VERSION ""

NS_ :

BS_:

BU_: TESTECU BIANSUXIANG SCR EBSECU DisPlay EngineECU

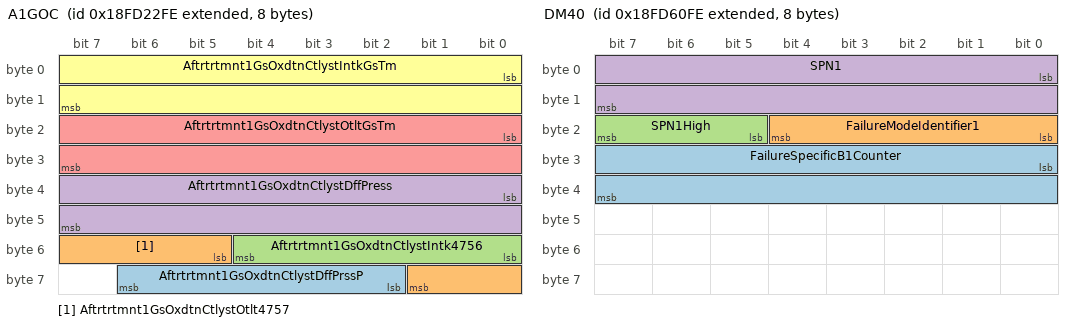
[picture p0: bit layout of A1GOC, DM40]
BO_ 2566726398 A1GOC: 8 Vector__XXX
 SG_ Aftrtrtmnt1GsOxdtnCtlystDffPrssP : 58|5@1+ (1,0) [0|31] "" Vector__XXX
 SG_ Aftrtrtmnt1GsOxdtnCtlystOtlt4757 : 53|5@1+ (1,0) [0|31] "" Vector__XXX
 SG_ Aftrtrtmnt1GsOxdtnCtlystIntk4756 : 48|5@1+ (1,0) [0|31] "" Vector__XXX
 SG_ Aftrtrtmnt1GsOxdtnCtlystDffPress : 32|16@1+ (0.1,0) [0|6425.5] "kPa" Vector__XXX
 SG_ Aftrtrtmnt1GsOxdtnCtlystOtltGsTm : 16|16@1+ (0.03125,-273) [-273|1734.96875] "deg C" Vector__XXX
 SG_ Aftrtrtmnt1GsOxdtnCtlystIntkGsTm : 0|16@1+ (0.03125,-273) [-273|1734.96875] "deg C" Vector__XXX

BO_ 2566742270 DM40: 8 Vector__XXX
 SG_ FailureSpecificB1Counter : 24|16@1+ (0.1,0) [0|6425.5] "hr" Vector__XXX
 SG_ FailureModeIdentifier1 : 16|5@1+ (1,0) [0|0] "" Vector__XXX
 SG_ SPN1High : 21|3@1+ (1,0) [0|7] "" Vector__XXX
 SG_ SPN1 : 0|16@1+ (1,0) [0|65536] "" Vector__XXX

BO_ 2566742526 DM39: 8 Vector__XXX
 SG_ SysGreatestB1Counter : 32|16@1+ (0.1,0) [0|6425.5] "hr" Vector__XXX
 SG_ SysCumulativeContinuousMITime : 0|32@1+ (0.05,0) [0|210554060.75] "hr" Vector__XXX

BO_ 2566742782 DM38: 8 Vector__XXX
 SG_ RegulationDescription : 0|8@1+ (1,0) [0|255] "" Vector__XXX

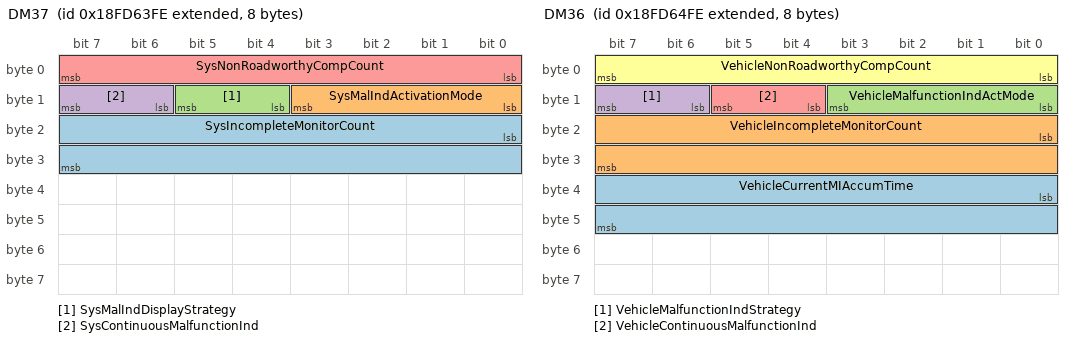
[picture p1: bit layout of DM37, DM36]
BO_ 2566743038 DM37: 8 Vector__XXX
 SG_ SysIncompleteMonitorCount : 16|16@1+ (1,0) [0|64512] "" Vector__XXX
 SG_ SysMalIndActivationMode : 8|4@1+ (1,0) [0|15] "" Vector__XXX
 SG_ SysMalIndDisplayStrategy : 12|2@1+ (1,0) [0|3] "" Vector__XXX
 SG_ SysContinuousMalfunctionInd : 14|2@1+ (1,0) [0|3] "" Vector__XXX
 SG_ SysNonRoadworthyCompCount : 0|8@1+ (1,0) [0|250] "" Vector__XXX

BO_ 2566743294 DM36: 8 Vector__XXX
 SG_ VehicleCurrentMIAccumTime : 32|16@1+ (1,0) [0|64255] "min" Vector__XXX
 SG_ VehicleIncompleteMonitorCount : 16|16@1+ (1,0) [0|64255] "" Vector__XXX
 SG_ VehicleMalfunctionIndActMode : 8|4@1+ (1,0) [0|15] "" Vector__XXX
 SG_ VehicleMalfunctionIndStrategy : 14|2@1+ (1,0) [0|3] "" Vector__XXX
 SG_ VehicleContinuousMalfunctionInd : 12|2@1+ (1,0) [0|3] "" Vector__XXX
 SG_ VehicleNonRoadworthyCompCount : 0|8@1+ (1,0) [0|250] "" Vector__XXX

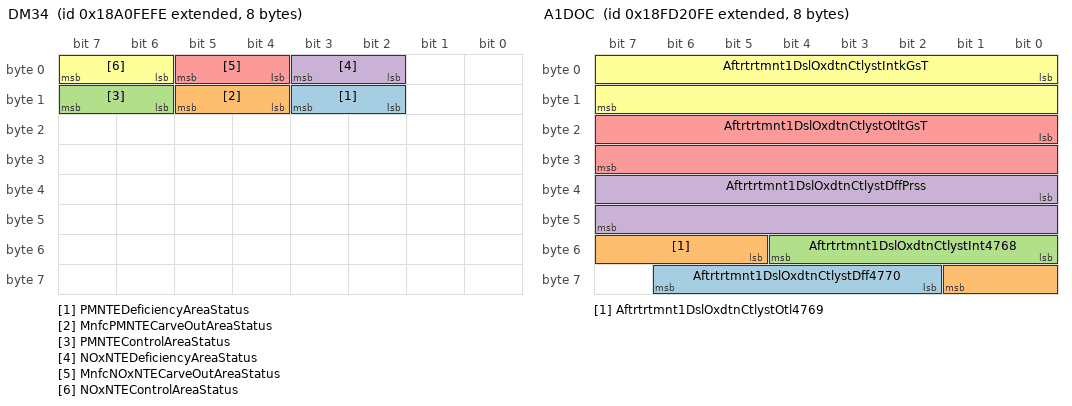
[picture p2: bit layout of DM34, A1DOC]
BO_ 2560687870 DM34: 8 Vector__XXX
 SG_ PMNTEDeficiencyAreaStatus : 10|2@1+ (1,0) [0|3] "" Vector__XXX
 SG_ MnfcPMNTECarveOutAreaStatus : 12|2@1+ (1,0) [0|3] "" Vector__XXX
 SG_ PMNTEControlAreaStatus : 14|2@1+ (1,0) [0|3] "" Vector__XXX
 SG_ NOxNTEDeficiencyAreaStatus : 2|2@1+ (1,0) [0|3] "" Vector__XXX
 SG_ MnfcNOxNTECarveOutAreaStatus : 4|2@1+ (1,0) [0|3] "" Vector__XXX
 SG_ NOxNTEControlAreaStatus : 6|2@1+ (1,0) [0|3] "" Vector__XXX

BO_ 2292317950 DM33: 9 Vector__XXX
 SG_ AECDEngineHours1Timer2 : 40|32@1+ (1,0) [0|4294967295] "min" Vector__XXX
 SG_ AECDEngineHours1Timer1 : 8|32@1+ (1,0) [0|4294967295] "min" Vector__XXX
 SG_ AECDNumber1 : 0|8@1+ (1,0) [0|250] "" Vector__XXX

BO_ 2566809342 BM: 8 Vector__XXX
 SG_ BatteryMainSwitchHoldState : 0|2@1+ (1,0) [0|3] "" Vector__XXX

BO_ 2365446910 BJM3: 8 Vector__XXX
 SG_ Joystick3XAxisDetentPosStatus : 38|2@1+ (1,0) [0|3] "" Vector__XXX
 SG_ Joystick3Button9PressedStatus : 62|2@1+ (1,0) [0|3] "" Vector__XXX
 SG_ Joystick3Button10PressedStatus : 60|2@1+ (1,0) [0|3] "" Vector__XXX
 SG_ Joystick3Button11PressedStatus : 58|2@1+ (1,0) [0|3] "" Vector__XXX
 SG_ Joystick3Button12PressedStatus : 56|2@1+ (1,0) [0|3] "" Vector__XXX
 SG_ Joystick3YAxisDetentPosStatus : 36|2@1+ (1,0) [0|3] "" Vector__XXX
 SG_ Joystick3YAxisPos : 22|10@1+ (0.1,0) [0|102] "%" Vector__XXX
 SG_ Jystck3YAxsLvrFrwrdPstvPosStatus : 20|2@1+ (1,0) [0|3] "" Vector__XXX
 SG_ Jystck3YAxsLvrBckNgtivePosStatus : 18|2@1+ (1,0) [0|3] "" Vector__XXX
 SG_ Joystick3YAxisNeutralPosStatus : 16|2@1+ (1,0) [0|3] "" Vector__XXX
 SG_ Joystick3XAxisPos : 6|10@1+ (0.1,0) [0|102] "%" Vector__XXX
 SG_ Jystck3XAxsLvrRghtPstvePosStatus : 4|2@1+ (1,0) [0|3] "" Vector__XXX
 SG_ Jystck3XAxsLvrLftNgtivePosStatus : 2|2@1+ (1,0) [0|3] "" Vector__XXX
 SG_ Joystick3XAxisNeutralPosStatus : 0|2@1+ (1,0) [0|3] "" Vector__XXX
 SG_ Joystick3Button5PressedStatus : 54|2@1+ (1,0) [0|3] "" Vector__XXX
 SG_ Joystick3Button6PressedStatus : 52|2@1+ (1,0) [0|3] "" Vector__XXX
 SG_ Joystick3Button7PressedStatus : 50|2@1+ (1,0) [0|3] "" Vector__XXX
 SG_ Joystick3Button8PressedStatus : 48|2@1+ (1,0) [0|3] "" Vector__XXX
 SG_ Joystick3Button1PressedStatus : 46|2@1+ (1,0) [0|3] "" Vector__XXX
 SG_ Joystick3Button2PressedStatus : 44|2@1+ (1,0) [0|3] "" Vector__XXX
 SG_ Joystick3Button3PressedStatus : 42|2@1+ (1,0) [0|3] "" Vector__XXX
 SG_ Joystick3Button4PressedStatus : 40|2@1+ (1,0) [0|3] "" Vector__XXX

BO_ 2365446398 BJM2: 8 Vector__XXX
 SG_ Joystick2XAxisDetentPosStatus : 38|2@1+ (1,0) [0|3] "" Vector__XXX
 SG_ Joystick2YAxisDetentPosStatus : 36|2@1+ (1,0) [0|3] "" Vector__XXX
 SG_ Joystick2YAxisPos : 22|10@1+ (0.1,0) [0|102] "%" Vector__XXX
 SG_ Jystck2YAxsLvrFrwrdPstvPosStatus : 20|2@1+ (1,0) [0|3] "" Vector__XXX
 SG_ Jystck2YAxsLvrBckNgtivePosStatus : 18|2@1+ (1,0) [0|3] "" Vector__XXX
 SG_ Joystick2YAxisNeutralPosStatus : 16|2@1+ (1,0) [0|3] "" Vector__XXX
 SG_ Joystick2XAxisPos : 6|10@1+ (0.1,0) [0|102] "%" Vector__XXX
 SG_ Jystck2XAxsLvrRghtPstvePosStatus : 4|2@1+ (1,0) [0|3] "" Vector__XXX
 SG_ Jystck2XAxsLvrLftNgtivePosStatus : 2|2@1+ (1,0) [0|3] "" Vector__XXX
 SG_ Joystick2XAxisNeutralPosStatus : 0|2@1+ (1,0) [0|3] "" Vector__XXX
 SG_ Joystick2Button9PressedStatus : 62|2@1+ (1,0) [0|3] "" Vector__XXX
 SG_ Joystick2Button10PressedStatus : 60|2@1+ (1,0) [0|3] "" Vector__XXX
 SG_ Joystick2Button11PressedStatus : 58|2@1+ (1,0) [0|3] "" Vector__XXX
 SG_ Joystick2Button12PressedStatus : 56|2@1+ (1,0) [0|3] "" Vector__XXX
 SG_ Joystick2Button5PressedStatus : 54|2@1+ (1,0) [0|3] "" Vector__XXX
 SG_ Joystick2Button6PressedStatus : 52|2@1+ (1,0) [0|3] "" Vector__XXX
 SG_ Joystick2Button7PressedStatus : 50|2@1+ (1,0) [0|3] "" Vector__XXX
 SG_ Joystick2Button8PressedStatus : 48|2@1+ (1,0) [0|3] "" Vector__XXX
 SG_ Joystick2Button1PressedStatus : 46|2@1+ (1,0) [0|3] "" Vector__XXX
 SG_ Joystick2Button2PressedStatus : 44|2@1+ (1,0) [0|3] "" Vector__XXX
 SG_ Joystick2Button3PressedStatus : 42|2@1+ (1,0) [0|3] "" Vector__XXX
 SG_ Joystick2Button4PressedStatus : 40|2@1+ (1,0) [0|3] "" Vector__XXX

BO_ 2365445886 BJM1: 8 Vector__XXX
 SG_ Joystick1XAxisDetentPosStatus : 38|2@1+ (1,0) [0|3] "" Vector__XXX
 SG_ Joystick1YAxisDetentPosStatus : 36|2@1+ (1,0) [0|3] "" Vector__XXX
 SG_ Joystick1YAxisPos : 22|10@1+ (0.1,0) [0|102] "%" Vector__XXX
 SG_ Jystck1YAxsLvrFrwrdPstvPosStatus : 20|2@1+ (1,0) [0|3] "" Vector__XXX
 SG_ Jystck1YAxsLvrBckNgtivePosStatus : 18|2@1+ (1,0) [0|3] "" Vector__XXX
 SG_ Joystick1YAxisNeutralPosStatus : 16|2@1+ (1,0) [0|3] "" Vector__XXX
 SG_ Joystick1XAxisPos : 6|10@1+ (0.1,0) [0|102] "%" Vector__XXX
 SG_ Joystick1Button9PressedStatus : 62|2@1+ (1,0) [0|3] "" Vector__XXX
 SG_ Joystick1Button10PressedStatus : 60|2@1+ (1,0) [0|3] "" Vector__XXX
 SG_ Joystick1Button11PressedStatus : 58|2@1+ (1,0) [0|3] "" Vector__XXX
 SG_ Joystick1Button12PressedStatus : 56|2@1+ (1,0) [0|3] "" Vector__XXX
 SG_ Joystick1Button5PressedStatus : 54|2@1+ (1,0) [0|3] "" Vector__XXX
 SG_ Joystick1Button6PressedStatus : 52|2@1+ (1,0) [0|3] "" Vector__XXX
 SG_ Joystick1Button7PressedStatus : 50|2@1+ (1,0) [0|3] "" Vector__XXX
 SG_ Joystick1Button8PressedStatus : 48|2@1+ (1,0) [0|3] "" Vector__XXX
 SG_ Joystick1Button1PressedStatus : 46|2@1+ (1,0) [0|3] "" Vector__XXX
 SG_ Joystick1Button2PressedStatus : 44|2@1+ (1,0) [0|3] "" Vector__XXX
 SG_ Joystick1Button3PressedStatus : 42|2@1+ (1,0) [0|3] "" Vector__XXX
 SG_ Joystick1Button4PressedStatus : 40|2@1+ (1,0) [0|3] "" Vector__XXX
 SG_ Jystck1XAxsLvrRghtPstvePosStatus : 4|2@1+ (1,0) [0|3] "" Vector__XXX
 SG_ Jystck1XAxsLvrLftNgtivePosStatus : 2|2@1+ (1,0) [0|3] "" Vector__XXX
 SG_ Joystick1XAxisNeutralPosStatus : 0|2@1+ (1,0) [0|3] "" Vector__XXX

BO_ 2566847230 B: 8 Vector__XXX
 SG_ ParkingBrakeRedWarningSignal : 26|2@1+ (1,0) [0|3] "" Vector__XXX
 SG_ ParkBrakeReleaseInhibitStatus : 28|2@1+ (1,0) [0|3] "" Vector__XXX
 SG_ ParkingBrakeActuator : 24|2@1+ (1,0) [0|3] "" Vector__XXX
 SG_ BrakeSecondPress : 16|8@1+ (4,0) [0|1000] "kPa" Vector__XXX
 SG_ BrakePrimaryPress : 8|8@1+ (4,0) [0|1000] "kPa" Vector__XXX
 SG_ BrakeAppPress : 0|8@1+ (4,0) [0|1000] "kPa" Vector__XXX

BO_ 2566848254 AWPP: 8 Vector__XXX
 SG_ AuxPumpPress : 0|8@1+ (16,0) [0|4000] "kPa" Vector__XXX

BO_ 2566725886 A1DOC: 8 Vector__XXX
 SG_ Aftrtrtmnt1DslOxdtnCtlystDff4770 : 58|5@1+ (1,0) [0|31] "" Vector__XXX
 SG_ Aftrtrtmnt1DslOxdtnCtlystOtl4769 : 53|5@1+ (1,0) [0|31] "" Vector__XXX
 SG_ Aftrtrtmnt1DslOxdtnCtlystInt4768 : 48|5@1+ (1,0) [0|31] "" Vector__XXX
 SG_ Aftrtrtmnt1DslOxdtnCtlystDffPrss : 32|16@1+ (0.1,0) [0|6425.5] "kPa" Vector__XXX
 SG_ Aftrtrtmnt1DslOxdtnCtlystOtltGsT : 16|16@1+ (0.03125,-273) [-273|1734.96875] "deg C" Vector__XXX
 SG_ Aftrtrtmnt1DslOxdtnCtlystIntkGsT : 0|16@1+ (0.03125,-273) [-273|1734.96875] "deg C" Vector__XXX

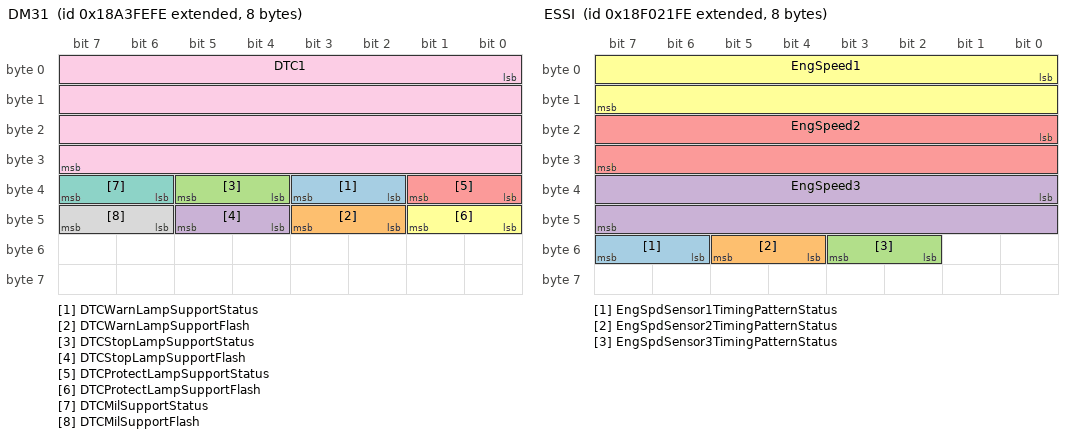
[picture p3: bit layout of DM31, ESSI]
BO_ 2560884478 DM31: 8 Vector__XXX
 SG_ DTCWarnLampSupportStatus : 34|2@1+ (1,0) [0|3] "" Vector__XXX
 SG_ DTCWarnLampSupportFlash : 42|2@1+ (1,0) [0|3] "" Vector__XXX
 SG_ DTCStopLampSupportStatus : 36|2@1+ (1,0) [0|3] "" Vector__XXX
 SG_ DTCStopLampSupportFlash : 44|2@1+ (1,0) [0|3] "" Vector__XXX
 SG_ DTCProtectLampSupportStatus : 32|2@1+ (1,0) [0|3] "" Vector__XXX
 SG_ DTCProtectLampSupportFlash : 40|2@1+ (1,0) [0|3] "" Vector__XXX
 SG_ DTCMilSupportStatus : 38|2@1+ (1,0) [0|3] "" Vector__XXX
 SG_ DTCMilSupportFlash : 46|2@1+ (1,0) [0|3] "" Vector__XXX
 SG_ DTC1 : 0|32@1+ (1,0) [0|4294967295] "" Vector__XXX

BO_ 2633844734 TML: 8 Vector__XXX

BO_ 2560360190 PMI: 8 Vector__XXX
 SG_ DataDictionaryMethod : 11|21@1+ (1,0) [0|2097151] "" Vector__XXX
 SG_ DataDictionaryManufacturerCode : 0|11@1+ (1,0) [0|2047] "" Vector__XXX

BO_ 2566736126 O2FT2: 8 Vector__XXX
 SG_ EngExhstGsOxygnSnsrClsdLpOprtnBn : 32|4@1+ (1,0) [0|15] "" Vector__XXX
 SG_ ShorttermFuelTrimBank2 : 16|16@1+ (0.1,-100) [-100|100] "%" Vector__XXX
 SG_ LongtermFuelTrimBank2 : 0|16@1+ (0.1,-100) [-100|100] "%" Vector__XXX

BO_ 2566736382 O2FT1: 8 Vector__XXX
 SG_ EngExhstGsOxygnSnsrClsdLpOprtnBn : 32|4@1+ (1,0) [0|15] "" Vector__XXX
 SG_ ShorttermFuelTrimBank1 : 16|16@1+ (0.1,-100) [-100|100] "%" Vector__XXX
 SG_ LongtermFuelTrimBank1 : 0|16@1+ (0.1,-100) [-100|100] "%" Vector__XXX

BO_ 2565874174 ESSI: 8 Vector__XXX
 SG_ EngSpdSensor1TimingPatternStatus : 54|2@1+ (1,0) [0|3] "" Vector__XXX
 SG_ EngSpdSensor2TimingPatternStatus : 52|2@1+ (1,0) [0|3] "" Vector__XXX
 SG_ EngSpdSensor3TimingPatternStatus : 50|2@1+ (1,0) [0|3] "" Vector__XXX
 SG_ EngSpeed3 : 32|16@1+ (0.5,0) [0|32127.5] "rpm" Vector__XXX
 SG_ EngSpeed2 : 16|16@1+ (0.5,0) [0|32127.5] "rpm" Vector__XXX
 SG_ EngSpeed1 : 0|16@1+ (0.5,0) [0|32127.5] "rpm" Vector__XXX

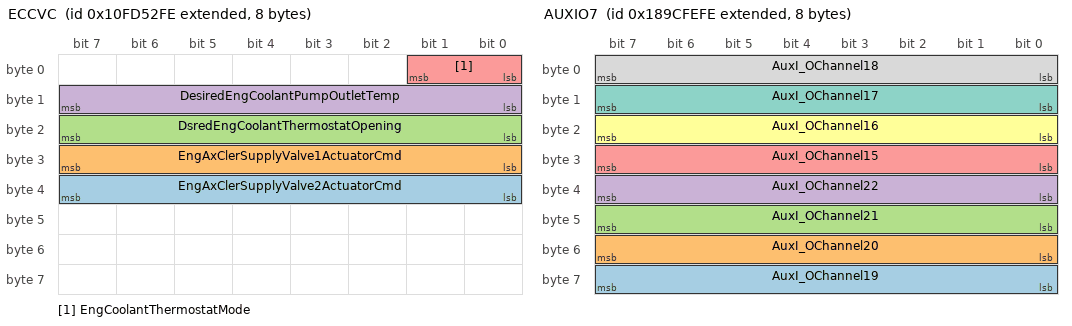
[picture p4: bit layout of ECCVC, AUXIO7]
BO_ 2432520958 ECCVC: 8 Vector__XXX
 SG_ EngAxClerSupplyValve2ActuatorCmd : 32|8@1+ (0.4,0) [0|100] "%" Vector__XXX
 SG_ EngAxClerSupplyValve1ActuatorCmd : 24|8@1+ (0.4,0) [0|100] "%" Vector__XXX
 SG_ DsredEngCoolantThermostatOpening : 16|8@1+ (0.4,0) [0|100] "%" Vector__XXX
 SG_ DesiredEngCoolantPumpOutletTemp : 8|8@1+ (1,-40) [-40|210] "deg C" Vector__XXX
 SG_ EngCoolantThermostatMode : 0|2@1+ (1,0) [0|3] "" Vector__XXX

BO_ 2560425726 AUXIO7: 8 Vector__XXX
 SG_ AuxI_OChannel19 : 56|8@1+ (1,0) [0|250] "" Vector__XXX
 SG_ AuxI_OChannel20 : 48|8@1+ (1,0) [0|250] "" Vector__XXX
 SG_ AuxI_OChannel21 : 40|8@1+ (1,0) [0|250] "" Vector__XXX
 SG_ AuxI_OChannel22 : 32|8@1+ (1,0) [0|250] "" Vector__XXX
 SG_ AuxI_OChannel15 : 24|8@1+ (1,0) [0|250] "" Vector__XXX
 SG_ AuxI_OChannel16 : 16|8@1+ (1,0) [0|250] "" Vector__XXX
 SG_ AuxI_OChannel17 : 8|8@1+ (1,0) [0|250] "" Vector__XXX
 SG_ AuxI_OChannel18 : 0|8@1+ (1,0) [0|250] "" Vector__XXX

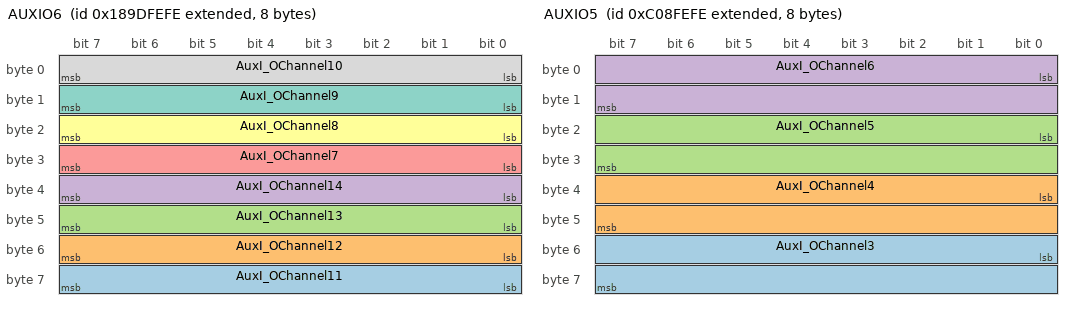
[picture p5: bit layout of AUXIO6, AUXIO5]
BO_ 2560491262 AUXIO6: 8 Vector__XXX
 SG_ AuxI_OChannel11 : 56|8@1+ (1,0) [0|250] "" Vector__XXX
 SG_ AuxI_OChannel12 : 48|8@1+ (1,0) [0|250] "" Vector__XXX
 SG_ AuxI_OChannel13 : 40|8@1+ (1,0) [0|250] "" Vector__XXX
 SG_ AuxI_OChannel14 : 32|8@1+ (1,0) [0|250] "" Vector__XXX
 SG_ AuxI_OChannel7 : 24|8@1+ (1,0) [0|250] "" Vector__XXX
 SG_ AuxI_OChannel8 : 16|8@1+ (1,0) [0|250] "" Vector__XXX
 SG_ AuxI_OChannel9 : 8|8@1+ (1,0) [0|250] "" Vector__XXX
 SG_ AuxI_OChannel10 : 0|8@1+ (1,0) [0|250] "" Vector__XXX

BO_ 2349399806 AUXIO5: 8 Vector__XXX
 SG_ AuxI_OChannel3 : 48|16@1+ (1,0) [0|64255] "" Vector__XXX
 SG_ AuxI_OChannel4 : 32|16@1+ (1,0) [0|64255] "" Vector__XXX
 SG_ AuxI_OChannel5 : 16|16@1+ (1,0) [0|64255] "" Vector__XXX
 SG_ AuxI_OChannel6 : 0|16@1+ (1,0) [0|64255] "" Vector__XXX

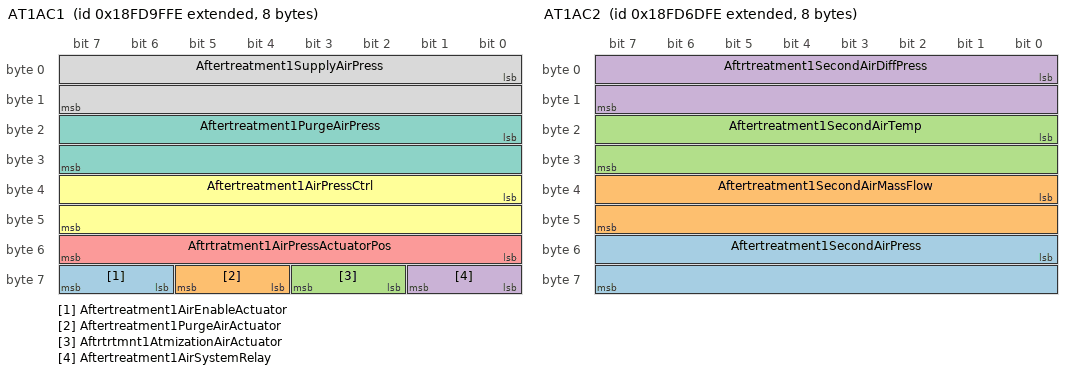
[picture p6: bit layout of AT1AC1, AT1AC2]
BO_ 2566758398 AT1AC1: 8 Vector__XXX
 SG_ Aftertreatment1AirEnableActuator : 62|2@1+ (1,0) [0|3] "" Vector__XXX
 SG_ Aftertreatment1PurgeAirActuator : 60|2@1+ (1,0) [0|3] "" Vector__XXX
 SG_ Aftrtrtmnt1AtmizationAirActuator : 58|2@1+ (1,0) [0|3] "" Vector__XXX
 SG_ Aftertreatment1AirSystemRelay : 56|2@1+ (1,0) [0|3] "" Vector__XXX
 SG_ Aftrtratment1AirPressActuatorPos : 48|8@1+ (0.4,0) [0|100] "%" Vector__XXX
 SG_ Aftertreatment1AirPressCtrl : 32|16@1+ (0.0025,0) [0|160.6375] "%" Vector__XXX
 SG_ Aftertreatment1PurgeAirPress : 16|16@1+ (0.1,0) [0|6425.5] "kPa" Vector__XXX
 SG_ Aftertreatment1SupplyAirPress : 0|16@1+ (0.1,0) [0|6425.5] "kPa" Vector__XXX

BO_ 2566745598 AT1AC2: 8 Vector__XXX
 SG_ Aftertreatment1SecondAirPress : 48|16@1+ (0.1,0) [0|6425.5] "kPa" Vector__XXX
 SG_ Aftertreatment1SecondAirMassFlow : 32|16@1+ (0.2,0) [0|12851] "kg/h per bit" Vector__XXX
 SG_ Aftertreatment1SecondAirTemp : 16|16@1+ (0.03125,-273) [-273|1734.96875] "deg C" Vector__XXX
 SG_ Aftrtreatment1SecondAirDiffPress : 0|16@1+ (0.0078125,-250) [-250|251.99] "kPa" Vector__XXX

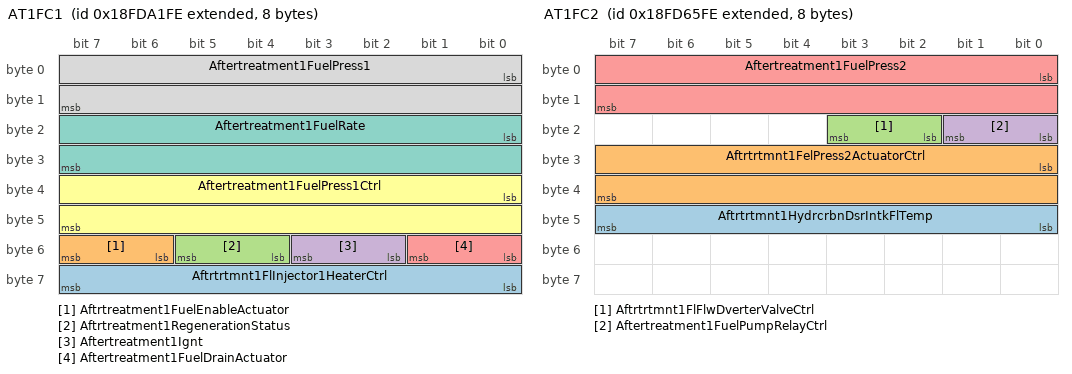
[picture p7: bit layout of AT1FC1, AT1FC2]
BO_ 2566758910 AT1FC1: 8 Vector__XXX
 SG_ Aftrtrtmnt1FlInjector1HeaterCtrl : 56|8@1+ (0.4,0) [0|100] "%" Vector__XXX
 SG_ Aftrtreatment1FuelEnableActuator : 54|2@1+ (1,0) [0|3] "" Vector__XXX
 SG_ Aftrtreatment1RegenerationStatus : 52|2@1+ (1,0) [0|3] "" Vector__XXX
 SG_ Aftertreatment1Ignt : 50|2@1+ (1,0) [0|3] "" Vector__XXX
 SG_ Aftertreatment1FuelDrainActuator : 48|2@1+ (1,0) [0|3] "" Vector__XXX
 SG_ Aftertreatment1FuelPress1Ctrl : 32|16@1+ (0.0025,0) [0|160.6375] "%" Vector__XXX
 SG_ Aftertreatment1FuelRate : 16|16@1+ (0.05,0) [0|3212.75] "L/h" Vector__XXX
 SG_ Aftertreatment1FuelPress1 : 0|16@1+ (0.1,0) [0|6425.5] "kPa" Vector__XXX

BO_ 2566743550 AT1FC2: 8 Vector__XXX
 SG_ Aftrtrtmnt1HydrcrbnDsrIntkFlTemp : 40|8@1+ (1,-40) [-40|210] "deg C" Vector__XXX
 SG_ Aftrtrtmnt1FelPress2ActuatorCtrl : 24|16@1+ (0.0025,0) [0|160.6375] "%" Vector__XXX
 SG_ Aftrtrtmnt1FlFlwDverterValveCtrl : 18|2@1+ (1,0) [0|3] "" Vector__XXX
 SG_ Aftertreatment1FuelPumpRelayCtrl : 16|2@1+ (1,0) [0|3] "" Vector__XXX
 SG_ Aftertreatment1FuelPress2 : 0|16@1+ (0.1,0) [0|6425.5] "kPa" Vector__XXX

BO_ 2566753534 AT1GP: 8 Vector__XXX
 SG_ DslParticulateFilterOutletPress1 : 16|16@1+ (0.1,0) [0|6425.5] "kPa" Vector__XXX
 SG_ DslParticulateFilterIntakePress1 : 0|16@1+ (0.1,0) [0|6425.5] "kPa" Vector__XXX

BO_ 2566756606 AT1HI: 8 Vector__XXX
 SG_ Aftrtrtmnt1AvrgDstncBtwnActvDPFR : 288|32@1+ (0.125,0) [0|526385151.9] "km" Vector__XXX
 SG_ Aftrtrtmnt1AvrgTmBtwnActvRgnrtns : 256|32@1+ (1,0) [0|4211081215] "s" Vector__XXX
 SG_ Aftrtrtmnt1DslPrtcltFltrTtlN3728 : 224|32@1+ (1,0) [0|4211081215] "" Vector__XXX
 SG_ Aftrtrtmnt1DslPrtcltFltrTtlN3727 : 192|32@1+ (1,0) [0|4211081215] "" Vector__XXX
 SG_ Aftrtrtmnt1DslPrtcltFltrTtlNmbrO : 160|32@1+ (1,0) [0|4211081215] "" Vector__XXX
 SG_ Aftrtrtmnt1DslPrtcltFltrTtlPssvR : 128|32@1+ (1,0) [0|4211081215] "s" Vector__XXX
 SG_ Aftrtrtmnt1TtlNmbrOfActvRgnrtons : 96|32@1+ (1,0) [0|4211081215] "" Vector__XXX
 SG_ Aftertreatment1TotalDisabledTime : 64|32@1+ (1,0) [0|4211081215] "s" Vector__XXX
 SG_ Aftrtrtmnt1TotalRegenerationTime : 32|32@1+ (1,0) [0|4211081215] "s" Vector__XXX
 SG_ Aftertreatment1TotalFuelUsed : 0|32@1+ (0.5,0) [0|2105540607.5] "L" Vector__XXX

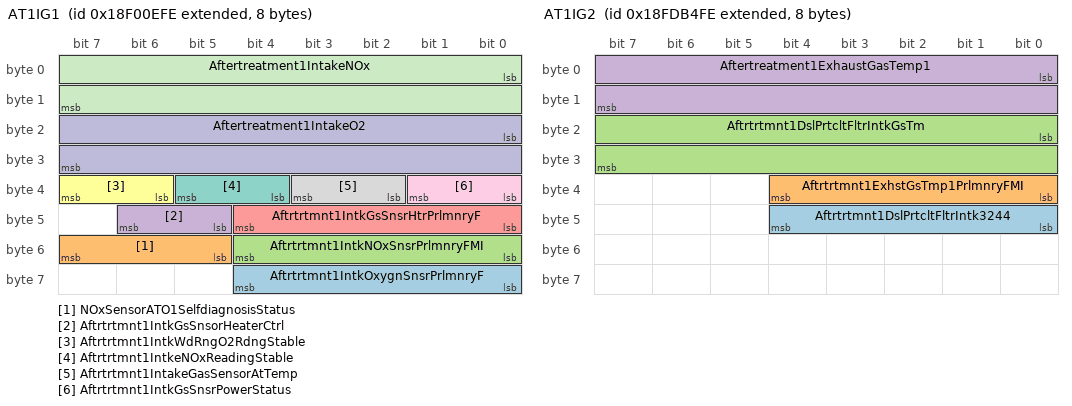
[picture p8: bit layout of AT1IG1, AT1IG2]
BO_ 2565869310 AT1IG1: 8 Vector__XXX
 SG_ Aftrtrtmnt1IntkOxygnSnsrPrlmnryF : 56|5@1+ (1,0) [0|31] "" Vector__XXX
 SG_ NOxSensorATO1SelfdiagnosisStatus : 53|3@1+ (1,0) [0|7] "" Vector__XXX
 SG_ Aftrtrtmnt1IntkNOxSnsrPrlmnryFMI : 48|5@1+ (1,0) [0|31] "" Vector__XXX
 SG_ Aftrtrtmnt1IntkGsSnsorHeaterCtrl : 45|2@1+ (1,0) [0|3] "" Vector__XXX
 SG_ Aftrtrtmnt1IntkGsSnsrHtrPrlmnryF : 40|5@1+ (1,0) [0|31] "" Vector__XXX
 SG_ Aftrtrtmnt1IntkWdRngO2RdngStable : 38|2@1+ (1,0) [0|3] "" Vector__XXX
 SG_ Aftrtrtmnt1IntkeNOxReadingStable : 36|2@1+ (1,0) [0|3] "" Vector__XXX
 SG_ Aftrtrtmnt1IntakeGasSensorAtTemp : 34|2@1+ (1,0) [0|3] "" Vector__XXX
 SG_ Aftrtrtmnt1IntkGsSnsrPowerStatus : 32|2@1+ (1,0) [0|3] "" Vector__XXX
 SG_ Aftertreatment1IntakeO2 : 16|16@1+ (0.000514,-12) [-12|21] "%" Vector__XXX
 SG_ Aftertreatment1IntakeNOx : 0|16@1+ (0.05,-200) [-200|3012.75] "ppm" Vector__XXX

BO_ 2566763774 AT1IG2: 8 Vector__XXX
 SG_ Aftrtrtmnt1DslPrtcltFltrIntk3244 : 40|5@1+ (1,0) [0|31] "" Vector__XXX
 SG_ Aftrtrtmnt1ExhstGsTmp1PrlmnryFMI : 32|5@1+ (1,0) [0|31] "" Vector__XXX
 SG_ Aftrtrtmnt1DslPrtcltFltrIntkGsTm : 16|16@1+ (0.03125,-273) [-273|1734.96875] "deg C" Vector__XXX
 SG_ Aftertreatment1ExhaustGasTemp1 : 0|16@1+ (0.03125,-273) [-273|1734.96875] "deg C" Vector__XXX

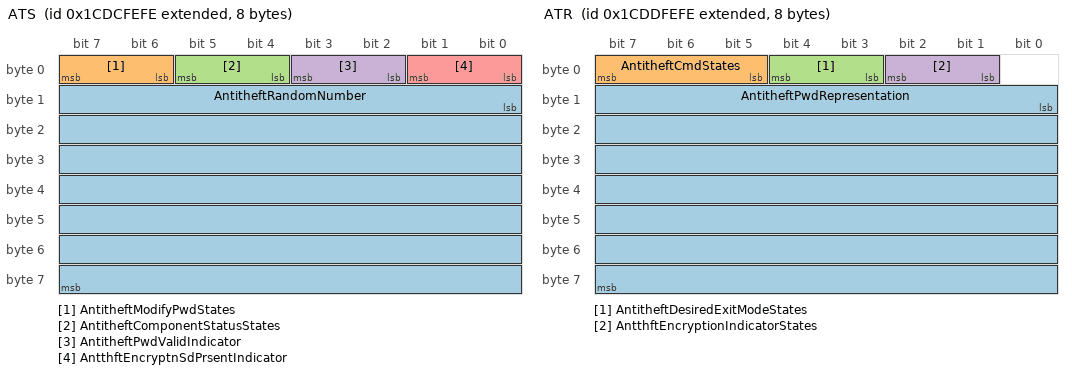
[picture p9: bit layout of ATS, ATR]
BO_ 2631728894 ATS: 8 Vector__XXX
 SG_ AntitheftRandomNumber : 8|56@1+ (1,0) [0|255] "per byte" Vector__XXX
 SG_ AntitheftModifyPwdStates : 6|2@1+ (1,0) [0|3] "" Vector__XXX
 SG_ AntitheftComponentStatusStates : 4|2@1+ (1,0) [0|3] "" Vector__XXX
 SG_ AntitheftPwdValidIndicator : 2|2@1+ (1,0) [0|3] "" Vector__XXX
 SG_ AntthftEncryptnSdPrsentIndicator : 0|2@1+ (1,0) [0|3] "" Vector__XXX

BO_ 2631794430 ATR: 8 Vector__XXX
 SG_ AntitheftPwdRepresentation : 8|56@1+ (1,0) [0|255] "per byte" Vector__XXX
 SG_ AntitheftCmdStates : 5|3@1+ (1,0) [0|7] "" Vector__XXX
 SG_ AntitheftDesiredExitModeStates : 3|2@1+ (1,0) [0|3] "" Vector__XXX
 SG_ AntthftEncryptionIndicatorStates : 1|2@1+ (1,0) [0|3] "" Vector__XXX

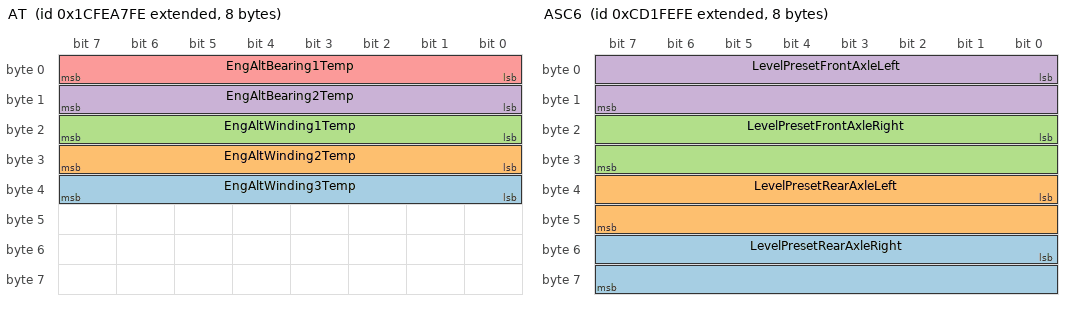
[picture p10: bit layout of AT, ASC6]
BO_ 2633934846 AT: 8 Vector__XXX
 SG_ EngAltWinding3Temp : 32|8@1+ (1,-40) [-40|210] "deg C" Vector__XXX
 SG_ EngAltWinding2Temp : 24|8@1+ (1,-40) [-40|210] "deg C" Vector__XXX
 SG_ EngAltWinding1Temp : 16|8@1+ (1,-40) [-40|210] "deg C" Vector__XXX
 SG_ EngAltBearing2Temp : 8|8@1+ (1,-40) [-40|210] "deg C" Vector__XXX
 SG_ EngAltBearing1Temp : 0|8@1+ (1,-40) [-40|210] "deg C" Vector__XXX

BO_ 2362572542 ASC6: 8 Vector__XXX
 SG_ LevelPresetRearAxleRight : 48|16@1+ (0.1,-3200) [-3200|3225.5] "mm" Vector__XXX
 SG_ LevelPresetRearAxleLeft : 32|16@1+ (0.1,-3200) [-3200|3225.5] "mm" Vector__XXX
 SG_ LevelPresetFrontAxleRight : 16|16@1+ (0.1,-3200) [-3200|3225.5] "mm" Vector__XXX
 SG_ LevelPresetFrontAxleLeft : 0|16@1+ (0.1,-3200) [-3200|3225.5] "mm" Vector__XXX

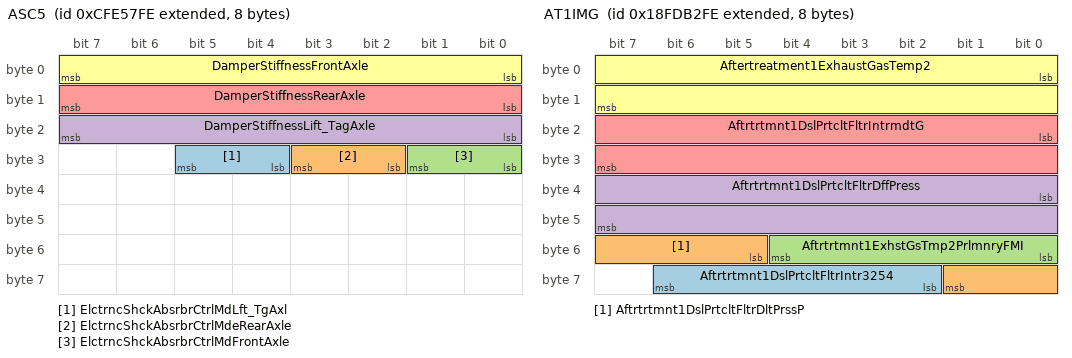
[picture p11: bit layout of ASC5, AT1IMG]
BO_ 2365478910 ASC5: 8 Vector__XXX
 SG_ ElctrncShckAbsrbrCtrlMdLft_TgAxl : 28|2@1+ (1,0) [0|3] "" Vector__XXX
 SG_ ElctrncShckAbsrbrCtrlMdeRearAxle : 26|2@1+ (1,0) [0|3] "" Vector__XXX
 SG_ ElctrncShckAbsrbrCtrlMdFrontAxle : 24|2@1+ (1,0) [0|3] "" Vector__XXX
 SG_ DamperStiffnessLift_TagAxle : 16|8@1+ (0.4,0) [0|100] "%" Vector__XXX
 SG_ DamperStiffnessRearAxle : 8|8@1+ (0.4,0) [0|100] "%" Vector__XXX
 SG_ DamperStiffnessFrontAxle : 0|8@1+ (0.4,0) [0|100] "%" Vector__XXX

BO_ 2560950014 DM30: 12 Vector__XXX
 SG_ TestLimitMinimum : 80|16@1+ (1,0) [0|64255] "" Vector__XXX
 SG_ TestLimitMaximum : 64|16@1+ (1,0) [0|64255] "" Vector__XXX
 SG_ TestValue : 48|16@1+ (1,0) [0|64255] "" Vector__XXX
 SG_ SlotId : 32|16@1+ (1,0) [0|64255] "" Vector__XXX
 SG_ TestIdentifier : 0|8@1+ (1,0) [0|255] "" Vector__XXX
 SG_ FailureModeIdentifier1 : 24|5@1+ (1,0) [0|0] "" Vector__XXX
 SG_ SPN1High : 29|3@1+ (1,0) [0|7] "" Vector__XXX
 SG_ SPN1 : 8|16@1+ (1,0) [0|65536] "" Vector__XXX

BO_ 2566763262 AT1IMG: 8 Vector__XXX
 SG_ Aftrtrtmnt1DslPrtcltFltrIntr3254 : 58|5@1+ (1,0) [0|31] "" Vector__XXX
 SG_ Aftrtrtmnt1DslPrtcltFltrDltPrssP : 53|5@1+ (1,0) [0|31] "" Vector__XXX
 SG_ Aftrtrtmnt1ExhstGsTmp2PrlmnryFMI : 48|5@1+ (1,0) [0|31] "" Vector__XXX
 SG_ Aftrtrtmnt1DslPrtcltFltrDffPress : 32|16@1+ (0.1,0) [0|6425.5] "kPa" Vector__XXX
 SG_ Aftrtrtmnt1DslPrtcltFltrIntrmdtG : 16|16@1+ (0.03125,-273) [-273|1734.96875] "deg C" Vector__XXX
 SG_ Aftertreatment1ExhaustGasTemp2 : 0|16@1+ (0.03125,-273) [-273|1734.96875] "deg C" Vector__XXX

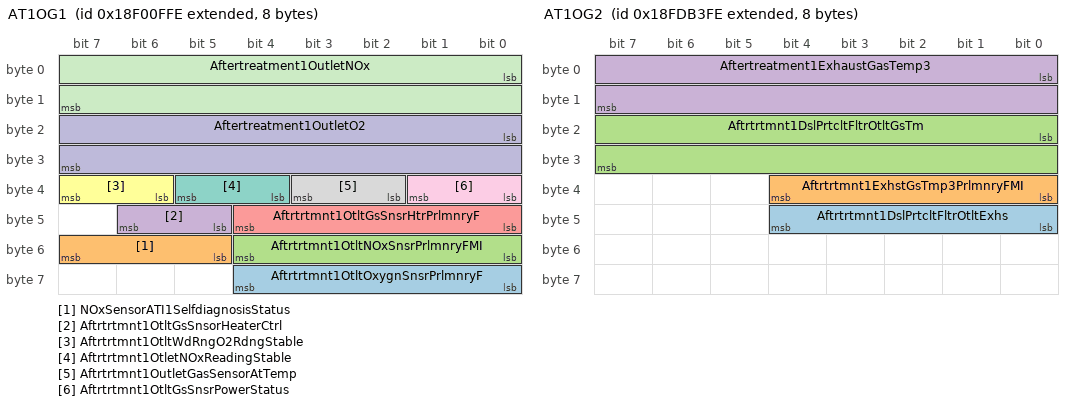
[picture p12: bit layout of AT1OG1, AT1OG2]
BO_ 2565869566 AT1OG1: 8 Vector__XXX
 SG_ Aftrtrtmnt1OtltOxygnSnsrPrlmnryF : 56|5@1+ (1,0) [0|31] "" Vector__XXX
 SG_ NOxSensorATI1SelfdiagnosisStatus : 53|3@1+ (1,0) [0|7] "" Vector__XXX
 SG_ Aftrtrtmnt1OtltNOxSnsrPrlmnryFMI : 48|5@1+ (1,0) [0|31] "" Vector__XXX
 SG_ Aftrtrtmnt1OtltGsSnsorHeaterCtrl : 45|2@1+ (1,0) [0|3] "" Vector__XXX
 SG_ Aftrtrtmnt1OtltGsSnsrHtrPrlmnryF : 40|5@1+ (1,0) [0|31] "" Vector__XXX
 SG_ Aftrtrtmnt1OtltWdRngO2RdngStable : 38|2@1+ (1,0) [0|3] "" Vector__XXX
 SG_ Aftrtrtmnt1OtletNOxReadingStable : 36|2@1+ (1,0) [0|3] "" Vector__XXX
 SG_ Aftrtrtmnt1OutletGasSensorAtTemp : 34|2@1+ (1,0) [0|3] "" Vector__XXX
 SG_ Aftrtrtmnt1OtltGsSnsrPowerStatus : 32|2@1+ (1,0) [0|3] "" Vector__XXX
 SG_ Aftertreatment1OutletO2 : 16|16@1+ (0.000514,-12) [-12|21] "%" Vector__XXX
 SG_ Aftertreatment1OutletNOx : 0|16@1+ (0.05,-200) [-200|3012.75] "ppm" Vector__XXX

BO_ 2566763518 AT1OG2: 8 Vector__XXX
 SG_ Aftrtrtmnt1DslPrtcltFltrOtltExhs : 40|5@1+ (1,0) [0|31] "" Vector__XXX
 SG_ Aftrtrtmnt1ExhstGsTmp3PrlmnryFMI : 32|5@1+ (1,0) [0|31] "" Vector__XXX
 SG_ Aftrtrtmnt1DslPrtcltFltrOtltGsTm : 16|16@1+ (0.03125,-273) [-273|1734.96875] "deg C" Vector__XXX
 SG_ Aftertreatment1ExhaustGasTemp3 : 0|16@1+ (0.03125,-273) [-273|1734.96875] "deg C" Vector__XXX

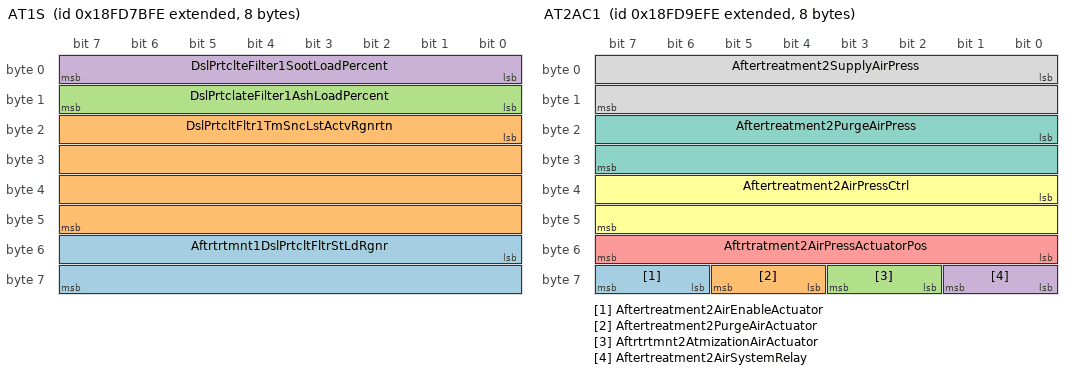
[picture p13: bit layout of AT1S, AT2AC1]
BO_ 2566749182 AT1S: 8 Vector__XXX
 SG_ Aftrtrtmnt1DslPrtcltFltrStLdRgnr : 48|16@1+ (0.0025,0) [0|160.6375] "%" Vector__XXX
 SG_ DslPrtcltFltr1TmSncLstActvRgnrtn : 16|32@1+ (1,0) [0|4211081215] "s" Vector__XXX
 SG_ DslPrtclateFilter1AshLoadPercent : 8|8@1+ (1,0) [0|250] "%" Vector__XXX
 SG_ DslPrtclteFilter1SootLoadPercent : 0|8@1+ (1,0) [0|250] "%" Vector__XXX

BO_ 2566748670 AT1TI: 32 Vector__XXX
 SG_ Aftrtrtmnt1DslPrtcltFltrTrpN3740 : 224|32@1+ (1,0) [0|4211081215] "" Vector__XXX
 SG_ Aftrtrtmnt1DslPrtcltFltrTrpN3739 : 192|32@1+ (1,0) [0|4211081215] "" Vector__XXX
 SG_ Aftrtrtmnt1DslPrtcltFltrTrpN3738 : 160|32@1+ (1,0) [0|4211081215] "" Vector__XXX
 SG_ Aftrtrtmnt1DslPrtcltFltrTrpPssvR : 128|32@1+ (1,0) [0|4211081215] "s" Vector__XXX
 SG_ Aftrtrtmnt1DslPrtcltFltrTrpNmbrO : 96|32@1+ (1,0) [0|4211081215] "" Vector__XXX
 SG_ Aftrtrtmnt1DslPrtcltFltrTrpDsbld : 64|32@1+ (1,0) [0|4211081215] "s" Vector__XXX
 SG_ Aftrtrtmnt1DslPrtcltFltrTrpActvR : 32|32@1+ (1,0) [0|4211081215] "s" Vector__XXX
 SG_ Aftrtrtmnt1DslPrtcltFltrTrpFlUsd : 0|32@1+ (0.5,0) [0|2105540607.5] "L" Vector__XXX

BO_ 2566758142 AT2AC1: 8 Vector__XXX
 SG_ Aftertreatment2AirEnableActuator : 62|2@1+ (1,0) [0|3] "" Vector__XXX
 SG_ Aftertreatment2PurgeAirActuator : 60|2@1+ (1,0) [0|3] "" Vector__XXX
 SG_ Aftrtrtmnt2AtmizationAirActuator : 58|2@1+ (1,0) [0|3] "" Vector__XXX
 SG_ Aftertreatment2AirSystemRelay : 56|2@1+ (1,0) [0|3] "" Vector__XXX
 SG_ Aftrtratment2AirPressActuatorPos : 48|8@1+ (0.4,0) [0|100] "%" Vector__XXX
 SG_ Aftertreatment2AirPressCtrl : 32|16@1+ (0.0025,0) [0|160.6375] "%" Vector__XXX
 SG_ Aftertreatment2PurgeAirPress : 16|16@1+ (0.1,0) [0|6425.5] "kPa" Vector__XXX
 SG_ Aftertreatment2SupplyAirPress : 0|16@1+ (0.1,0) [0|6425.5] "kPa" Vector__XXX

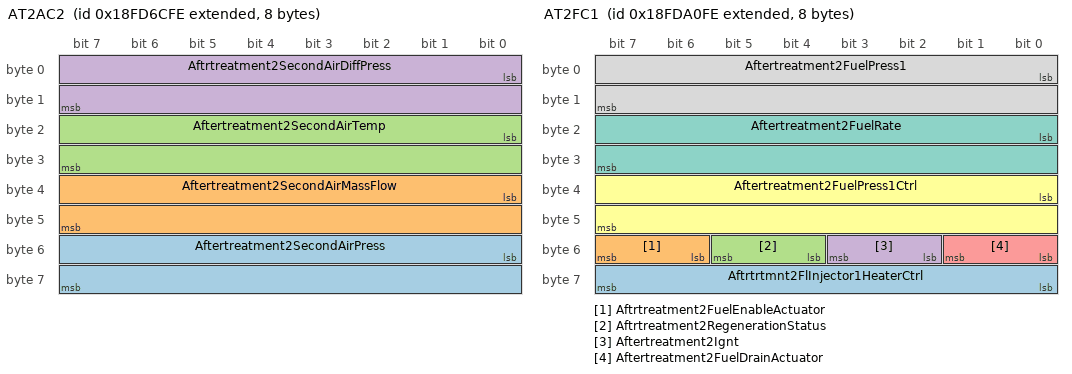
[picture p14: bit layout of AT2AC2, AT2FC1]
BO_ 2566745342 AT2AC2: 8 Vector__XXX
 SG_ Aftertreatment2SecondAirPress : 48|16@1+ (0.1,0) [0|6425.5] "kPa" Vector__XXX
 SG_ Aftertreatment2SecondAirMassFlow : 32|16@1+ (0.2,0) [0|12851] "kg/h per bit" Vector__XXX
 SG_ Aftertreatment2SecondAirTemp : 16|16@1+ (0.03125,-273) [-273|1734.96875] "deg C" Vector__XXX
 SG_ Aftrtreatment2SecondAirDiffPress : 0|16@1+ (0.0078125,-250) [-250|251.99] "kPa" Vector__XXX

BO_ 2566758654 AT2FC1: 8 Vector__XXX
 SG_ Aftrtrtmnt2FlInjector1HeaterCtrl : 56|8@1+ (0.4,0) [0|100] "%" Vector__XXX
 SG_ Aftrtreatment2FuelEnableActuator : 54|2@1+ (1,0) [0|3] "" Vector__XXX
 SG_ Aftrtreatment2RegenerationStatus : 52|2@1+ (1,0) [0|3] "" Vector__XXX
 SG_ Aftertreatment2Ignt : 50|2@1+ (1,0) [0|3] "" Vector__XXX
 SG_ Aftertreatment2FuelDrainActuator : 48|2@1+ (1,0) [0|3] "" Vector__XXX
 SG_ Aftertreatment2FuelPress1Ctrl : 32|16@1+ (0.0025,0) [0|160.6375] "%" Vector__XXX
 SG_ Aftertreatment2FuelRate : 16|16@1+ (0.05,0) [0|3212.75] "L/h" Vector__XXX
 SG_ Aftertreatment2FuelPress1 : 0|16@1+ (0.1,0) [0|6425.5] "kPa" Vector__XXX

BO_ 2566753278 AT2GP: 8 Vector__XXX
 SG_ DslParticulateFilterOutletPress2 : 16|16@1+ (0.1,0) [0|6425.5] "kPa" Vector__XXX
 SG_ DslParticulateFilterIntakePress2 : 0|16@1+ (0.1,0) [0|6425.5] "kPa" Vector__XXX

BO_ 2566756862 AT2HI: 8 Vector__XXX
 SG_ Aftrtrtmnt2AvrgDstncBtwnActvDPFR : 288|32@1+ (0.125,0) [0|526385151.9] "km" Vector__XXX
 SG_ Aftrtrtmnt2AvrgTmBtwnActvRgnrtns : 256|32@1+ (1,0) [0|4211081215] "s" Vector__XXX
 SG_ Aftrtrtmnt2DslPrtcltFltrTtlN3732 : 224|32@1+ (1,0) [0|4211081215] "" Vector__XXX
 SG_ Aftrtrtmnt2DslPrtcltFltrTtlN3731 : 192|32@1+ (1,0) [0|4211081215] "" Vector__XXX
 SG_ Aftrtrtmnt2DslPrtcltFltrTtlNmbrO : 160|32@1+ (1,0) [0|4211081215] "" Vector__XXX
 SG_ Aftrtrtmnt2DslPrtcltFltrTtlPssvR : 128|32@1+ (1,0) [0|4211081215] "s" Vector__XXX
 SG_ Aftrtrtmnt2TtlNmbrOfActvRgnrtons : 96|32@1+ (1,0) [0|4211081215] "" Vector__XXX
 SG_ Aftertreatment2TotalDisabledTime : 64|32@1+ (1,0) [0|4211081215] "s" Vector__XXX
 SG_ Aftrtrtmnt2TotalRegenerationTime : 32|32@1+ (1,0) [0|4211081215] "s" Vector__XXX
 SG_ Aftertreatment2TotalFuelUsed : 0|32@1+ (0.5,0) [0|2105540607.5] "L" Vector__XXX

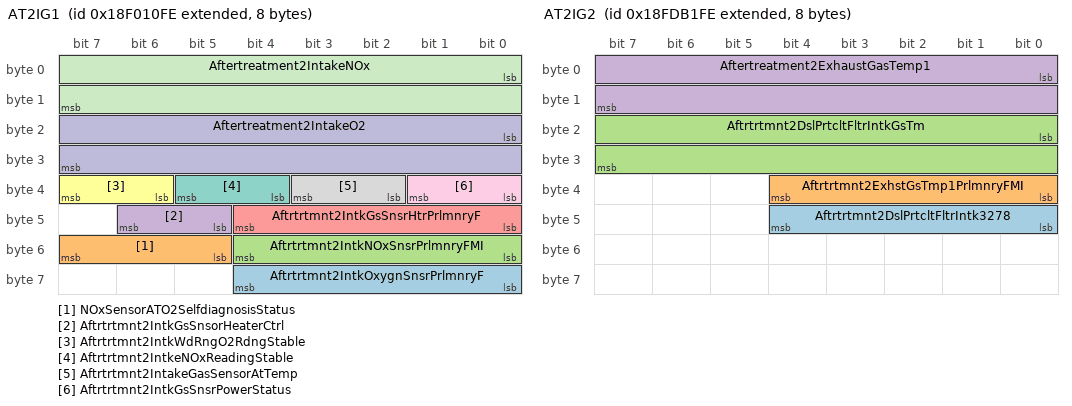
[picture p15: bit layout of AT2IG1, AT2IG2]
BO_ 2565869822 AT2IG1: 8 Vector__XXX
 SG_ Aftrtrtmnt2IntkOxygnSnsrPrlmnryF : 56|5@1+ (1,0) [0|31] "" Vector__XXX
 SG_ NOxSensorATO2SelfdiagnosisStatus : 53|3@1+ (1,0) [0|7] "" Vector__XXX
 SG_ Aftrtrtmnt2IntkNOxSnsrPrlmnryFMI : 48|5@1+ (1,0) [0|31] "" Vector__XXX
 SG_ Aftrtrtmnt2IntkGsSnsorHeaterCtrl : 45|2@1+ (1,0) [0|3] "" Vector__XXX
 SG_ Aftrtrtmnt2IntkGsSnsrHtrPrlmnryF : 40|5@1+ (1,0) [0|31] "" Vector__XXX
 SG_ Aftrtrtmnt2IntkWdRngO2RdngStable : 38|2@1+ (1,0) [0|3] "" Vector__XXX
 SG_ Aftrtrtmnt2IntkeNOxReadingStable : 36|2@1+ (1,0) [0|3] "" Vector__XXX
 SG_ Aftrtrtmnt2IntakeGasSensorAtTemp : 34|2@1+ (1,0) [0|3] "" Vector__XXX
 SG_ Aftrtrtmnt2IntkGsSnsrPowerStatus : 32|2@1+ (1,0) [0|3] "" Vector__XXX
 SG_ Aftertreatment2IntakeO2 : 16|16@1+ (0.000514,-12) [-12|21] "%" Vector__XXX
 SG_ Aftertreatment2IntakeNOx : 0|16@1+ (0.05,-200) [-200|3012.75] "ppm" Vector__XXX

BO_ 2566763006 AT2IG2: 8 Vector__XXX
 SG_ Aftrtrtmnt2DslPrtcltFltrIntk3278 : 40|5@1+ (1,0) [0|31] "" Vector__XXX
 SG_ Aftrtrtmnt2ExhstGsTmp1PrlmnryFMI : 32|5@1+ (1,0) [0|31] "" Vector__XXX
 SG_ Aftrtrtmnt2DslPrtcltFltrIntkGsTm : 16|16@1+ (0.03125,-273) [-273|1734.96875] "deg C" Vector__XXX
 SG_ Aftertreatment2ExhaustGasTemp1 : 0|16@1+ (0.03125,-273) [-273|1734.96875] "deg C" Vector__XXX

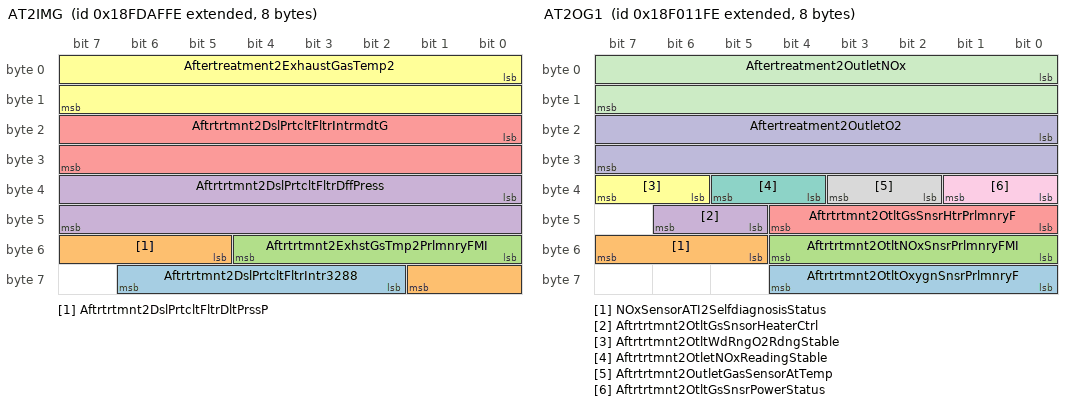
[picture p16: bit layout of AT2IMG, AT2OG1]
BO_ 2566762494 AT2IMG: 8 Vector__XXX
 SG_ Aftrtrtmnt2DslPrtcltFltrIntr3288 : 58|5@1+ (1,0) [0|31] "" Vector__XXX
 SG_ Aftrtrtmnt2DslPrtcltFltrDltPrssP : 53|5@1+ (1,0) [0|31] "" Vector__XXX
 SG_ Aftrtrtmnt2ExhstGsTmp2PrlmnryFMI : 48|5@1+ (1,0) [0|31] "" Vector__XXX
 SG_ Aftrtrtmnt2DslPrtcltFltrDffPress : 32|16@1+ (0.1,0) [0|6425.5] "kPa" Vector__XXX
 SG_ Aftrtrtmnt2DslPrtcltFltrIntrmdtG : 16|16@1+ (0.03125,-273) [-273|1734.96875] "deg C" Vector__XXX
 SG_ Aftertreatment2ExhaustGasTemp2 : 0|16@1+ (0.03125,-273) [-273|1734.96875] "deg C" Vector__XXX

BO_ 2565870078 AT2OG1: 8 Vector__XXX
 SG_ Aftrtrtmnt2OtltOxygnSnsrPrlmnryF : 56|5@1+ (1,0) [0|31] "" Vector__XXX
 SG_ NOxSensorATI2SelfdiagnosisStatus : 53|3@1+ (1,0) [0|7] "" Vector__XXX
 SG_ Aftrtrtmnt2OtltNOxSnsrPrlmnryFMI : 48|5@1+ (1,0) [0|31] "" Vector__XXX
 SG_ Aftrtrtmnt2OtltGsSnsorHeaterCtrl : 45|2@1+ (1,0) [0|3] "" Vector__XXX
 SG_ Aftrtrtmnt2OtltGsSnsrHtrPrlmnryF : 40|5@1+ (1,0) [0|31] "" Vector__XXX
 SG_ Aftrtrtmnt2OtltWdRngO2RdngStable : 38|2@1+ (1,0) [0|3] "" Vector__XXX
 SG_ Aftrtrtmnt2OtletNOxReadingStable : 36|2@1+ (1,0) [0|3] "" Vector__XXX
 SG_ Aftrtrtmnt2OutletGasSensorAtTemp : 34|2@1+ (1,0) [0|3] "" Vector__XXX
 SG_ Aftrtrtmnt2OtltGsSnsrPowerStatus : 32|2@1+ (1,0) [0|3] "" Vector__XXX
 SG_ Aftertreatment2OutletO2 : 16|16@1+ (0.000514,-12) [-12|21] "%" Vector__XXX
 SG_ Aftertreatment2OutletNOx : 0|16@1+ (0.05,-200) [-200|3012.75] "ppm" Vector__XXX

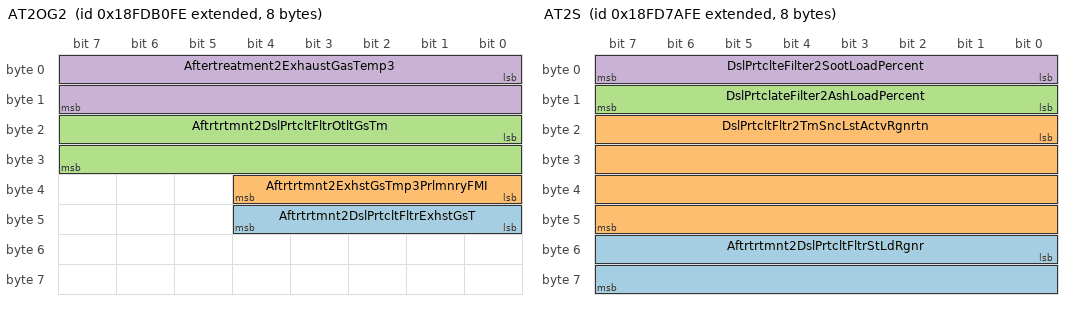
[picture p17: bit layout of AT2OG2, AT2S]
BO_ 2566762750 AT2OG2: 8 Vector__XXX
 SG_ Aftrtrtmnt2DslPrtcltFltrExhstGsT : 40|5@1+ (1,0) [0|31] "" Vector__XXX
 SG_ Aftrtrtmnt2ExhstGsTmp3PrlmnryFMI : 32|5@1+ (1,0) [0|31] "" Vector__XXX
 SG_ Aftrtrtmnt2DslPrtcltFltrOtltGsTm : 16|16@1+ (0.03125,-273) [-273|1734.96875] "deg C" Vector__XXX
 SG_ Aftertreatment2ExhaustGasTemp3 : 0|16@1+ (0.03125,-273) [-273|1734.96875] "deg C" Vector__XXX

BO_ 2566748926 AT2S: 8 Vector__XXX
 SG_ Aftrtrtmnt2DslPrtcltFltrStLdRgnr : 48|16@1+ (0.0025,0) [0|160.6375] "%" Vector__XXX
 SG_ DslPrtcltFltr2TmSncLstActvRgnrtn : 16|32@1+ (1,0) [0|4211081215] "s" Vector__XXX
 SG_ DslPrtclateFilter2AshLoadPercent : 8|8@1+ (1,0) [0|250] "%" Vector__XXX
 SG_ DslPrtclteFilter2SootLoadPercent : 0|8@1+ (1,0) [0|250] "%" Vector__XXX

BO_ 2566748414 AT2TI: 32 Vector__XXX
 SG_ Aftrtrtmnt2DslPrtcltFltrTrpN3748 : 224|32@1+ (1,0) [0|4211081215] "" Vector__XXX
 SG_ Aftrtrtmnt2DslPrtcltFltrTrpN3747 : 192|32@1+ (1,0) [0|4211081215] "" Vector__XXX
 SG_ Aftrtrtmnt2DslPrtcltFltrTrpN3746 : 160|32@1+ (1,0) [0|4211081215] "" Vector__XXX
 SG_ Aftrtrtmnt2DslPrtcltFltrTrpPssvR : 128|32@1+ (1,0) [0|4211081215] "s" Vector__XXX
 SG_ Aftrtrtmnt2DslPrtcltFltrTrpNmbrO : 96|32@1+ (1,0) [0|4211081215] "" Vector__XXX
 SG_ Aftrtrtmnt2DslPrtcltFltrTrpDsbld : 64|32@1+ (1,0) [0|4211081215] "s" Vector__XXX
 SG_ Aftrtrtmnt2DslPrtcltFltrTrpActvR : 32|32@1+ (1,0) [0|4211081215] "s" Vector__XXX
 SG_ Aftrtrtmnt2DslPrtcltFltrTrpFlUsd : 0|32@1+ (0.5,0) [0|2105540607.5] "L" Vector__XXX

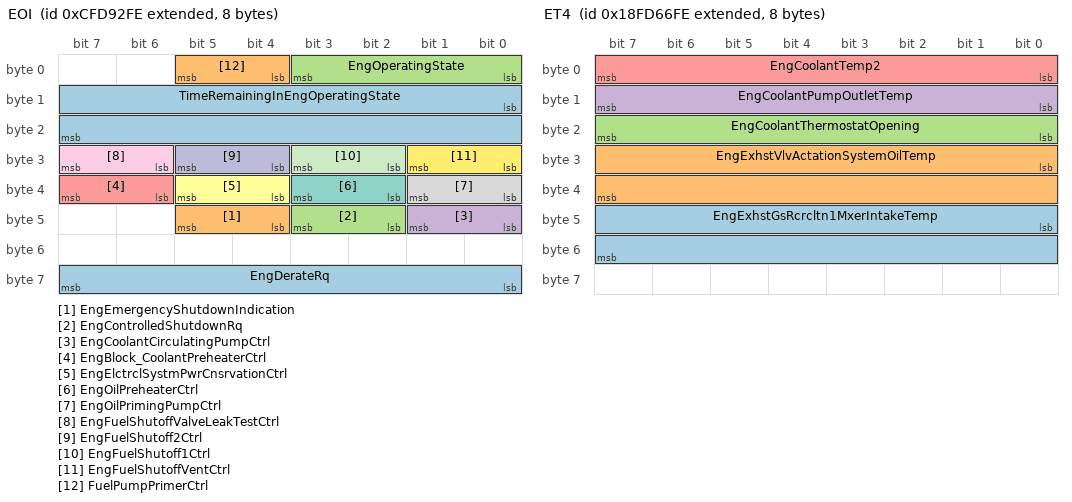
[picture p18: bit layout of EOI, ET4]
BO_ 2365428478 EOI: 8 Vector__XXX
 SG_ EngDerateRq : 56|8@1+ (0.4,0) [0|100] "%" Vector__XXX
 SG_ EngEmergencyShutdownIndication : 44|2@1+ (1,0) [0|3] "" Vector__XXX
 SG_ EngControlledShutdownRq : 42|2@1+ (1,0) [0|3] "" Vector__XXX
 SG_ EngCoolantCirculatingPumpCtrl : 40|2@1+ (1,0) [0|3] "" Vector__XXX
 SG_ EngBlock_CoolantPreheaterCtrl : 38|2@1+ (1,0) [0|3] "" Vector__XXX
 SG_ EngElctrclSystmPwrCnsrvationCtrl : 36|2@1+ (1,0) [0|3] "" Vector__XXX
 SG_ EngOilPreheaterCtrl : 34|2@1+ (1,0) [0|3] "" Vector__XXX
 SG_ EngOilPrimingPumpCtrl : 32|2@1+ (1,0) [0|3] "" Vector__XXX
 SG_ EngFuelShutoffValveLeakTestCtrl : 30|2@1+ (1,0) [0|3] "" Vector__XXX
 SG_ EngFuelShutoff2Ctrl : 28|2@1+ (1,0) [0|3] "" Vector__XXX
 SG_ EngFuelShutoff1Ctrl : 26|2@1+ (1,0) [0|3] "" Vector__XXX
 SG_ EngFuelShutoffVentCtrl : 24|2@1+ (1,0) [0|3] "" Vector__XXX
 SG_ TimeRemainingInEngOperatingState : 8|16@1+ (1,0) [0|64255] "s" Vector__XXX
 SG_ FuelPumpPrimerCtrl : 4|2@1+ (1,0) [0|3] "" Vector__XXX
 SG_ EngOperatingState : 0|4@1+ (1,0) [0|15] "" Vector__XXX

BO_ 2566743806 ET4: 8 Vector__XXX
 SG_ EngExhstGsRcrcltn1MxerIntakeTemp : 40|16@1+ (0.03125,-273) [-273|1734.96875] "deg C" Vector__XXX
 SG_ EngExhstVlvActationSystemOilTemp : 24|16@1+ (0.03125,-273) [-273|1734.96875] "deg C" Vector__XXX
 SG_ EngCoolantThermostatOpening : 16|8@1+ (0.4,0) [0|100] "%" Vector__XXX
 SG_ EngCoolantPumpOutletTemp : 8|8@1+ (1,-40) [-40|210] "deg C" Vector__XXX
 SG_ EngCoolantTemp2 : 0|8@1+ (1,-40) [-40|210] "deg C" Vector__XXX

BO_ 2499635454 GCVW: 8 Vector__XXX
 SG_ NetVehicleWeightChange : 24|24@1+ (2,-16449535) [-16449535|16449535] "kg" Vector__XXX
 SG_ GrossCombinationWeight : 0|24@1+ (2,0) [0|32899070] "kg" Vector__XXX

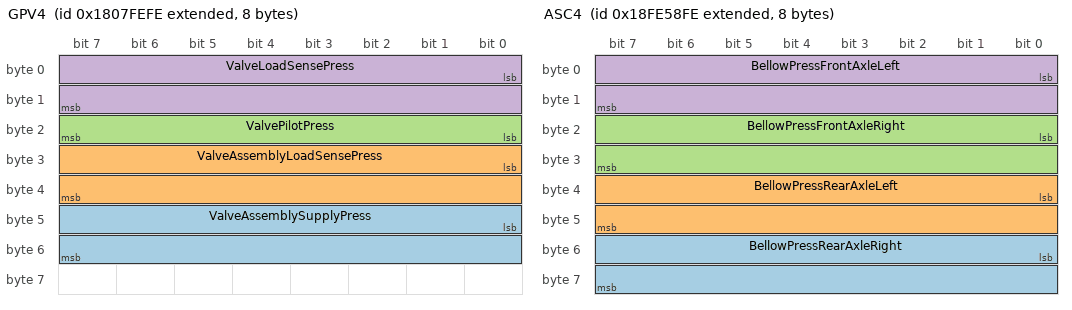
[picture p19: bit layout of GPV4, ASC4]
BO_ 2550660862 GPV4: 8 Vector__XXX
 SG_ ValveAssemblySupplyPress : 40|16@1+ (5,0) [0|321275] "kPa" Vector__XXX
 SG_ ValveAssemblyLoadSensePress : 24|16@1+ (5,0) [0|321275] "kPa" Vector__XXX
 SG_ ValvePilotPress : 16|8@1+ (16,0) [0|4000] "kPa" Vector__XXX
 SG_ ValveLoadSensePress : 0|16@1+ (5,0) [0|321275] "kPa" Vector__XXX

BO_ 2566805758 ASC4: 8 Vector__XXX
 SG_ BellowPressRearAxleRight : 48|16@1+ (0.1,0) [0|6425.5] "kPa" Vector__XXX
 SG_ BellowPressRearAxleLeft : 32|16@1+ (0.1,0) [0|6425.5] "kPa" Vector__XXX
 SG_ BellowPressFrontAxleRight : 16|16@1+ (0.1,0) [0|6425.5] "kPa" Vector__XXX
 SG_ BellowPressFrontAxleLeft : 0|16@1+ (0.1,0) [0|6425.5] "kPa" Vector__XXX

BO_ 2566806014 ASC3: 8 Vector__XXX
 SG_ RelativeLevelRearAxleRight : 48|16@1+ (0.1,-3200) [-3200|3225.5] "mm" Vector__XXX
 SG_ RelativeLevelRearAxleLeft : 32|16@1+ (0.1,-3200) [-3200|3225.5] "mm" Vector__XXX
 SG_ RelativeLevelFrontAxleRight : 16|16@1+ (0.1,-3200) [-3200|3225.5] "mm" Vector__XXX
 SG_ RelativeLevelFrontAxleLeft : 0|16@1+ (0.1,-3200) [-3200|3225.5] "mm" Vector__XXX

BO_ 2362638078 ASC2: 8 Vector__XXX
 SG_ MemoryLevelRq : 60|4@1+ (1,0) [0|15] "" Vector__XXX
 SG_ PrhbitAutomaticAirSuspensionCtrl : 58|2@1+ (1,0) [0|3] "" Vector__XXX
 SG_ SpeedDependentLevelCtrlRq : 56|2@1+ (1,0) [0|3] "" Vector__XXX
 SG_ AllowLevelCtrlDuringBrakingCmd : 54|2@1+ (1,0) [0|3] "" Vector__XXX
 SG_ ProhibitAirSuspensionCtrl : 52|2@1+ (1,0) [0|3] "" Vector__XXX
 SG_ KneelingCmdRearAxle : 50|2@1+ (1,0) [0|3] "" Vector__XXX
 SG_ KneelingCmdFrontAxle : 48|2@1+ (1,0) [0|3] "" Vector__XXX
 SG_ DamperStiffnessRqLift_TagAxle : 40|8@1+ (0.4,0) [0|100] "%" Vector__XXX
 SG_ DamperStiffnessRqRearAxle : 32|8@1+ (0.4,0) [0|100] "%" Vector__XXX
 SG_ DamperStiffnessRqFrontAxle : 24|8@1+ (0.4,0) [0|100] "%" Vector__XXX
 SG_ LiftAxle2PosCmd : 22|2@1+ (1,0) [0|3] "" Vector__XXX
 SG_ LiftAxle1PosCmd : 20|2@1+ (1,0) [0|3] "" Vector__XXX
 SG_ LevelCtrlModeRq : 16|4@1+ (1,0) [0|15] "" Vector__XXX
 SG_ NominalLevelRqRearAxle : 12|4@1+ (1,0) [0|15] "" Vector__XXX
 SG_ NominalLevelRqFrontAxle : 8|4@1+ (1,0) [0|15] "" Vector__XXX
 SG_ KneelingCtrlModeRq : 6|2@1+ (1,0) [0|3] "" Vector__XXX
 SG_ KneelingRqRightSide : 4|2@1+ (1,0) [0|3] "" Vector__XXX
 SG_ KneelingRqLeftSide : 2|2@1+ (1,0) [0|3] "" Vector__XXX
 SG_ AutomaticTractionHelp : 0|2@1+ (1,0) [0|3] "" Vector__XXX

CM_ BO_ 2566726398 "The purpose of this PGN is to group the aftertreatment gas oxidation catalyst data for bank 1. These values include the ...";
CM_ SG_ 2566726398 Aftrtrtmnt1GsOxdtnCtlystDffPrssP "Used to identify the applicable J1939-73 FMI detected in the gas oxidation catalyst differential pressure sensor by the ...";
CM_ SG_ 2566726398 Aftrtrtmnt1GsOxdtnCtlystOtlt4757 "Used to identify the applicable J1939-73 FMI detected in the gas oxidation catalyst outlet gas temperature sensor by the ...";
CM_ SG_ 2566726398 Aftrtrtmnt1GsOxdtnCtlystIntk4756 "Used to identify the applicable J1939-73 FMI detected in the gas oxidation catalyst intake gas temperature sensor by the ...";
CM_ SG_ 2566726398 Aftrtrtmnt1GsOxdtnCtlystDffPress "Exhaust differential pressure measured between the intake and exhaust of the gas oxidation catalyst in exhaust bank 1.";
CM_ SG_ 2566726398 Aftrtrtmnt1GsOxdtnCtlystOtltGsTm "Temperature of engine combustion byproducts leaving the gas oxidation catalyst in exhaust bank 1.  This gas parameter ...";
CM_ SG_ 2566726398 Aftrtrtmnt1GsOxdtnCtlystIntkGsTm "Temperature of engine combustion byproducts entering the gas oxidation catalyst in exhaust bank 1.  This gas parameter ...";
CM_ BO_ 2566742270 "HB1C provides the system specific individual B1 failure counters";
CM_ SG_ 2566742270 FailureSpecificB1Counter "The Failure Specific B1 Counter provides an individual B1 counter";
CM_ SG_ 2566742270 FailureModeIdentifier1 "The FMI defines the type of failure detected in the subsystem identified by an SPN.";
CM_ SG_ 2566742270 SPN1High "SPN #1 (Conversion Version 4)";
CM_ SG_ 2566742270 SPN1 "SPN #1 (Conversion Version 4)";
CM_ BO_ 2566742526 "Cumulative Continuous MI-System";
CM_ SG_ 2566742526 SysGreatestB1Counter "System Greatest B1 Counter";
CM_ SG_ 2566742526 SysCumulativeContinuousMITime "System Cumulative Continuous MI Time";
CM_ BO_ 2566742782 "Harmonized Global Regulation Description";
CM_ SG_ 2566742782 RegulationDescription "Global Technical Regulation Description";
CM_ BO_ 2566743038 "Harmonized Roadworthiness";
CM_ SG_ 2566743038 SysIncompleteMonitorCount "System Incomplete Monitor Count";
CM_ SG_ 2566743038 SysMalIndActivationMode "System Malfunction Indicator Status";
CM_ SG_ 2566743038 SysMalIndDisplayStrategy "System Malfunction Indicator Display";
CM_ SG_ 2566743038 SysContinuousMalfunctionInd "System Continuous Malfunction Indicator";
CM_ SG_ 2566743038 SysNonRoadworthyCompCount "System Non-Roadworthy Component Count";
CM_ BO_ 2566743294 "Harmonized Roadworthiness ";
CM_ SG_ 2566743294 VehicleCurrentMIAccumTime "Vehicle Current MI Accumulated Time";
CM_ SG_ 2566743294 VehicleIncompleteMonitorCount "Vehicle Incomplete Monitor Count";
CM_ SG_ 2566743294 VehicleMalfunctionIndActMode "Vehicle Malfunction Indicator Status ";
CM_ SG_ 2566743294 VehicleMalfunctionIndStrategy "Vehicle Malfunction Indicator Display Strategy ";
CM_ SG_ 2566743294 VehicleContinuousMalfunctionInd "Vehicle Continuous Malfunction Indicator";
CM_ SG_ 2566743294 VehicleNonRoadworthyCompCount "Vehicle Non-Roadworthy Component Count";
CM_ BO_ 2560687870 "The status of engine operating in the NTE control areas for given pollutants, such as NOx and PM";
CM_ SG_ 2560687870 PMNTEDeficiencyAreaStatus "Status of engine operation within the PM NTE Deficiency Area";
CM_ SG_ 2560687870 MnfcPMNTECarveOutAreaStatus "Status of engine operation within the manufacturer specific PM NTE carve out area";
CM_ SG_ 2560687870 PMNTEControlAreaStatus "Status of engine operation within the bounded region of the engine's torque and speed map.";
CM_ SG_ 2560687870 NOxNTEDeficiencyAreaStatus "Status of engine operation within the NOx NTE Deficiency Area";
CM_ SG_ 2560687870 MnfcNOxNTECarveOutAreaStatus "Status of engine operation within the bounded region of the engine's torque and speed map.";
CM_ SG_ 2560687870 NOxNTEControlAreaStatus "Status of engine operation within the bounded region of the engine's torque and speed map.";
CM_ BO_ 2292317950 "The total engine run time while each of the Emission Increasing Auxiliary Emission Control Devices is active";
CM_ SG_ 2292317950 AECDEngineHours1Timer2 "The total engine running hours recorded in the second timer for the EI-AECD";
CM_ SG_ 2292317950 AECDEngineHours1Timer1 "The total engine running hours recorded in the first timer for the EI-AECD";
CM_ SG_ 2292317950 AECDNumber1 "The manufacturer assigned number for the specific EI-AECD";
CM_ SG_ 2566809342 BatteryMainSwitchHoldState "Parameter indicating whether the battery main switch is held due to an external request or not. The state battery main ...";
CM_ BO_ 2365446910 "Used to transfer information about the measured status of the 1st 2 axes and up to 12 buttons of a joystick.  Additional ...";
CM_ SG_ 2365446910 Joystick3XAxisDetentPosStatus "Reports when the current joystick position is in the detent position for that axis of travel.";
CM_ SG_ 2365446910 Joystick3Button9PressedStatus "Reports when the joystick button has been pressed.";
CM_ SG_ 2365446910 Joystick3Button10PressedStatus "Reports when the joystick button has been pressed.";
CM_ SG_ 2365446910 Joystick3Button11PressedStatus "Reports when the joystick button has been pressed.";
CM_ SG_ 2365446910 Joystick3Button12PressedStatus "Reports when the joystick button has been pressed.";
CM_ SG_ 2365446910 Joystick3YAxisDetentPosStatus "Reports when the current joystick position is in the detent position for that axis of travel.";
CM_ SG_ 2365446910 Joystick3YAxisPos "The position of the joystick in the relative motion of travel from the neutral position.  Position value of 0 is Neutral and ...";
CM_ SG_ 2365446910 Jystck3YAxsLvrFrwrdPstvPosStatus "Reports when the current joystick position is on the positive travel side (forward, right, clockwise, up) relative to the ...";
CM_ SG_ 2365446910 Jystck3YAxsLvrBckNgtivePosStatus "Reports when the current joystick position is on the negative travel side (back, left, counterclockwise, down) relative to the ...";
CM_ SG_ 2365446910 Joystick3YAxisNeutralPosStatus "Reports when the current joystick position is in the neutral position for that axis of travel.  The neutral position ...";
CM_ SG_ 2365446910 Joystick3XAxisPos "The position of the joystick in the relative motion of travel from the neutral position.  Position value of 0 is Neutral and ...";
CM_ SG_ 2365446910 Jystck3XAxsLvrRghtPstvePosStatus "Reports when the current joystick position is on the positive travel side (forward, right, clockwise, up) relative to the ...";
CM_ SG_ 2365446910 Jystck3XAxsLvrLftNgtivePosStatus "Reports when the current joystick position is on the negative travel side (back, left, counterclockwise, down) relative to the ...";
CM_ SG_ 2365446910 Joystick3XAxisNeutralPosStatus "Reports when the current joystick position is in the neutral position for that axis of travel.  The neutral position ...";
CM_ SG_ 2365446910 Joystick3Button5PressedStatus "Reports when the joystick button has been pressed.";
CM_ SG_ 2365446910 Joystick3Button6PressedStatus "Reports when the joystick button has been pressed.";
CM_ SG_ 2365446910 Joystick3Button7PressedStatus "Reports when the joystick button has been pressed.";
CM_ SG_ 2365446910 Joystick3Button8PressedStatus "Reports when the joystick button has been pressed.";
CM_ SG_ 2365446910 Joystick3Button1PressedStatus "Reports when the joystick button has been pressed.";
CM_ SG_ 2365446910 Joystick3Button2PressedStatus "Reports when the joystick button has been pressed.";
CM_ SG_ 2365446910 Joystick3Button3PressedStatus "Reports when the joystick button has been pressed.";
CM_ SG_ 2365446910 Joystick3Button4PressedStatus "Reports when the joystick button has been pressed.";
CM_ BO_ 2365446398 "Used to transfer information about the measured status of the 1st 2 axes and up to 12 buttons of a joystick.  Additional ...";
CM_ SG_ 2365446398 Joystick2XAxisDetentPosStatus "Reports when the current joystick position is in the detent position for that axis of travel.";
CM_ SG_ 2365446398 Joystick2YAxisDetentPosStatus "Reports when the current joystick position is in the detent position for that axis of travel.";
CM_ SG_ 2365446398 Joystick2YAxisPos "The position of the joystick in the relative motion of travel from the neutral position.  Position value of 0 is Neutral and ...";
CM_ SG_ 2365446398 Jystck2YAxsLvrFrwrdPstvPosStatus "Reports when the current joystick position is on the positive travel side (forward, right, clockwise, up) relative to the ...";
CM_ SG_ 2365446398 Jystck2YAxsLvrBckNgtivePosStatus "Reports when the current joystick position is on the negative travel side (back, left, counterclockwise, down) relative to the ...";
CM_ SG_ 2365446398 Joystick2YAxisNeutralPosStatus "Reports when the current joystick position is in the neutral position for that axis of travel.  The neutral position ...";
CM_ SG_ 2365446398 Joystick2XAxisPos "The position of the joystick in the relative motion of travel from the neutral position.  Position value of 0 is Neutral and ...";
CM_ SG_ 2365446398 Jystck2XAxsLvrRghtPstvePosStatus "Reports when the current joystick position is on the positive travel side (forward, right, clockwise, up) relative to the ...";
CM_ SG_ 2365446398 Jystck2XAxsLvrLftNgtivePosStatus "Reports when the current joystick position is on the negative travel side (back, left, counterclockwise, down) relative to the ...";
CM_ SG_ 2365446398 Joystick2XAxisNeutralPosStatus "Reports when the current joystick position is in the neutral position for that axis of travel.  The neutral position ...";
CM_ SG_ 2365446398 Joystick2Button9PressedStatus "Reports when the joystick button has been pressed.";
CM_ SG_ 2365446398 Joystick2Button10PressedStatus "Reports when the joystick button has been pressed.";
CM_ SG_ 2365446398 Joystick2Button11PressedStatus "Reports when the joystick button has been pressed.";
CM_ SG_ 2365446398 Joystick2Button12PressedStatus "Reports when the joystick button has been pressed.";
CM_ SG_ 2365446398 Joystick2Button5PressedStatus "Reports when the joystick button has been pressed.";
CM_ SG_ 2365446398 Joystick2Button6PressedStatus "Reports when the joystick button has been pressed.";
CM_ SG_ 2365446398 Joystick2Button7PressedStatus "Reports when the joystick button has been pressed.";
CM_ SG_ 2365446398 Joystick2Button8PressedStatus "Reports when the joystick button has been pressed.";
CM_ SG_ 2365446398 Joystick2Button1PressedStatus "Reports when the joystick button has been pressed.";
CM_ SG_ 2365446398 Joystick2Button2PressedStatus "Reports when the joystick button has been pressed.";
CM_ SG_ 2365446398 Joystick2Button3PressedStatus "Reports when the joystick button has been pressed.";
CM_ SG_ 2365446398 Joystick2Button4PressedStatus "Reports when the joystick button has been pressed.";
CM_ BO_ 2365445886 "Used to transfer information about the measured status of the 1st 2 axes and up to 12 buttons of a joystick.  Additional ...";
CM_ SG_ 2365445886 Joystick1XAxisDetentPosStatus "Reports when the current joystick position is in the detent position for that axis of travel.";
CM_ SG_ 2365445886 Joystick1YAxisDetentPosStatus "Reports when the current joystick position is in the detent position for that axis of travel.";
CM_ SG_ 2365445886 Joystick1YAxisPos "The position of the joystick in the relative motion of travel from the neutral position.  Position value of 0 is Neutral and ...";
CM_ SG_ 2365445886 Jystck1YAxsLvrFrwrdPstvPosStatus "Reports when the current joystick position is on the positive travel side (forward, right, clockwise, up) relative to the ...";
CM_ SG_ 2365445886 Jystck1YAxsLvrBckNgtivePosStatus "Reports when the current joystick position is on the negative travel side (back, left, counterclockwise, down) relative to the ...";
CM_ SG_ 2365445886 Joystick1YAxisNeutralPosStatus "Reports when the current joystick position is in the neutral position for that axis of travel.  The neutral position ...";
CM_ SG_ 2365445886 Joystick1XAxisPos "The position of the joystick in the relative motion of travel from the neutral position.  Position value of 0 is Neutral and ...";
CM_ SG_ 2365445886 Joystick1Button9PressedStatus "Reports when the joystick button has been pressed.";
CM_ SG_ 2365445886 Joystick1Button10PressedStatus "Reports when the joystick button has been pressed.";
CM_ SG_ 2365445886 Joystick1Button11PressedStatus "Reports when the joystick button has been pressed.";
CM_ SG_ 2365445886 Joystick1Button12PressedStatus "Reports when the joystick button has been pressed.";
CM_ SG_ 2365445886 Joystick1Button5PressedStatus "Reports when the joystick button has been pressed.";
CM_ SG_ 2365445886 Joystick1Button6PressedStatus "Reports when the joystick button has been pressed.";
CM_ SG_ 2365445886 Joystick1Button7PressedStatus "Reports when the joystick button has been pressed.";
CM_ SG_ 2365445886 Joystick1Button8PressedStatus "Reports when the joystick button has been pressed.";
CM_ SG_ 2365445886 Joystick1Button1PressedStatus "Reports when the joystick button has been pressed.";
CM_ SG_ 2365445886 Joystick1Button2PressedStatus "Reports when the joystick button has been pressed.";
CM_ SG_ 2365445886 Joystick1Button3PressedStatus "Reports when the joystick button has been pressed.";
CM_ SG_ 2365445886 Joystick1Button4PressedStatus "Reports when the joystick button has been pressed.";
CM_ SG_ 2365445886 Jystck1XAxsLvrRghtPstvePosStatus "Reports when the current joystick position is on the positive travel side (forward, right, clockwise, up) relative to the ...";
CM_ SG_ 2365445886 Jystck1XAxsLvrLftNgtivePosStatus "Reports when the current joystick position is on the negative travel side (back, left, counterclockwise, down) relative to the ...";
CM_ SG_ 2365445886 Joystick1XAxisNeutralPosStatus "Reports when the current joystick position is in the neutral position for that axis of travel.  The neutral position ...";
CM_ BO_ 2566847230 "Brakes";
CM_ SG_ 2566847230 ParkingBrakeRedWarningSignal "This parameter commands the Parking Brake red optical warning signal.";
CM_ SG_ 2566847230 ParkBrakeReleaseInhibitStatus "This parameter provides reports on the status of the Park Brake Release Inhibit function.";
CM_ SG_ 2566847230 ParkingBrakeActuator "Signal which indicates the current state of the actuator(s) that control the parking brake (see also SPN 70 and 5275).";
CM_ SG_ 2566847230 BrakeSecondPress "Gage pressure of air in the secondary, or service side, of the air brake system.";
CM_ SG_ 2566847230 BrakePrimaryPress "Gage pressure of air in the primary, or supply side, of the air brake system.";
CM_ SG_ 2566847230 BrakeAppPress "Gage pressure of compressed air or fluid in vehicle braking system measured at the brake chamber when brake shoe (or ...";
CM_ SG_ 2566848254 AuxPumpPress "Gage pressure of auxiliary water pump driven as a PTO device.";
CM_ BO_ 2566725886 "The purpose of this PGN is to group the aftertreatment diesel oxidation catalyst data for bank 1. These values include the ...";
CM_ SG_ 2566725886 Aftrtrtmnt1DslOxdtnCtlystDff4770 "Used to identify the applicable J1939-73 FMI detected in the diesel oxidation catalyst differential pressure sensor by the ...";
CM_ SG_ 2566725886 Aftrtrtmnt1DslOxdtnCtlystOtl4769 "Used to identify the applicable J1939-73 FMI detected in the diesel oxidation catalyst outlet gas temperature sensor by ...";
CM_ SG_ 2566725886 Aftrtrtmnt1DslOxdtnCtlystInt4768 "Used to identify the applicable J1939-73 FMI detected in the diesel oxidation catalyst intake gas temperature sensor by ...";
CM_ SG_ 2566725886 Aftrtrtmnt1DslOxdtnCtlystDffPrss "Exhaust differential pressure measured between the intake and exhaust of a diesel oxidation catalyst in exhaust bank 1.";
CM_ SG_ 2566725886 Aftrtrtmnt1DslOxdtnCtlystOtltGsT "Temperature of engine combustion byproducts leaving the diesel oxidation catalyst exhaust in exhaust bank 1.  This ...";
CM_ SG_ 2566725886 Aftrtrtmnt1DslOxdtnCtlystIntkGsT "Temperature of engine combustion byproducts entering the diesel oxidation catalyst in exhaust bank 1.  This diesel ...";
CM_ BO_ 2560884478 "This message shall provide the applicable lamp for each individual DTC";
CM_ SG_ 2560884478 DTCWarnLampSupportStatus "Lamp support status";
CM_ SG_ 2560884478 DTCWarnLampSupportFlash "Lamp support status";
CM_ SG_ 2560884478 DTCStopLampSupportStatus "Lamp support status";
CM_ SG_ 2560884478 DTCStopLampSupportFlash "Lamp support status";
CM_ SG_ 2560884478 DTCProtectLampSupportStatus "Lamp support status";
CM_ SG_ 2560884478 DTCProtectLampSupportFlash "Lamp support status";
CM_ SG_ 2560884478 DTCMilSupportStatus "Lamp support status";
CM_ SG_ 2560884478 DTCMilSupportFlash "Lamp support status";
CM_ SG_ 2560884478 DTC1 "Diagnostic Trouble Code";
CM_ BO_ 2633844734 "ASCII text string describing a manufacturer-specific Transmission Mode.  This PGN may contain up to 8 instances of the ...";
CM_ BO_ 2560360190 "This is a standardized mechanism for an ECU to report a listing of the manufacturer specific (i.e. proprietary) methods ...";
CM_ SG_ 2560360190 DataDictionaryMethod "A manufacturer defined code to define the proprietary communications method.  The structure and interpretation of the ...";
CM_ SG_ 2560360190 DataDictionaryManufacturerCode "The J1939 Manufacturer Code (see J1939 Table B10) associated with the manufacturer who defined the proprietary ...";
CM_ BO_ 2566736126 "Provides bank 2 short-term and long-term fuel trim values ...";
CM_ SG_ 2566736126 EngExhstGsOxygnSnsrClsdLpOprtnBn "This parameter indicates the status of the bank 2 O2 sensor feedback closed loop operation ...";
CM_ SG_ 2566736126 ShorttermFuelTrimBank2 "This parameter is the short-term percent change in fueling based on the O2 sensor feedback for cylinder bank 2, based ...";
CM_ SG_ 2566736126 LongtermFuelTrimBank2 "This parameter is the long-term percent change in fueling based on the O2 sensor feedback for cylinder bank 2, based on ...";
CM_ BO_ 2566736382 "Provides bank 1 short-term and long-term fuel trim values ...";
CM_ SG_ 2566736382 EngExhstGsOxygnSnsrClsdLpOprtnBn "This parameter indicates the status of the bank 1 O2 sensor feedback closed loop operation ...";
CM_ SG_ 2566736382 ShorttermFuelTrimBank1 "This parameter is the short-term percent change in fueling based on the O2 sensor feedback for cylinder bank 1, based ...";
CM_ SG_ 2566736382 LongtermFuelTrimBank1 "This parameter is the long-term percent change in fueling based on the O2 sensor feedback for cylinder bank 1, based on ...";
CM_ BO_ 2565874174 "This PGN contains the speed information and status signal of each engine speed sensor. This message is used for ...";
CM_ SG_ 2565874174 EngSpdSensor1TimingPatternStatus "This is the timing pattern status of the engine speed sensor signal for sensor 1.   The sensor may be sending a speed ...";
CM_ SG_ 2565874174 EngSpdSensor2TimingPatternStatus "This is the timing pattern status of the engine speed sensor signal for sensor 2.  The sensor may be sending a speed ...";
CM_ SG_ 2565874174 EngSpdSensor3TimingPatternStatus "This is the timing pattern status of the engine speed sensor signal for sensor 3.  The sensor may be sending a speed ...";
CM_ SG_ 2565874174 EngSpeed3 "The engine speed as measured by speed sensor 3.";
CM_ SG_ 2565874174 EngSpeed2 "The engine speed as measured by speed sensor 2 ...";
CM_ SG_ 2565874174 EngSpeed1 "The engine speed as measured by speed sensor 1.";
CM_ BO_ 2432520958 "Transmit status information from the Master ECU to an electronic thermostat ...";
CM_ SG_ 2432520958 EngAxClerSupplyValve2ActuatorCmd "The control command applied to the engine auxiliary cooler supply valve 2 actuator, where 0% represents closed and ...";
CM_ SG_ 2432520958 EngAxClerSupplyValve1ActuatorCmd "The control command applied to the engine auxiliary cooler supply valve 1 actuator, where 0% represents closed and ...";
CM_ SG_ 2432520958 DsredEngCoolantThermostatOpening "Indicates the desired position of the engine coolant control valve.   0% represents the thermostat allows flow to ...";
CM_ SG_ 2432520958 DesiredEngCoolantPumpOutletTemp "Desired engine coolant temperature of the engine to an electronic thermostat.  If the electronic thermostat valve is ...";
CM_ SG_ 2432520958 EngCoolantThermostatMode "Specifies if the engine coolant thermostat valve will operate in temperature control mode or position control mode.";
CM_ BO_ 2560425726 "Notes: Implementers are encouraged to use specific functional SPNs whenever possible.";
CM_ SG_ 2560425726 AuxI_OChannel19 "Identifies the current value of auxiliary input/output channels that are configured uniquely per application.";
CM_ SG_ 2560425726 AuxI_OChannel20 "Identifies the current value of auxiliary input/output channels that are configured uniquely per application.";
CM_ SG_ 2560425726 AuxI_OChannel21 "Identifies the current value of auxiliary input/output channels that are configured uniquely per application.";
CM_ SG_ 2560425726 AuxI_OChannel22 "Identifies the current value of auxiliary input/output channels that are configured uniquely per application.";
CM_ SG_ 2560425726 AuxI_OChannel15 "Identifies the current value of auxiliary input/output channels that are configured uniquely per application.";
CM_ SG_ 2560425726 AuxI_OChannel16 "Identifies the current value of auxiliary input/output channels that are configured uniquely per application.";
CM_ SG_ 2560425726 AuxI_OChannel17 "Identifies the current value of auxiliary input/output channels that are configured uniquely per application.";
CM_ SG_ 2560425726 AuxI_OChannel18 "Identifies the current value of auxiliary input/output channels that are configured uniquely per application.";
CM_ BO_ 2560491262 "Notes: Implementers are encouraged to use specific functional SPNs whenever possible.";
CM_ SG_ 2560491262 AuxI_OChannel11 "Identifies the current value of auxiliary input/output channels that are configured uniquely per application.";
CM_ SG_ 2560491262 AuxI_OChannel12 "Identifies the current value of auxiliary input/output channels that are configured uniquely per application.";
CM_ SG_ 2560491262 AuxI_OChannel13 "Identifies the current value of auxiliary input/output channels that are configured uniquely per application.";
CM_ SG_ 2560491262 AuxI_OChannel14 "Identifies the current value of auxiliary input/output channels that are configured uniquely per application.";
CM_ SG_ 2560491262 AuxI_OChannel7 "Identifies the current value of auxiliary input/output channels that are configured uniquely per application.";
CM_ SG_ 2560491262 AuxI_OChannel8 "Identifies the current value of auxiliary input/output channels that are configured uniquely per application.";
CM_ SG_ 2560491262 AuxI_OChannel9 "Identifies the current value of auxiliary input/output channels that are configured uniquely per application.";
CM_ SG_ 2560491262 AuxI_OChannel10 "Identifies the current value of auxiliary input/output channels that are configured uniquely per application.";
CM_ BO_ 2349399806 "Notes: Implementers are encouraged to use specific functional SPNs whenever possible.";
CM_ SG_ 2349399806 AuxI_OChannel3 "Identifies the current value of auxiliary input/output channels that are configured uniquely per application.";
CM_ SG_ 2349399806 AuxI_OChannel4 "Identifies the current value of auxiliary input/output channels that are configured uniquely per application.";
CM_ SG_ 2349399806 AuxI_OChannel5 "Identifies the current value of auxiliary input/output channels that are configured uniquely per application.";
CM_ SG_ 2349399806 AuxI_OChannel6 "Identifies the current value of auxiliary input/output channels that are configured uniquely per application.";
CM_ BO_ 2566758398 "Contains information about the aftertreatment 1 air system ...";
CM_ SG_ 2566758398 Aftertreatment1AirEnableActuator "Indicates whether aftertreatment 1 air enable actuator is on or off ...";
CM_ SG_ 2566758398 Aftertreatment1PurgeAirActuator "Indicates whether aftertreatment 1 purge air actuator is on or off ...";
CM_ SG_ 2566758398 Aftrtrtmnt1AtmizationAirActuator "Indicates whether aftertreatment 1 atomization air actuator is on or off ...";
CM_ SG_ 2566758398 Aftertreatment1AirSystemRelay "Indicates whether aftertreatment 1 air system relay is on or off ...";
CM_ SG_ 2566758398 Aftrtratment1AirPressActuatorPos "Position of the aftertreatment 1 air pressure actuator as measured by a position feedback sensor.";
CM_ SG_ 2566758398 Aftertreatment1AirPressCtrl "Position that the controller is commanding the aftertreatment 1 air pressure control to maintain.  0% = fully closed, 100% = ...";
CM_ SG_ 2566758398 Aftertreatment1PurgeAirPress "Pressure of the purge air supply for aftertreatment 1 ...";
CM_ SG_ 2566758398 Aftertreatment1SupplyAirPress "Pressure of the supply air for aftertreatment 1.  Supply air is the air supplied from a pneumatic line for an air-assisted or ...";
CM_ BO_ 2566745598 "This PGN contains information about the Aftertreatment 1 Air Control.";
CM_ SG_ 2566745598 Aftertreatment1SecondAirPress "Pressure of the secondary air for aftertreatment 1.  Secondary air is air provided to the exhaust system (per SAE J2403).";
CM_ SG_ 2566745598 Aftertreatment1SecondAirMassFlow "Indicates the secondary air mass flow for aftertreatment 1.  Secondary air is the air provided to the exhaust system (per ...";
CM_ SG_ 2566745598 Aftertreatment1SecondAirTemp "Indicates the secondary air temperature for aftertreatment 1.  Secondary air is air provided to the exhaust system (per ...";
CM_ SG_ 2566745598 Aftrtreatment1SecondAirDiffPress "Indicates the secondary air differential pressure for aftertreatment 1.  Secondary air is air provided to the exhaust system ...";
CM_ BO_ 2566758910 "Contains information about the aftertreatment 1 fuel system ...";
CM_ SG_ 2566758910 Aftrtrtmnt1FlInjector1HeaterCtrl "Heating level that the controller is commanding the aftertreatment 1 fuel injector 1 heater control to maintain. 0% = off, ...";
CM_ SG_ 2566758910 Aftrtreatment1FuelEnableActuator "Indicates whether aftertreatment 1 fuel enable actuator is on or off ...";
CM_ SG_ 2566758910 Aftrtreatment1RegenerationStatus "Indicates whether regeneration is active or inactive in aftertreatment 1.";
CM_ SG_ 2566758910 Aftertreatment1Ignt "Indicates whether aftertreatment 1 ignition circuit is energized by the ECM.";
CM_ SG_ 2566758910 Aftertreatment1FuelDrainActuator "Indicates whether aftertreatment 1 fuel drain actuator is on or off ...";
CM_ SG_ 2566758910 Aftertreatment1FuelPress1Ctrl "Position that the controller is commanding the aftertreatment 1 fuel pressure control to maintain.  0% = fully closed, 100% ...";
CM_ SG_ 2566758910 Aftertreatment1FuelRate "Rate of fuel being delivered to aftertreatment 1 for regeneration ...";
CM_ SG_ 2566758910 Aftertreatment1FuelPress1 "First fuel pressure measurement for the aftertreatment 1 system ...";
CM_ BO_ 2566743550 "Contains information about the aftertreatment 1 fuel system.  See also PGN 64929.";
CM_ SG_ 2566743550 Aftrtrtmnt1HydrcrbnDsrIntkFlTemp "Measured temperature of the intake fuel to the hydrocarbon dosing device ...";
CM_ SG_ 2566743550 Aftrtrtmnt1FelPress2ActuatorCtrl "Indicates how the device is controlling the aftertreatment 1 fuel pressure 2 regulating control valve.   0% = fully closed, ...";
CM_ SG_ 2566743550 Aftrtrtmnt1FlFlwDverterValveCtrl "Indicates how the device is controlling the aftertreatment 1 fuel flow diverter valve. When this valve is on it diverts fuel flow ...";
CM_ SG_ 2566743550 Aftertreatment1FuelPumpRelayCtrl "Indicates how the device is controlling the aftertreatment 1 fuel pump relay.";
CM_ SG_ 2566743550 Aftertreatment1FuelPress2 "Second fuel pressure measurement for the aftertreatment 1 system ...";
CM_ BO_ 2566753534 "Diesel particulate filter gas parameters for system or bank 1 ...";
CM_ SG_ 2566753534 DslParticulateFilterOutletPress1 "This parameter indicates the diesel particulate filter outlet gage pressure 1 (bank 1).";
CM_ SG_ 2566753534 DslParticulateFilterIntakePress1 "This parameter indicates the diesel particulate filter intake gage pressure 1 (bank 1).";
CM_ BO_ 2566756606 "Contains information about the history of the aftertreatment 1 system ...";
CM_ SG_ 2566756606 Aftrtrtmnt1AvrgDstncBtwnActvDPFR "Indicates the average distance since last reset between active regenerations, that have not been forced to occur by ...";
CM_ SG_ 2566756606 Aftrtrtmnt1AvrgTmBtwnActvRgnrtns "Indicates the average time since last reset between active regenerations, that have not been forced to occur by manual ...";
CM_ SG_ 2566756606 Aftrtrtmnt1DslPrtcltFltrTtlN3728 "Total number of aftertreatment device 1 active regeneration manual requests by the operator over the lifetime of the ...";
CM_ SG_ 2566756606 Aftrtrtmnt1DslPrtcltFltrTtlN3727 "Total number of aftertreatment device 1 active regeneration inhibit requests by the operator over the lifetime of the device.";
CM_ SG_ 2566756606 Aftrtrtmnt1DslPrtcltFltrTtlNmbrO "Total number of passive regenerations by aftertreatment device 1 over the lifetime of the device.";
CM_ SG_ 2566756606 Aftrtrtmnt1DslPrtcltFltrTtlPssvR "Total amount of time that aftertreatment 1 diesel particulate filter has been in passive regeneration over the lifetime of the ...";
CM_ SG_ 2566756606 Aftrtrtmnt1TtlNmbrOfActvRgnrtons "Total number of active regenerations by aftertreatment device 1 over the lifetime of the device.";
CM_ SG_ 2566756606 Aftertreatment1TotalDisabledTime "Total amount of time that aftertreatment 1 regeneration has been manually disabled.";
CM_ SG_ 2566756606 Aftrtrtmnt1TotalRegenerationTime "Total amount of time that aftertreatment device 1 has been regenerating over the lifetime of the device.";
CM_ SG_ 2566756606 Aftertreatment1TotalFuelUsed "Total amount of fuel used by aftertreatment device 1 over the lifetime of the device.";
CM_ BO_ 2565869310 "The purpose of this PGN is to group the aftertreatment intake sensor data for bank 1.  These values include the NOx, ...";
CM_ SG_ 2565869310 Aftrtrtmnt1IntkOxygnSnsrPrlmnryF "Used to identify the applicable J1939-73 FMI detected in the aftertreatment intake oxygen sensor by the manufacturer’s ...";
CM_ SG_ 2565869310 NOxSensorATO1SelfdiagnosisStatus "Self-diagnosis result status for NOx sensor ATO1 (Aftertreatment Outlet Bank 1) ...";
CM_ SG_ 2565869310 Aftrtrtmnt1IntkNOxSnsrPrlmnryFMI "Used to identify the applicable J1939-73 FMI detected in the aftertreatment intake NOx sensor by the manufacturer’s ...";
CM_ SG_ 2565869310 Aftrtrtmnt1IntkGsSnsorHeaterCtrl "Indicates the heater status in the warm-up process.  Upon receiving a power-up command, the gas sensor ramps up ...";
CM_ SG_ 2565869310 Aftrtrtmnt1IntkGsSnsrHtrPrlmnryF "Used to identify the applicable J1939-73 FMI detected in the heater of the intake exhaust gas sensor, either NOx or O2, ...";
CM_ SG_ 2565869310 Aftrtrtmnt1IntkWdRngO2RdngStable "Indicates that the %O2 reading of the aftertreatment intake gas sensor, either NOx or O2, is stable as determined by the ...";
CM_ SG_ 2565869310 Aftrtrtmnt1IntkeNOxReadingStable "Indicates that the NOx reading of the aftertreatment intake NOx sensor is stable as determined by the manufacturer’s ...";
CM_ SG_ 2565869310 Aftrtrtmnt1IntakeGasSensorAtTemp "Indicates that the heater element of the aftertreatment intake gas sensor, either NOx or O2, is within the manufacturer’s ...";
CM_ SG_ 2565869310 Aftrtrtmnt1IntkGsSnsrPowerStatus "Indicates that the power supplied to the aftertreatment intake gas sensor, either NOx or O2, is within the manufacturer’s ...";
CM_ SG_ 2565869310 Aftertreatment1IntakeO2 "The actual oxidation factor (%O2) of the gas within the exhaust stream.  For positive values, the parameter represents the ...";
CM_ SG_ 2565869310 Aftertreatment1IntakeNOx "The amount of combined NO and NO2 in the exhaust entering the aftertreatment system measured by a NOx sensor at ...";
CM_ BO_ 2566763774 "The purpose of this PGN is to group the aftertreatment intake gas temperature messages for bank 1.";
CM_ SG_ 2566763774 Aftrtrtmnt1DslPrtcltFltrIntk3244 "Used to identify the applicable J1939-73 FMI detected in the diesel particulate filter intake gas temperature sensor by the ...";
CM_ SG_ 2566763774 Aftrtrtmnt1ExhstGsTmp1PrlmnryFMI "Used to identify the applicable J1939-73 FMI detected in the exhaust gas temperature 1 sensor by the manufacturer’s ...";
CM_ SG_ 2566763774 Aftrtrtmnt1DslPrtcltFltrIntkGsTm "Temperature of engine combustion byproducts entering the diesel particulate filter in exhaust bank 1.";
CM_ SG_ 2566763774 Aftertreatment1ExhaustGasTemp1 "The reading from the exhaust gas temperature sensor located farthest upstream in the aftertreatment system in exhaust ...";
CM_ BO_ 2631728894 "NOTE–See Figures PGN56320_A to PGN56320_F for examples of Anti-theft message transfers.  Bit 1 is the right most ...";
CM_ SG_ 2631728894 AntitheftRandomNumber "A seven byte random numeric code provided by the component in response to an anti-theft request.  This parameter is ...";
CM_ SG_ 2631728894 AntitheftModifyPwdStates "This parameter is used to indicate whether a password request was successfully performed, or if the request could not be ...";
CM_ SG_ 2631728894 AntitheftComponentStatusStates "Indicates whether or not the component can be started.";
CM_ SG_ 2631728894 AntitheftPwdValidIndicator "Indicates the presence of a validated password.";
CM_ SG_ 2631728894 AntthftEncryptnSdPrsentIndicator "Indicates the presence of the encryption seed random number.";
CM_ BO_ 2631794430 "NOTE–See Figures PGN56320_A thru PGN56320_F for examples of Anti-theft message transfers.  Bit 1 is the right most ...";
CM_ SG_ 2631794430 AntitheftPwdRepresentation "This parameter is the seven byte numeric code (i.e., ‘encrypted password’ or ‘key’) that is generated based on the ...";
CM_ SG_ 2631794430 AntitheftCmdStates "This parameter is used to identify the specific requests being sent to the component.";
CM_ SG_ 2631794430 AntitheftDesiredExitModeStates "This parameter is used to specify the desired triggers that are to be used by the component in deciding when to transition ...";
CM_ SG_ 2631794430 AntthftEncryptionIndicatorStates "This parameter is used to indicate if a random number seed is being requested, or if an encrypted password is being ...";
CM_ SG_ 2633934846 EngAltWinding3Temp "Temperature of the windings inside the alternator.";
CM_ SG_ 2633934846 EngAltWinding2Temp "Temperature of the windings inside the alternator.";
CM_ SG_ 2633934846 EngAltWinding1Temp "Temperature of the windings inside the alternator.";
CM_ SG_ 2633934846 EngAltBearing2Temp "Temperature of the bearing inside the alternator.  Bearing 2 is the right or front bearing.";
CM_ SG_ 2633934846 EngAltBearing1Temp "Temperature of the bearing inside the alternator.  Bearing 1 is the left or rear bearing.";
CM_ BO_ 2362572542 "Used for suspension control ...";
CM_ SG_ 2362572542 LevelPresetRearAxleRight "Set value for nominal level 'preset level' at the right side of the rear axle. This value is referred to 'Normal level 1'.  For ...";
CM_ SG_ 2362572542 LevelPresetRearAxleLeft "Set value for nominal level 'preset level' at the left side of the rear axle. This value is referred to 'Normal level 1'.  For ...";
CM_ SG_ 2362572542 LevelPresetFrontAxleRight "Set value for nominal level 'preset level' at the right side of the front axle. This value is referred to 'Normal level 1'.  For ...";
CM_ SG_ 2362572542 LevelPresetFrontAxleLeft "Set value for nominal level 'preset level' at the left side of the front axle. This value is referred to 'Normal level 1'.  For ...";
CM_ BO_ 2365478910 "Used for damper stiffness information ...";
CM_ SG_ 2365478910 ElctrncShckAbsrbrCtrlMdLft_TgAxl "Signal which indicates the current mode of operation of the electronic shock absorber control at the lift/tag axle.";
CM_ SG_ 2365478910 ElctrncShckAbsrbrCtrlMdeRearAxle "Signal which indicates the current mode of operation of the electronic shock absorber control at the rear axle.";
CM_ SG_ 2365478910 ElctrncShckAbsrbrCtrlMdFrontAxle "Signal which indicates the current mode of operation of the electronic shock absorber control at the front axle.";
CM_ SG_ 2365478910 DamperStiffnessLift_TagAxle "Damper stiffness information of the shock absorber control at the lift of tag axle ...";
CM_ SG_ 2365478910 DamperStiffnessRearAxle "Damper stiffness information of the shock absorber control at the rear axle ...";
CM_ SG_ 2365478910 DamperStiffnessFrontAxle "Damper stiffness information of the shock absorber control at the front axle ...";
CM_ BO_ 2560950014 "This message conveys the scaled test results for the applicable test requested in DM7.";
CM_ SG_ 2560950014 TestLimitMinimum "The test value must be greater than or equal to Test Limit Minimum in order for the test to pass";
CM_ SG_ 2560950014 TestLimitMaximum "The test value must be less than or equal to Test Limit Maximum in order for the test to pass.";
CM_ SG_ 2560950014 TestValue "The test value collected during the test.";
CM_ SG_ 2560950014 SlotId "The SLOT Identifer is used to determine the multiplier and offset to be used to scale the test value.";
CM_ SG_ 2560950014 TestIdentifier "Test Identifier";
CM_ SG_ 2560950014 FailureModeIdentifier1 "The FMI defines the type of failure detected in the subsystem identified by an SPN.";
CM_ SG_ 2560950014 SPN1High "SPN #1 (Conversion Version 4)";
CM_ SG_ 2560950014 SPN1 "SPN #1 (Conversion Version 4)";
CM_ BO_ 2566763262 "The purpose of this PGN is to group the aftertreatment intermediate gas temperature and pressure messages.";
CM_ SG_ 2566763262 Aftrtrtmnt1DslPrtcltFltrIntr3254 "Used to identify the applicable J1939-73 FMI detected in the diesel particulate filter intermediate gas temperature sensor ...";
CM_ SG_ 2566763262 Aftrtrtmnt1DslPrtcltFltrDltPrssP "Used to identify the applicable J1939-73 FMI detected in the diesel particulate filter differential pressure sensor by the ...";
CM_ SG_ 2566763262 Aftrtrtmnt1ExhstGsTmp2PrlmnryFMI "Used to identify the applicable J1939-73 FMI detected in the exhaust gas temperature 2 sensor by the manufacturer’s ...";
CM_ SG_ 2566763262 Aftrtrtmnt1DslPrtcltFltrDffPress "Exhaust differential pressure measured between the intake and exhaust of a diesel particulate filter in exhaust bank 1.";
CM_ SG_ 2566763262 Aftrtrtmnt1DslPrtcltFltrIntrmdtG "Temperature of engine combustion byproducts at a mid-point in the diesel particulate filter in exhaust bank 1.";
CM_ SG_ 2566763262 Aftertreatment1ExhaustGasTemp2 "The reading from the exhaust gas temperature sensor located midstream of the other two temperature sensors in the ...";
CM_ BO_ 2565869566 "The purpose of this PGN is to group the aftertreatment outlet sensor data for bank 1.  These values include the NOx, ...";
CM_ SG_ 2565869566 Aftrtrtmnt1OtltOxygnSnsrPrlmnryF "Used to identify the applicable J1939-73 FMI detected in the aftertreatment outlet oxygen sensor by the manufacturer’s ...";
CM_ SG_ 2565869566 NOxSensorATI1SelfdiagnosisStatus "Self-diagnosis result status for NOx sensor ATI1 (Aftertreatment Intake Bank 1) ...";
CM_ SG_ 2565869566 Aftrtrtmnt1OtltNOxSnsrPrlmnryFMI "Used to identify the applicable J1939-73 FMI detected in the aftertreatment outlet NOx sensor by the manufacturer’s ...";
CM_ SG_ 2565869566 Aftrtrtmnt1OtltGsSnsorHeaterCtrl "Indicates the heater status in the warm-up process.  Upon receiving a power-up command, the gas sensor ramps up ...";
CM_ SG_ 2565869566 Aftrtrtmnt1OtltGsSnsrHtrPrlmnryF "Used to identify the applicable J1939-73 FMI detected in the heater of the outlet exhaust gas sensor, either NOx or O2, by ...";
CM_ SG_ 2565869566 Aftrtrtmnt1OtltWdRngO2RdngStable "Indicates that the %O2 reading of the aftertreatment outlet gas sensor, either NOx or O2, is stable as determined by the ...";
CM_ SG_ 2565869566 Aftrtrtmnt1OtletNOxReadingStable "Indicates that the NOx reading of the aftertreatment outlet NOx sensor is stable as determined by the manufacturer’s ...";
CM_ SG_ 2565869566 Aftrtrtmnt1OutletGasSensorAtTemp "Indicates that the heater element of the aftertreatment outlet gas sensor, either NOx or O2, is within the manufacturer’s ...";
CM_ SG_ 2565869566 Aftrtrtmnt1OtltGsSnsrPowerStatus "Indicates that the power supplied to the aftertreatment outlet gas sensor, either NOx or O2, is within the manufacturer’s ...";
CM_ SG_ 2565869566 Aftertreatment1OutletO2 "The actual oxidation factor (%O2) of the gas within the exhaust stream.  For positive values, the parameter represents the ...";
CM_ SG_ 2565869566 Aftertreatment1OutletNOx "The amount of combined NO and NO2 in the exhaust exiting the aftertreatment system measured by a NOx sensor at the ...";
CM_ BO_ 2566763518 "The purpose of this PGN is to group the aftertreatment outlet gas temperature messages.";
CM_ SG_ 2566763518 Aftrtrtmnt1DslPrtcltFltrOtltExhs "Used to identify the applicable J1939-73 FMI detected in the diesel particulate filter outlet gas temperature sensor by the ...";
CM_ SG_ 2566763518 Aftrtrtmnt1ExhstGsTmp3PrlmnryFMI "Used to identify the applicable J1939-73 FMI detected in the exhaust gas temperature 3 sensor by the manufacturer’s ...";
CM_ SG_ 2566763518 Aftrtrtmnt1DslPrtcltFltrOtltGsTm "Temperature of engine combustion byproducts leaving the diesel particulate filter exhaust in exhaust bank 1.";
CM_ SG_ 2566763518 Aftertreatment1ExhaustGasTemp3 "The reading from the exhaust gas temperature sensor located farthest downstream in the aftertreatment system in ...";
CM_ BO_ 2566749182 "This PGN contains information about the aftertreatment 1 (diesel particulate filter 1 soot and ash load).";
CM_ SG_ 2566749182 Aftrtrtmnt1DslPrtcltFltrStLdRgnr "This parameter indicates the value that will first cause DPF regeneration in aftertreatment 1. There may be multiple ...";
CM_ SG_ 2566749182 DslPrtcltFltr1TmSncLstActvRgnrtn "Indicates the time since the last active regeneration event of diesel particulate filter 1.";
CM_ SG_ 2566749182 DslPrtclateFilter1AshLoadPercent "Indicates the ash load percent of diesel particulate filter 1.  100% is the level at which diesel particulate filter ash service ...";
CM_ SG_ 2566749182 DslPrtclteFilter1SootLoadPercent "Indicates the soot load percent of diesel particulate filter 1.  100% is the level at which active diesel particulate filter ...";
CM_ BO_ 2566748670 "This PGN contains trip total information about the aftertreatment 1.";
CM_ SG_ 2566748670 Aftrtrtmnt1DslPrtcltFltrTrpN3740 "Total number of aftertreatment 1 diesel particulate filter active regeneration manual requests by the operator during the ...";
CM_ SG_ 2566748670 Aftrtrtmnt1DslPrtcltFltrTrpN3739 "Total number of aftertreatment 1 diesel particulate filter active regeneration inhibit requests by the operator during the ...";
CM_ SG_ 2566748670 Aftrtrtmnt1DslPrtcltFltrTrpN3738 "Total number of passive regenerations of the aftertreatment 1 diesel particulate filter during the current trip period.";
CM_ SG_ 2566748670 Aftrtrtmnt1DslPrtcltFltrTrpPssvR "Total amount of time that the aftertreatment 1 diesel particulate filter has been in passive regeneration during the current ...";
CM_ SG_ 2566748670 Aftrtrtmnt1DslPrtcltFltrTrpNmbrO "Total number of active regenerations of the aftertreatment 1 diesel particulate filter during the current trip period.";
CM_ SG_ 2566748670 Aftrtrtmnt1DslPrtcltFltrTrpDsbld "Total amount of time that aftertreatment 1 diesel particulate filter regeneration has been manually disabled during the ...";
CM_ SG_ 2566748670 Aftrtrtmnt1DslPrtcltFltrTrpActvR "Total amount of time that the aftertreatment 1 diesel particulate filter has been in active regeneration during the current ...";
CM_ SG_ 2566748670 Aftrtrtmnt1DslPrtcltFltrTrpFlUsd "Total amount of fuel used by the aftertreatment 1 diesel particulate filter during the current trip period.";
CM_ BO_ 2566758142 "Contains information about the aftertreatment 2 air system ...";
CM_ SG_ 2566758142 Aftertreatment2AirEnableActuator "Indicates whether aftertreatment 2 air enable actuator is on or off ...";
CM_ SG_ 2566758142 Aftertreatment2PurgeAirActuator "Indicates whether aftertreatment 2 purge air actuator is on or off ...";
CM_ SG_ 2566758142 Aftrtrtmnt2AtmizationAirActuator "Indicates whether aftertreatment 2 atomization air actuator is on or off ...";
CM_ SG_ 2566758142 Aftertreatment2AirSystemRelay "Indicates whether aftertreatment 2 air system relay is on or off ...";
CM_ SG_ 2566758142 Aftrtratment2AirPressActuatorPos "Position of the aftertreatment 2 air pressure actuator as measured by a position feedback sensor.";
CM_ SG_ 2566758142 Aftertreatment2AirPressCtrl "Position that the controller is commanding the aftertreatment 2 air pressure control to maintain.  0% = fully closed, 100% = ...";
CM_ SG_ 2566758142 Aftertreatment2PurgeAirPress "Pressure of the purge air supply for aftertreatment 2 ...";
CM_ SG_ 2566758142 Aftertreatment2SupplyAirPress "Pressure of the supply air for aftertreatment 2.  Supply air is the air supplied from a pneumatic line for an air-assisted or ...";
CM_ BO_ 2566745342 "This PGN contains information about the Aftertreatment 2 Air Control.";
CM_ SG_ 2566745342 Aftertreatment2SecondAirPress "Pressure of the secondary air for aftertreatment 2.  Secondary air is air provided to the exhaust system (per SAE J2403).";
CM_ SG_ 2566745342 Aftertreatment2SecondAirMassFlow "Indicates the secondary air mass flow for aftertreatment 2.  Secondary air is the air provided to the exhaust system (per ...";
CM_ SG_ 2566745342 Aftertreatment2SecondAirTemp "Indicates the secondary air temperature for aftertreatment 2.  Secondary air is air provided to the exhaust system (per ...";
CM_ SG_ 2566745342 Aftrtreatment2SecondAirDiffPress "Indicates the secondary air differential pressure for aftertreatment 2.  Secondary air is air provided to the exhaust system ...";
CM_ BO_ 2566758654 "Contains information about the aftertreatment 2 fuel system ...";
CM_ SG_ 2566758654 Aftrtrtmnt2FlInjector1HeaterCtrl "Heating level that the controller is commanding the aftertreatment 2 fuel injector 1 heater control to maintain. 0% = off, ...";
CM_ SG_ 2566758654 Aftrtreatment2FuelEnableActuator "Indicates whether aftertreatment 2 fuel enable actuator is on or off ...";
CM_ SG_ 2566758654 Aftrtreatment2RegenerationStatus "Indicates whether regeneration is active or inactive in aftertreatment 2.";
CM_ SG_ 2566758654 Aftertreatment2Ignt "Indicates whether aftertreatment 2 ignition circuit is energized by the ECM.";
CM_ SG_ 2566758654 Aftertreatment2FuelDrainActuator "Indicates whether aftertreatment 2 fuel drain actuator is on or off ...";
CM_ SG_ 2566758654 Aftertreatment2FuelPress1Ctrl "Position that the controller is commanding the aftertreatment 2 fuel pressure control to maintain.  0% = fully closed, 100% ...";
CM_ SG_ 2566758654 Aftertreatment2FuelRate "Rate of fuel being delivered to aftertreatment 2 for regeneration ...";
CM_ SG_ 2566758654 Aftertreatment2FuelPress1 "Pressure of the fuel for Aftertreatment 2.";
CM_ BO_ 2566753278 "Diesel particulate filter gas parameters for system or bank 2 ...";
CM_ SG_ 2566753278 DslParticulateFilterOutletPress2 "This parameter indicates the diesel particulate filter outlet gage pressure 2 (bank 2).";
CM_ SG_ 2566753278 DslParticulateFilterIntakePress2 "This parameter indicates the diesel particulate filter intake gage pressure 2 (bank 2).";
CM_ BO_ 2566756862 "Contains information about the history of the aftertreatment 2 system ...";
CM_ SG_ 2566756862 Aftrtrtmnt2AvrgDstncBtwnActvDPFR "Indicates the average distance since last reset between active regenerations, that have not been forced to occur by ...";
CM_ SG_ 2566756862 Aftrtrtmnt2AvrgTmBtwnActvRgnrtns "Indicates the average time since last reset between active regenerations, that have not been forced to occur by manual ...";
CM_ SG_ 2566756862 Aftrtrtmnt2DslPrtcltFltrTtlN3732 "Total number of Aftertreatment device 2 active regeneration manual requests by the operator over the lifetime of the ...";
CM_ SG_ 2566756862 Aftrtrtmnt2DslPrtcltFltrTtlN3731 "Total number of Aftertreatment device 2 active regeneration inhibit requests by the operator over the lifetime of the ...";
CM_ SG_ 2566756862 Aftrtrtmnt2DslPrtcltFltrTtlNmbrO "Total number of passive regenerations by Aftertreatment device 2 over the lifetime of the device.";
CM_ SG_ 2566756862 Aftrtrtmnt2DslPrtcltFltrTtlPssvR "Total amount of time that Aftertreatment device 2 has been in passive regeneration over the lifetime of the device.";
CM_ SG_ 2566756862 Aftrtrtmnt2TtlNmbrOfActvRgnrtons "Total number of active regenerations by aftertreatment device 2 over the lifetime of the device.";
CM_ SG_ 2566756862 Aftertreatment2TotalDisabledTime "Total amount of time that aftertreatment 2 regeneration has been manually disabled.";
CM_ SG_ 2566756862 Aftrtrtmnt2TotalRegenerationTime "Total amount of time that aftertreatment device 2 has been regenerating over the lifetime of the device.";
CM_ SG_ 2566756862 Aftertreatment2TotalFuelUsed "Total amount of fuel used by aftertreatment device 2 over the lifetime of the device.";
CM_ BO_ 2565869822 "The purpose of this PGN is to group the aftertreatment intake sensor data for bank 2.  These values include the NOx, ...";
CM_ SG_ 2565869822 Aftrtrtmnt2IntkOxygnSnsrPrlmnryF "Used to identify the applicable J1939-73 FMI detected in the aftertreatment intake oxygen sensor by the manufacturer’s ...";
CM_ SG_ 2565869822 NOxSensorATO2SelfdiagnosisStatus "Self-diagnosis result status for NOx sensor ATO2 (Aftertreatment Outlet Bank 2) ...";
CM_ SG_ 2565869822 Aftrtrtmnt2IntkNOxSnsrPrlmnryFMI "Used to identify the applicable J1939-73 FMI detected in the aftertreatment intake NOx sensor by the manufacturer’s ...";
CM_ SG_ 2565869822 Aftrtrtmnt2IntkGsSnsorHeaterCtrl "Indicates the heater status in the warm-up process.  Upon receiving a power-up command, the gas sensor ramps up ...";
CM_ SG_ 2565869822 Aftrtrtmnt2IntkGsSnsrHtrPrlmnryF "Used to identify the applicable J1939-73 FMI detected in the heater of the intake exhaust gas sensor, either NOx or O2, ...";
CM_ SG_ 2565869822 Aftrtrtmnt2IntkWdRngO2RdngStable "Indicates that the %O2 reading of the aftertreatment intake gas sensor, either NOx or O2, is stable as determined by the ...";
CM_ SG_ 2565869822 Aftrtrtmnt2IntkeNOxReadingStable "Indicates that the NOx reading of the aftertreatment intake NOx sensor is stable as determined by the manufacturer’s ...";
CM_ SG_ 2565869822 Aftrtrtmnt2IntakeGasSensorAtTemp "Indicates that the heater element of the aftertreatment intake gas sensor, either NOx or O2, is within the manufacturer’s ...";
CM_ SG_ 2565869822 Aftrtrtmnt2IntkGsSnsrPowerStatus "Indicates that the power supplied to the aftertreatment intake gas sensor, either NOx or O2, is within the manufacturer’s ...";
CM_ SG_ 2565869822 Aftertreatment2IntakeO2 "The actual oxidation factor (%O2) of the gas within the exhaust stream.  For positive values, the parameter represents the ...";
CM_ SG_ 2565869822 Aftertreatment2IntakeNOx "The amount of combined NO and NO2 in the exhaust entering the aftertreatment system measured by a NOx sensor at ...";
CM_ BO_ 2566763006 "The purpose of this PGN is to group the aftertreatment intake gas temperature messages for bank 2.";
CM_ SG_ 2566763006 Aftrtrtmnt2DslPrtcltFltrIntk3278 "Used to identify the applicable J1939-73 FMI detected in the diesel particulate filter intake gas temperature sensor by the ...";
CM_ SG_ 2566763006 Aftrtrtmnt2ExhstGsTmp1PrlmnryFMI "Used to identify the applicable J1939-73 FMI detected in the exhaust gas temperature 1 sensor by the manufacturer’s ...";
CM_ SG_ 2566763006 Aftrtrtmnt2DslPrtcltFltrIntkGsTm "Temperature of engine combustion byproducts entering the diesel particulate filter in exhaust bank 2.  (For a single ...";
CM_ SG_ 2566763006 Aftertreatment2ExhaustGasTemp1 "The reading from the exhaust gas temperature sensor located farthest upstream in the aftertreatment system in exhaust ...";
CM_ BO_ 2566762494 "The purpose of this PGN is to group the aftertreatment intermediate gas temperature and pressure messages for bank 2.";
CM_ SG_ 2566762494 Aftrtrtmnt2DslPrtcltFltrIntr3288 "Used to identify the applicable J1939-73 FMI detected in the diesel particulate filter intermediate gas temperature sensor ...";
CM_ SG_ 2566762494 Aftrtrtmnt2DslPrtcltFltrDltPrssP "Used to identify the applicable J1939-73 FMI detected in the diesel particulate filter differential pressure sensor by the ...";
CM_ SG_ 2566762494 Aftrtrtmnt2ExhstGsTmp2PrlmnryFMI "Used to identify the applicable J1939-73 FMI detected in the exhaust gas temperature 2 sensor by the manufacturer’s ...";
CM_ SG_ 2566762494 Aftrtrtmnt2DslPrtcltFltrDffPress "Exhaust differential pressure measured between the intake and exhaust of a diesel particulate filter in exhaust bank 2.";
CM_ SG_ 2566762494 Aftrtrtmnt2DslPrtcltFltrIntrmdtG "Temperature of engine combustion byproducts at a mid-point in the diesel particulate filter in exhaust bank 2.  (For a ...";
CM_ SG_ 2566762494 Aftertreatment2ExhaustGasTemp2 "The reading from the exhaust gas temperature sensor located midstream of the other two temperature sensors in the ...";
CM_ BO_ 2565870078 "The purpose of this PGN is to group the aftertreatment outlet sensor data for bank 2.  These values include the NOx, ...";
CM_ SG_ 2565870078 Aftrtrtmnt2OtltOxygnSnsrPrlmnryF "Used to identify the applicable J1939-73 FMI detected in the aftertreatment outlet oxygen sensor by the manufacturer’s ...";
CM_ SG_ 2565870078 NOxSensorATI2SelfdiagnosisStatus "Self-diagnosis result status for NOx sensor ATI2 (Aftertreatment Intake Bank 2) ...";
CM_ SG_ 2565870078 Aftrtrtmnt2OtltNOxSnsrPrlmnryFMI "Used to identify the applicable J1939-73 FMI detected in the aftertreatment outlet NOx sensor by the manufacturer’s ...";
CM_ SG_ 2565870078 Aftrtrtmnt2OtltGsSnsorHeaterCtrl "Indicates the heater status in the warm-up process.  Upon receiving a power-up command, the gas sensor ramps up ...";
CM_ SG_ 2565870078 Aftrtrtmnt2OtltGsSnsrHtrPrlmnryF "Used to identify the applicable J1939-73 FMI detected in the heater of the outlet exhaust gas sensor, either NOx or O2, by ...";
CM_ SG_ 2565870078 Aftrtrtmnt2OtltWdRngO2RdngStable "Indicates that the %O2 reading of the aftertreatment outlet gas sensor, either NOx or O2, is stable as determined by the ...";
CM_ SG_ 2565870078 Aftrtrtmnt2OtletNOxReadingStable "Indicates that the NOx reading of the aftertreatment outlet NOx sensor is stable as determined by the manufacturer’s ...";
CM_ SG_ 2565870078 Aftrtrtmnt2OutletGasSensorAtTemp "Indicates that the heater element of the aftertreatment outlet gas sensor, either NOx or O2, is within the manufacturer’s ...";
CM_ SG_ 2565870078 Aftrtrtmnt2OtltGsSnsrPowerStatus "Indicates that the power supplied to the aftertreatment outlet gas sensor, either NOx or O2, is within the manufacturer’s ...";
CM_ SG_ 2565870078 Aftertreatment2OutletO2 "The actual oxidation factor (%O2) of the gas within the exhaust stream.  For positive values, the parameter represents the ...";
CM_ SG_ 2565870078 Aftertreatment2OutletNOx "The amount of combined NO and NO2 in the exhaust entering the aftertreatment system measured by a NOx sensor at ...";
CM_ BO_ 2566762750 "The purpose of this PGN is to group the aftertreatment outlet gas temperature messages for bank 2.";
CM_ SG_ 2566762750 Aftrtrtmnt2DslPrtcltFltrExhstGsT "Used to identify the applicable J1939-73 FMI detected in the diesel particulate filter outlet gas temperature sensor by the ...";
CM_ SG_ 2566762750 Aftrtrtmnt2ExhstGsTmp3PrlmnryFMI "Used to identify the applicable J1939-73 FMI detected in the exhaust gas temperature 3 sensor by the manufacturer’s ...";
CM_ SG_ 2566762750 Aftrtrtmnt2DslPrtcltFltrOtltGsTm "Temperature of engine combustion byproducts leaving the diesel particulate filter exhaust in exhaust bank 2.  (For a ...";
CM_ SG_ 2566762750 Aftertreatment2ExhaustGasTemp3 "The reading from the exhaust gas temperature sensor located farthest downstream in the aftertreatment system in ...";
CM_ BO_ 2566748926 "This PGN contains information about the aftertreatment 2 (diesel particulate filter 2 soot and ash load).";
CM_ SG_ 2566748926 Aftrtrtmnt2DslPrtcltFltrStLdRgnr "This parameter indicates the value that will first cause DPF regeneration in aftertreatment 2. There may be multiple ...";
CM_ SG_ 2566748926 DslPrtcltFltr2TmSncLstActvRgnrtn "Indicates the time since the last active regeneration event of diesel particulate filter 2.";
CM_ SG_ 2566748926 DslPrtclateFilter2AshLoadPercent "Indicates the ash load percent of diesel particulate filter 2.  100% is the level at which diesel particulate filter ash service ...";
CM_ SG_ 2566748926 DslPrtclteFilter2SootLoadPercent "Indicates the soot load percent of diesel particulate filter 2.  100% is the level at which active diesel particulate filter ...";
CM_ BO_ 2566748414 "This PGN contains trip total information about the aftertreatment 2.";
CM_ SG_ 2566748414 Aftrtrtmnt2DslPrtcltFltrTrpN3748 "Total number of aftertreatment 2 diesel particulate filter active regeneration manual requests by the operator during the ...";
CM_ SG_ 2566748414 Aftrtrtmnt2DslPrtcltFltrTrpN3747 "Total number of aftertreatment 2 diesel particulate filter active regeneration inhibit requests by the operator during the ...";
CM_ SG_ 2566748414 Aftrtrtmnt2DslPrtcltFltrTrpN3746 "Total number of passive regenerations of the aftertreatment 2 diesel particulate filter during the current trip period.";
CM_ SG_ 2566748414 Aftrtrtmnt2DslPrtcltFltrTrpPssvR "Total amount of time that the aftertreatment 2 diesel particulate filter has been in passive regeneration during the current ...";
CM_ SG_ 2566748414 Aftrtrtmnt2DslPrtcltFltrTrpNmbrO "Total number of active regenerations of the aftertreatment 2 diesel particulate filter during the current trip period.";
CM_ SG_ 2566748414 Aftrtrtmnt2DslPrtcltFltrTrpDsbld "Total amount of time that aftertreatment 2 diesel particulate filter regeneration has been manually disabled during the ...";
CM_ SG_ 2566748414 Aftrtrtmnt2DslPrtcltFltrTrpActvR "Total amount of time that the aftertreatment 2 diesel particulate filter has been in active regeneration during the current ...";
CM_ SG_ 2566748414 Aftrtrtmnt2DslPrtcltFltrTrpFlUsd "Total amount of fuel used by the aftertreatment 2 diesel particulate filter during the current trip period.";
CM_ BO_ 2365428478 "Contains engine parameters related to operation.";
CM_ SG_ 2365428478 EngDerateRq "This parameter is a derate request made from the engine control system to an external system, where the engine is ...";
CM_ SG_ 2365428478 EngEmergencyShutdownIndication "A signal issued by the engine control system to a user or external system indicating that it is immediately shutting the ...";
CM_ SG_ 2365428478 EngControlledShutdownRq "A signal issued by the engine control system to a user or external system requesting for a controlled shutdown.  This ...";
CM_ SG_ 2365428478 EngCoolantCirculatingPumpCtrl "Control setting for an electrically actuated engine coolant circulating pump.";
CM_ SG_ 2365428478 EngBlock_CoolantPreheaterCtrl "Control setting for an electrically actuated engine block or coolant pre-heating device.";
CM_ SG_ 2365428478 EngElctrclSystmPwrCnsrvationCtrl "Control setting for cutting power to various devices when the engine is not in use.  Useful if it is desired to keep the ...";
CM_ SG_ 2365428478 EngOilPreheaterCtrl "Control setting for an electrically actuated oil pre-heating device.";
CM_ SG_ 2365428478 EngOilPrimingPumpCtrl "This control is used to activate a pump that lubricates the engine, particularly prior to initial engine startup.";
CM_ SG_ 2365428478 EngFuelShutoffValveLeakTestCtrl "Control setting for fuel shutoff valve proving system test.  Typically, this type of system can only be used with a dual fuel ...";
CM_ SG_ 2365428478 EngFuelShutoff2Ctrl "Control setting for fuel shutoff 2.  First instance is SPN 632.  For a dual fuel shutoff system, this SPN is representative of ...";
CM_ SG_ 2365428478 EngFuelShutoff1Ctrl "Control setting for fuel shutoff 1.  The second instance is SPN 2807.  For a single fuel shutoff system, this represents its ...";
CM_ SG_ 2365428478 EngFuelShutoffVentCtrl "Control setting for a fuel shutoff vent.  Typically, for a dual fuel shutoff system, the vent line is located between them and ...";
CM_ SG_ 2365428478 TimeRemainingInEngOperatingState "This parameter is used to indicate the time remaining in the current engine operating state, based on the state defined in ...";
CM_ SG_ 2365428478 FuelPumpPrimerCtrl "Parameter used to activate or deactivate a priming system on the fuel transfer system. The fuel priming system is a ...";
CM_ SG_ 2365428478 EngOperatingState "This parameter is used to indicate the current state, or mode, of operation by the engine.  This is a status parameter.";
CM_ BO_ 2566743806 "Engine temperatures ...";
CM_ SG_ 2566743806 EngExhstGsRcrcltn1MxerIntakeTemp "The temperature of the EGR gas entering the intake mixer, measured after the intake throttle when provided.";
CM_ SG_ 2566743806 EngExhstVlvActationSystemOilTemp "The temperature of the oil in the hydraulic system that powers the engine exhaust valve actuation system ...";
CM_ SG_ 2566743806 EngCoolantThermostatOpening "The current position of the Thermostat used to regulate the temperature of the engine coolant.  0% represents the ...";
CM_ SG_ 2566743806 EngCoolantPumpOutletTemp "The actual value of engine coolant temperature at the coolant pump outlet ...";
CM_ SG_ 2566743806 EngCoolantTemp2 "Second temperature of liquid found in the engine cooling system.   See also SPN 110.";
CM_ BO_ 2499635454 "Gross Combination Vehicle Weight ...";
CM_ SG_ 2499635454 NetVehicleWeightChange "Identifies the net vehicle weight change from the time of last vehicle net weight zeroing.";
CM_ SG_ 2499635454 GrossCombinationWeight "Total weight of the truck and all the trailers with on-board scales.";
CM_ BO_ 2550660862 "The measured load sense pressure and pilot pressure of a valve.  May also include the load sense and supply pressure ...";
CM_ SG_ 2550660862 ValveAssemblySupplyPress "Pressure of the hydraulic supply port to a valve assembly.";
CM_ SG_ 2550660862 ValveAssemblyLoadSensePress "The maximum pressure of a valve assembly's current collective load sense pressures where a valve assembly can ...";
CM_ SG_ 2550660862 ValvePilotPress "Pressure of a valve's pilot supply port.";
CM_ SG_ 2550660862 ValveLoadSensePress "The maximum of the currently measured pressures of a valve's work port A and work port B.";
CM_ BO_ 2566805758 "Used for bellow pressure information ...";
CM_ SG_ 2566805758 BellowPressRearAxleRight "Information of the pressure of the air suspension bellow at the right side of the rear axle ...";
CM_ SG_ 2566805758 BellowPressRearAxleLeft "Information of the pressure of the air suspension bellow at the left side of the rear axle ...";
CM_ SG_ 2566805758 BellowPressFrontAxleRight "Information of the pressure of the air suspension bellow at the right side of the front axle ...";
CM_ SG_ 2566805758 BellowPressFrontAxleLeft "Information of the pressure of the air suspension bellow at the left side of the front axle ...";
CM_ BO_ 2566806014 "Used for height information ...";
CM_ SG_ 2566806014 RelativeLevelRearAxleRight "Information of the height at the left side of the rear axle referred to normal level 1.  For explanations of normal level 1 see ...";
CM_ SG_ 2566806014 RelativeLevelRearAxleLeft "Information of the height at the left side of the rear axle referred to normal level 1.  For explanations of normal level 1 see ...";
CM_ SG_ 2566806014 RelativeLevelFrontAxleRight "Information of the height at the right side of the front axle referred to normal level 1.  For explanations of normal level 1 ...";
CM_ SG_ 2566806014 RelativeLevelFrontAxleLeft "Information of the height at the left side of the front axle referred to normal level 1.  For explanations of normal level 1 see SPN 1734 - Nominal Level Front Axle.";
CM_ BO_ 2362638078 "Used for suspension control ...";
CM_ SG_ 2362638078 MemoryLevelRq "Signal which indicates that the air suspension control requests a memory level or a memory level shall be stored.";
CM_ SG_ 2362638078 PrhbitAutomaticAirSuspensionCtrl "This parameter is an internal request to the air suspension control system to prohibit automatic air suspension control.  If ...";
CM_ SG_ 2362638078 SpeedDependentLevelCtrlRq "This parameter activates speed dependent level control in suspension system.";
CM_ SG_ 2362638078 AllowLevelCtrlDuringBrakingCmd "This parameter overides the inhibit of level control during braking.";
CM_ SG_ 2362638078 ProhibitAirSuspensionCtrl "This parameter is an external request to the air suspension control system to prohibit all air suspension control.  If the ...";
CM_ SG_ 2362638078 KneelingCmdRearAxle "Command signal to activate the kneeling functionality at the rear axle of the vehicle.";
CM_ SG_ 2362638078 KneelingCmdFrontAxle "Command signal to activate the kneeling functionality at the front axle of the vehicle ...";
CM_ SG_ 2362638078 DamperStiffnessRqLift_TagAxle "Demand value for the shock absorber control at the lift or tag axle ...";
CM_ SG_ 2362638078 DamperStiffnessRqRearAxle "Demand value for the shock absorber control at the rear  axle.";
CM_ SG_ 2362638078 DamperStiffnessRqFrontAxle "Demand value for the shock absorber control at the front axle.";
CM_ SG_ 2362638078 LiftAxle2PosCmd "Signal to command the position / load condition of lift / tag axle #2.  Numbering of lift/tag axles starts at front axle.";
CM_ SG_ 2362638078 LiftAxle1PosCmd "Signal to command the position/load condition of lift/tag axle #1.  Numbering of lift/tag axles starts at front axle.";
CM_ SG_ 2362638078 LevelCtrlModeRq "Command signal to activate a level control mode ...";
CM_ SG_ 2362638078 NominalLevelRqRearAxle "Command signal to activate a level of the rear axle programmed and/or memorized in the ECU.  For explanations of ...";
CM_ SG_ 2362638078 NominalLevelRqFrontAxle "Command signal to activate a level of the front axle programmed and/or memorized in the ECU   For explanations of ...";
CM_ SG_ 2362638078 KneelingCtrlModeRq "Command signal to select the kneeling functionality ...";
CM_ SG_ 2362638078 KneelingRqRightSide "Command signal to activate the kneeling functionality on the right side of the vehicle ...";
CM_ SG_ 2362638078 KneelingRqLeftSide "Command signal to activate the kneeling functionality on the left side of the vehicle ...";
CM_ SG_ 2362638078 AutomaticTractionHelp "This signal enables the traction help (load transfer) in case of an active ASR function ...";
BA_DEF_ SG_  "SigType" ENUM  "Default","Range","RangeSigned","ASCII","Discrete","Control","ReferencePGN","DTC","StringDelimiter","StringLength","StringLengthControl";
BA_DEF_ SG_  "GenSigStartValue" INT 0 10000;
BA_DEF_ SG_  "GenSigSendType" ENUM  "Cyclic","OnWrite","OnWriteWithRepetition","OnChange","OnChangeWithRepetition","IfActive","IfActiveWithRepetition","NoSigSendType";
BA_DEF_ SG_  "GenSigILSupport" ENUM  "No","Yes";
BA_DEF_ SG_  "GenSigEVName" STRING ;
BA_DEF_ SG_  "SPN" INT 0 524287;
BA_DEF_ BO_  "GenMsgStartDelayTime" INT 0 100000;
BA_DEF_ BO_  "GenMsgILSupport" ENUM  "No","Yes";
BA_DEF_ BO_  "GenMsgRequestable" INT 0 1;
BA_DEF_ BO_  "GenMsgSendType" ENUM  "cyclic","NotUsed","NotUsed","NotUsed","NotUsed","NotUsed","NotUsed","IfActive","noMsgSendType";
BA_DEF_ BO_  "VFrameFormat" ENUM  "StandardCAN","ExtendedCAN","reserved","J1939PG";
BA_DEF_ BO_  "GenMsgCycleTime" INT 0 3600000;
BA_DEF_ SG_  "SystemSignalLongSymbol" STRING ;
BA_DEF_DEF_  "SigType" "Default";
BA_DEF_DEF_  "GenSigStartValue" 0;
BA_DEF_DEF_  "GenSigSendType" "NoSigSendType";
BA_DEF_DEF_  "GenSigILSupport" "Yes";
BA_DEF_DEF_  "GenSigEVName" "Env@Nodename_@Signame";
BA_DEF_DEF_  "SPN" 0;
BA_DEF_DEF_  "GenMsgStartDelayTime" 0;
BA_DEF_DEF_  "GenMsgILSupport" "Yes";
BA_DEF_DEF_  "GenMsgRequestable" 1;
BA_DEF_DEF_  "GenMsgSendType" "noMsgSendType";
BA_DEF_DEF_  "VFrameFormat" "J1939PG";
BA_DEF_DEF_  "GenMsgCycleTime" 0;
BA_DEF_DEF_  "SystemSignalLongSymbol" "";
BA_ "GenMsgSendType" BO_ 2566726398 0;
BA_ "GenMsgCycleTime" BO_ 2566726398 500;
BA_ "GenMsgSendType" BO_ 2566809342 0;
BA_ "GenMsgCycleTime" BO_ 2566809342 1000;
BA_ "GenMsgSendType" BO_ 2365446910 0;
BA_ "GenMsgCycleTime" BO_ 2365446910 100;
BA_ "GenMsgSendType" BO_ 2365446398 0;
BA_ "GenMsgCycleTime" BO_ 2365446398 100;
BA_ "GenMsgSendType" BO_ 2365445886 0;
BA_ "GenMsgCycleTime" BO_ 2365445886 100;
BA_ "GenMsgSendType" BO_ 2566847230 0;
BA_ "GenMsgCycleTime" BO_ 2566847230 1000;
BA_ "GenMsgSendType" BO_ 2566848254 0;
BA_ "GenMsgCycleTime" BO_ 2566848254 1000;
BA_ "GenMsgSendType" BO_ 2566725886 0;
BA_ "GenMsgCycleTime" BO_ 2566725886 500;
BA_ "GenMsgSendType" BO_ 2432520958 0;
BA_ "GenMsgCycleTime" BO_ 2432520958 1000;
BA_ "GenMsgSendType" BO_ 2560425726 0;
BA_ "GenMsgCycleTime" BO_ 2560425726 100;
BA_ "GenMsgSendType" BO_ 2560491262 0;
BA_ "GenMsgCycleTime" BO_ 2560491262 100;
BA_ "GenMsgSendType" BO_ 2349399806 0;
BA_ "GenMsgCycleTime" BO_ 2349399806 20;
BA_ "GenMsgSendType" BO_ 2566758398 0;
BA_ "GenMsgCycleTime" BO_ 2566758398 500;
BA_ "GenMsgSendType" BO_ 2566745598 0;
BA_ "GenMsgCycleTime" BO_ 2566745598 500;
BA_ "GenMsgSendType" BO_ 2566758910 0;
BA_ "GenMsgCycleTime" BO_ 2566758910 500;
BA_ "GenMsgSendType" BO_ 2566743550 0;
BA_ "GenMsgCycleTime" BO_ 2566743550 500;
BA_ "GenMsgSendType" BO_ 2566753534 0;
BA_ "GenMsgCycleTime" BO_ 2566753534 500;
BA_ "GenMsgSendType" BO_ 2565869310 0;
BA_ "GenMsgCycleTime" BO_ 2565869310 50;
BA_ "GenMsgSendType" BO_ 2566763774 0;
BA_ "GenMsgCycleTime" BO_ 2566763774 500;
BA_ "GenMsgSendType" BO_ 2633934846 0;
BA_ "GenMsgCycleTime" BO_ 2633934846 1000;
BA_ "GenMsgSendType" BO_ 2362572542 2;
BA_ "GenMsgCycleTime" BO_ 2362572542 100;
BA_ "GenMsgSendType" BO_ 2365478910 0;
BA_ "GenMsgCycleTime" BO_ 2365478910 100;
BA_ "GenMsgSendType" BO_ 2566763262 0;
BA_ "GenMsgCycleTime" BO_ 2566763262 500;
BA_ "GenMsgSendType" BO_ 2565869566 0;
BA_ "GenMsgCycleTime" BO_ 2565869566 50;
BA_ "GenMsgSendType" BO_ 2566763518 0;
BA_ "GenMsgCycleTime" BO_ 2566763518 500;
BA_ "GenMsgSendType" BO_ 2566758142 0;
BA_ "GenMsgCycleTime" BO_ 2566758142 500;
BA_ "GenMsgSendType" BO_ 2566745342 0;
BA_ "GenMsgCycleTime" BO_ 2566745342 500;
BA_ "GenMsgSendType" BO_ 2566758654 0;
BA_ "GenMsgCycleTime" BO_ 2566758654 500;
BA_ "GenMsgSendType" BO_ 2566753278 0;
BA_ "GenMsgCycleTime" BO_ 2566753278 500;
BA_ "GenMsgSendType" BO_ 2565869822 0;
BA_ "GenMsgCycleTime" BO_ 2565869822 50;
BA_ "GenMsgSendType" BO_ 2566763006 0;
BA_ "GenMsgCycleTime" BO_ 2566763006 500;
BA_ "GenMsgSendType" BO_ 2566762494 0;
BA_ "GenMsgCycleTime" BO_ 2566762494 500;
BA_ "GenMsgSendType" BO_ 2565870078 0;
BA_ "GenMsgCycleTime" BO_ 2565870078 50;
BA_ "GenMsgSendType" BO_ 2566762750 0;
BA_ "GenMsgCycleTime" BO_ 2566762750 500;
BA_ "GenMsgSendType" BO_ 2365428478 0;
BA_ "GenMsgCycleTime" BO_ 2365428478 250;
BA_ "GenMsgSendType" BO_ 2566743806 0;
BA_ "GenMsgCycleTime" BO_ 2566743806 1000;
BA_ "GenMsgSendType" BO_ 2550660862 0;
BA_ "GenMsgCycleTime" BO_ 2550660862 100;
BA_ "GenMsgSendType" BO_ 2566805758 0;
BA_ "GenMsgCycleTime" BO_ 2566805758 100;
BA_ "GenMsgSendType" BO_ 2566806014 0;
BA_ "GenMsgCycleTime" BO_ 2566806014 100;
BA_ "GenMsgSendType" BO_ 2362638078 0;
BA_ "GenMsgCycleTime" BO_ 2362638078 100;
BA_ "SPN" SG_ 2566726398 Aftrtrtmnt1GsOxdtnCtlystDffPrssP 4758;
BA_ "SPN" SG_ 2566726398 Aftrtrtmnt1GsOxdtnCtlystOtlt4757 4757;
BA_ "SPN" SG_ 2566726398 Aftrtrtmnt1GsOxdtnCtlystIntk4756 4756;
BA_ "SigType" SG_ 2566726398 Aftrtrtmnt1GsOxdtnCtlystDffPress 1;
BA_ "SPN" SG_ 2566726398 Aftrtrtmnt1GsOxdtnCtlystDffPress 4755;
BA_ "SigType" SG_ 2566726398 Aftrtrtmnt1GsOxdtnCtlystOtltGsTm 1;
BA_ "SPN" SG_ 2566726398 Aftrtrtmnt1GsOxdtnCtlystOtltGsTm 4754;
BA_ "SigType" SG_ 2566726398 Aftrtrtmnt1GsOxdtnCtlystIntkGsTm 1;
BA_ "SPN" SG_ 2566726398 Aftrtrtmnt1GsOxdtnCtlystIntkGsTm 4753;
BA_ "SigType" SG_ 2566742270 FailureSpecificB1Counter 1;
BA_ "SPN" SG_ 2566742270 FailureSpecificB1Counter 4147;
BA_ "SPN" SG_ 2566742270 FailureModeIdentifier1 1215;
BA_ "SPN" SG_ 2566742270 SPN1 1214;
BA_ "SigType" SG_ 2566742526 SysGreatestB1Counter 1;
BA_ "SPN" SG_ 2566742526 SysGreatestB1Counter 4146;
BA_ "SigType" SG_ 2566742526 SysCumulativeContinuousMITime 1;
BA_ "SPN" SG_ 2566742526 SysCumulativeContinuousMITime 4145;
BA_ "SigType" SG_ 2566742782 RegulationDescription 8;
BA_ "SPN" SG_ 2566742782 RegulationDescription 4144;
BA_ "SigType" SG_ 2566743038 SysIncompleteMonitorCount 1;
BA_ "SPN" SG_ 2566743038 SysIncompleteMonitorCount 4143;
BA_ "SPN" SG_ 2566743038 SysMalIndActivationMode 4142;
BA_ "SigType" SG_ 2566743038 SysMalIndDisplayStrategy 4;
BA_ "SPN" SG_ 2566743038 SysMalIndDisplayStrategy 4141;
BA_ "SigType" SG_ 2566743038 SysContinuousMalfunctionInd 4;
BA_ "SPN" SG_ 2566743038 SysContinuousMalfunctionInd 4140;
BA_ "SigType" SG_ 2566743038 SysNonRoadworthyCompCount 1;
BA_ "SPN" SG_ 2566743038 SysNonRoadworthyCompCount 4139;
BA_ "SigType" SG_ 2566743294 VehicleCurrentMIAccumTime 1;
BA_ "SPN" SG_ 2566743294 VehicleCurrentMIAccumTime 4138;
BA_ "SigType" SG_ 2566743294 VehicleIncompleteMonitorCount 1;
BA_ "SPN" SG_ 2566743294 VehicleIncompleteMonitorCount 4137;
BA_ "SigType" SG_ 2566743294 VehicleMalfunctionIndActMode 4;
BA_ "SPN" SG_ 2566743294 VehicleMalfunctionIndActMode 4136;
BA_ "SigType" SG_ 2566743294 VehicleMalfunctionIndStrategy 4;
BA_ "SPN" SG_ 2566743294 VehicleMalfunctionIndStrategy 4135;
BA_ "SigType" SG_ 2566743294 VehicleContinuousMalfunctionInd 4;
BA_ "SPN" SG_ 2566743294 VehicleContinuousMalfunctionInd 4134;
BA_ "SigType" SG_ 2566743294 VehicleNonRoadworthyCompCount 1;
BA_ "SPN" SG_ 2566743294 VehicleNonRoadworthyCompCount 4133;
BA_ "SigType" SG_ 2560687870 PMNTEDeficiencyAreaStatus 4;
BA_ "SPN" SG_ 2560687870 PMNTEDeficiencyAreaStatus 4132;
BA_ "SigType" SG_ 2560687870 MnfcPMNTECarveOutAreaStatus 4;
BA_ "SPN" SG_ 2560687870 MnfcPMNTECarveOutAreaStatus 4131;
BA_ "SigType" SG_ 2560687870 PMNTEControlAreaStatus 4;
BA_ "SPN" SG_ 2560687870 PMNTEControlAreaStatus 4130;
BA_ "SigType" SG_ 2560687870 NOxNTEDeficiencyAreaStatus 4;
BA_ "SPN" SG_ 2560687870 NOxNTEDeficiencyAreaStatus 4129;
BA_ "SigType" SG_ 2560687870 MnfcNOxNTECarveOutAreaStatus 4;
BA_ "SPN" SG_ 2560687870 MnfcNOxNTECarveOutAreaStatus 4128;
BA_ "SigType" SG_ 2560687870 NOxNTEControlAreaStatus 4;
BA_ "SPN" SG_ 2560687870 NOxNTEControlAreaStatus 4127;
BA_ "SigType" SG_ 2292317950 AECDEngineHours1Timer2 1;
BA_ "SPN" SG_ 2292317950 AECDEngineHours1Timer2 4126;
BA_ "SigType" SG_ 2292317950 AECDEngineHours1Timer1 1;
BA_ "SPN" SG_ 2292317950 AECDEngineHours1Timer1 4125;
BA_ "SigType" SG_ 2292317950 AECDNumber1 1;
BA_ "SPN" SG_ 2292317950 AECDNumber1 4124;
BA_ "SigType" SG_ 2566809342 BatteryMainSwitchHoldState 4;
BA_ "SPN" SG_ 2566809342 BatteryMainSwitchHoldState 1681;
BA_ "SigType" SG_ 2365446910 Joystick3XAxisDetentPosStatus 4;
BA_ "SPN" SG_ 2365446910 Joystick3XAxisDetentPosStatus 2754;
BA_ "SigType" SG_ 2365446910 Joystick3Button9PressedStatus 4;
BA_ "SPN" SG_ 2365446910 Joystick3Button9PressedStatus 2767;
BA_ "SigType" SG_ 2365446910 Joystick3Button10PressedStatus 4;
BA_ "SPN" SG_ 2365446910 Joystick3Button10PressedStatus 2768;
BA_ "SigType" SG_ 2365446910 Joystick3Button11PressedStatus 4;
BA_ "SPN" SG_ 2365446910 Joystick3Button11PressedStatus 2769;
BA_ "SigType" SG_ 2365446910 Joystick3Button12PressedStatus 4;
BA_ "SPN" SG_ 2365446910 Joystick3Button12PressedStatus 2770;
BA_ "SigType" SG_ 2365446910 Joystick3YAxisDetentPosStatus 4;
BA_ "SPN" SG_ 2365446910 Joystick3YAxisDetentPosStatus 2755;
BA_ "SPN" SG_ 2365446910 Joystick3YAxisPos 2735;
BA_ "SigType" SG_ 2365446910 Jystck3YAxsLvrFrwrdPstvPosStatus 4;
BA_ "SPN" SG_ 2365446910 Jystck3YAxsLvrFrwrdPstvPosStatus 2740;
BA_ "SigType" SG_ 2365446910 Jystck3YAxsLvrBckNgtivePosStatus 4;
BA_ "SPN" SG_ 2365446910 Jystck3YAxsLvrBckNgtivePosStatus 2745;
BA_ "SigType" SG_ 2365446910 Joystick3YAxisNeutralPosStatus 4;
BA_ "SPN" SG_ 2365446910 Joystick3YAxisNeutralPosStatus 2750;
BA_ "SPN" SG_ 2365446910 Joystick3XAxisPos 2734;
BA_ "SigType" SG_ 2365446910 Jystck3XAxsLvrRghtPstvePosStatus 4;
BA_ "SPN" SG_ 2365446910 Jystck3XAxsLvrRghtPstvePosStatus 2739;
BA_ "SigType" SG_ 2365446910 Jystck3XAxsLvrLftNgtivePosStatus 4;
BA_ "SPN" SG_ 2365446910 Jystck3XAxsLvrLftNgtivePosStatus 2744;
BA_ "SigType" SG_ 2365446910 Joystick3XAxisNeutralPosStatus 4;
BA_ "SPN" SG_ 2365446910 Joystick3XAxisNeutralPosStatus 2749;
BA_ "SigType" SG_ 2365446910 Joystick3Button5PressedStatus 4;
BA_ "SPN" SG_ 2365446910 Joystick3Button5PressedStatus 2763;
BA_ "SigType" SG_ 2365446910 Joystick3Button6PressedStatus 4;
BA_ "SPN" SG_ 2365446910 Joystick3Button6PressedStatus 2764;
BA_ "SigType" SG_ 2365446910 Joystick3Button7PressedStatus 4;
BA_ "SPN" SG_ 2365446910 Joystick3Button7PressedStatus 2765;
BA_ "SigType" SG_ 2365446910 Joystick3Button8PressedStatus 4;
BA_ "SPN" SG_ 2365446910 Joystick3Button8PressedStatus 2766;
BA_ "SigType" SG_ 2365446910 Joystick3Button1PressedStatus 4;
BA_ "SPN" SG_ 2365446910 Joystick3Button1PressedStatus 2759;
BA_ "SigType" SG_ 2365446910 Joystick3Button2PressedStatus 4;
BA_ "SPN" SG_ 2365446910 Joystick3Button2PressedStatus 2760;
BA_ "SigType" SG_ 2365446910 Joystick3Button3PressedStatus 4;
BA_ "SPN" SG_ 2365446910 Joystick3Button3PressedStatus 2761;
BA_ "SigType" SG_ 2365446910 Joystick3Button4PressedStatus 4;
BA_ "SPN" SG_ 2365446910 Joystick3Button4PressedStatus 2762;
BA_ "SigType" SG_ 2365446398 Joystick2XAxisDetentPosStatus 4;
BA_ "SPN" SG_ 2365446398 Joystick2XAxisDetentPosStatus 2717;
BA_ "SigType" SG_ 2365446398 Joystick2YAxisDetentPosStatus 4;
BA_ "SPN" SG_ 2365446398 Joystick2YAxisDetentPosStatus 2718;
BA_ "SPN" SG_ 2365446398 Joystick2YAxisPos 2698;
BA_ "SigType" SG_ 2365446398 Jystck2YAxsLvrFrwrdPstvPosStatus 4;
BA_ "SPN" SG_ 2365446398 Jystck2YAxsLvrFrwrdPstvPosStatus 2703;
BA_ "SigType" SG_ 2365446398 Jystck2YAxsLvrBckNgtivePosStatus 4;
BA_ "SPN" SG_ 2365446398 Jystck2YAxsLvrBckNgtivePosStatus 2708;
BA_ "SigType" SG_ 2365446398 Joystick2YAxisNeutralPosStatus 4;
BA_ "SPN" SG_ 2365446398 Joystick2YAxisNeutralPosStatus 2713;
BA_ "SPN" SG_ 2365446398 Joystick2XAxisPos 2697;
BA_ "SigType" SG_ 2365446398 Jystck2XAxsLvrRghtPstvePosStatus 4;
BA_ "SPN" SG_ 2365446398 Jystck2XAxsLvrRghtPstvePosStatus 2702;
BA_ "SigType" SG_ 2365446398 Jystck2XAxsLvrLftNgtivePosStatus 4;
BA_ "SPN" SG_ 2365446398 Jystck2XAxsLvrLftNgtivePosStatus 2707;
BA_ "SigType" SG_ 2365446398 Joystick2XAxisNeutralPosStatus 4;
BA_ "SPN" SG_ 2365446398 Joystick2XAxisNeutralPosStatus 2712;
BA_ "SigType" SG_ 2365446398 Joystick2Button9PressedStatus 4;
BA_ "SPN" SG_ 2365446398 Joystick2Button9PressedStatus 2730;
BA_ "SigType" SG_ 2365446398 Joystick2Button10PressedStatus 4;
BA_ "SPN" SG_ 2365446398 Joystick2Button10PressedStatus 2731;
BA_ "SigType" SG_ 2365446398 Joystick2Button11PressedStatus 4;
BA_ "SPN" SG_ 2365446398 Joystick2Button11PressedStatus 2732;
BA_ "SigType" SG_ 2365446398 Joystick2Button12PressedStatus 4;
BA_ "SPN" SG_ 2365446398 Joystick2Button12PressedStatus 2733;
BA_ "SigType" SG_ 2365446398 Joystick2Button5PressedStatus 4;
BA_ "SPN" SG_ 2365446398 Joystick2Button5PressedStatus 2726;
BA_ "SigType" SG_ 2365446398 Joystick2Button6PressedStatus 4;
BA_ "SPN" SG_ 2365446398 Joystick2Button6PressedStatus 2727;
BA_ "SigType" SG_ 2365446398 Joystick2Button7PressedStatus 4;
BA_ "SPN" SG_ 2365446398 Joystick2Button7PressedStatus 2728;
BA_ "SigType" SG_ 2365446398 Joystick2Button8PressedStatus 4;
BA_ "SPN" SG_ 2365446398 Joystick2Button8PressedStatus 2729;
BA_ "SigType" SG_ 2365446398 Joystick2Button1PressedStatus 4;
BA_ "SPN" SG_ 2365446398 Joystick2Button1PressedStatus 2722;
BA_ "SigType" SG_ 2365446398 Joystick2Button2PressedStatus 4;
BA_ "SPN" SG_ 2365446398 Joystick2Button2PressedStatus 2723;
BA_ "SigType" SG_ 2365446398 Joystick2Button3PressedStatus 4;
BA_ "SPN" SG_ 2365446398 Joystick2Button3PressedStatus 2724;
BA_ "SigType" SG_ 2365446398 Joystick2Button4PressedStatus 4;
BA_ "SPN" SG_ 2365446398 Joystick2Button4PressedStatus 2725;
BA_ "SigType" SG_ 2365445886 Joystick1XAxisDetentPosStatus 4;
BA_ "SPN" SG_ 2365445886 Joystick1XAxisDetentPosStatus 2680;
BA_ "SigType" SG_ 2365445886 Joystick1YAxisDetentPosStatus 4;
BA_ "SPN" SG_ 2365445886 Joystick1YAxisDetentPosStatus 2681;
BA_ "SPN" SG_ 2365445886 Joystick1YAxisPos 2661;
BA_ "SigType" SG_ 2365445886 Jystck1YAxsLvrFrwrdPstvPosStatus 4;
BA_ "SPN" SG_ 2365445886 Jystck1YAxsLvrFrwrdPstvPosStatus 2666;
BA_ "SigType" SG_ 2365445886 Jystck1YAxsLvrBckNgtivePosStatus 4;
BA_ "SPN" SG_ 2365445886 Jystck1YAxsLvrBckNgtivePosStatus 2671;
BA_ "SigType" SG_ 2365445886 Joystick1YAxisNeutralPosStatus 4;
BA_ "SPN" SG_ 2365445886 Joystick1YAxisNeutralPosStatus 2676;
BA_ "SPN" SG_ 2365445886 Joystick1XAxisPos 2660;
BA_ "SigType" SG_ 2365445886 Joystick1Button9PressedStatus 4;
BA_ "SPN" SG_ 2365445886 Joystick1Button9PressedStatus 2693;
BA_ "SigType" SG_ 2365445886 Joystick1Button10PressedStatus 4;
BA_ "SPN" SG_ 2365445886 Joystick1Button10PressedStatus 2694;
BA_ "SigType" SG_ 2365445886 Joystick1Button11PressedStatus 4;
BA_ "SPN" SG_ 2365445886 Joystick1Button11PressedStatus 2695;
BA_ "SigType" SG_ 2365445886 Joystick1Button12PressedStatus 4;
BA_ "SPN" SG_ 2365445886 Joystick1Button12PressedStatus 2696;
BA_ "SigType" SG_ 2365445886 Joystick1Button5PressedStatus 4;
BA_ "SPN" SG_ 2365445886 Joystick1Button5PressedStatus 2689;
BA_ "SigType" SG_ 2365445886 Joystick1Button6PressedStatus 4;
BA_ "SPN" SG_ 2365445886 Joystick1Button6PressedStatus 2690;
BA_ "SigType" SG_ 2365445886 Joystick1Button7PressedStatus 4;
BA_ "SPN" SG_ 2365445886 Joystick1Button7PressedStatus 2691;
BA_ "SigType" SG_ 2365445886 Joystick1Button8PressedStatus 4;
BA_ "SPN" SG_ 2365445886 Joystick1Button8PressedStatus 2692;
BA_ "SigType" SG_ 2365445886 Joystick1Button1PressedStatus 4;
BA_ "SPN" SG_ 2365445886 Joystick1Button1PressedStatus 2685;
BA_ "SigType" SG_ 2365445886 Joystick1Button2PressedStatus 4;
BA_ "SPN" SG_ 2365445886 Joystick1Button2PressedStatus 2686;
BA_ "SigType" SG_ 2365445886 Joystick1Button3PressedStatus 4;
BA_ "SPN" SG_ 2365445886 Joystick1Button3PressedStatus 2687;
BA_ "SigType" SG_ 2365445886 Joystick1Button4PressedStatus 4;
BA_ "SPN" SG_ 2365445886 Joystick1Button4PressedStatus 2688;
BA_ "SigType" SG_ 2365445886 Jystck1XAxsLvrRghtPstvePosStatus 4;
BA_ "SPN" SG_ 2365445886 Jystck1XAxsLvrRghtPstvePosStatus 2665;
BA_ "SigType" SG_ 2365445886 Jystck1XAxsLvrLftNgtivePosStatus 4;
BA_ "SPN" SG_ 2365445886 Jystck1XAxsLvrLftNgtivePosStatus 2670;
BA_ "SigType" SG_ 2365445886 Joystick1XAxisNeutralPosStatus 4;
BA_ "SPN" SG_ 2365445886 Joystick1XAxisNeutralPosStatus 2675;
BA_ "SigType" SG_ 2566847230 ParkingBrakeRedWarningSignal 5;
BA_ "SPN" SG_ 2566847230 ParkingBrakeRedWarningSignal 3557;
BA_ "SigType" SG_ 2566847230 ParkBrakeReleaseInhibitStatus 4;
BA_ "SPN" SG_ 2566847230 ParkBrakeReleaseInhibitStatus 3808;
BA_ "SigType" SG_ 2566847230 ParkingBrakeActuator 4;
BA_ "SPN" SG_ 2566847230 ParkingBrakeActuator 619;
BA_ "SigType" SG_ 2566847230 BrakeSecondPress 1;
BA_ "SPN" SG_ 2566847230 BrakeSecondPress 118;
BA_ "SigType" SG_ 2566847230 BrakePrimaryPress 1;
BA_ "SPN" SG_ 2566847230 BrakePrimaryPress 117;
BA_ "SigType" SG_ 2566847230 BrakeAppPress 1;
BA_ "SPN" SG_ 2566847230 BrakeAppPress 116;
BA_ "SigType" SG_ 2566848254 AuxPumpPress 1;
BA_ "SPN" SG_ 2566848254 AuxPumpPress 73;
BA_ "SPN" SG_ 2566725886 Aftrtrtmnt1DslOxdtnCtlystDff4770 4770;
BA_ "SPN" SG_ 2566725886 Aftrtrtmnt1DslOxdtnCtlystOtl4769 4769;
BA_ "SPN" SG_ 2566725886 Aftrtrtmnt1DslOxdtnCtlystInt4768 4768;
BA_ "SigType" SG_ 2566725886 Aftrtrtmnt1DslOxdtnCtlystDffPrss 1;
BA_ "SPN" SG_ 2566725886 Aftrtrtmnt1DslOxdtnCtlystDffPrss 4767;
BA_ "SigType" SG_ 2566725886 Aftrtrtmnt1DslOxdtnCtlystOtltGsT 1;
BA_ "SPN" SG_ 2566725886 Aftrtrtmnt1DslOxdtnCtlystOtltGsT 4766;
BA_ "SigType" SG_ 2566725886 Aftrtrtmnt1DslOxdtnCtlystIntkGsT 1;
BA_ "SPN" SG_ 2566725886 Aftrtrtmnt1DslOxdtnCtlystIntkGsT 4765;
BA_ "SigType" SG_ 2560884478 DTCWarnLampSupportStatus 4;
BA_ "SPN" SG_ 2560884478 DTCWarnLampSupportStatus 4115;
BA_ "SigType" SG_ 2560884478 DTCWarnLampSupportFlash 4;
BA_ "SPN" SG_ 2560884478 DTCWarnLampSupportFlash 4119;
BA_ "SigType" SG_ 2560884478 DTCStopLampSupportStatus 4;
BA_ "SPN" SG_ 2560884478 DTCStopLampSupportStatus 4114;
BA_ "SigType" SG_ 2560884478 DTCStopLampSupportFlash 4;
BA_ "SPN" SG_ 2560884478 DTCStopLampSupportFlash 4118;
BA_ "SigType" SG_ 2560884478 DTCProtectLampSupportStatus 4;
BA_ "SPN" SG_ 2560884478 DTCProtectLampSupportStatus 4116;
BA_ "SigType" SG_ 2560884478 DTCProtectLampSupportFlash 4;
BA_ "SPN" SG_ 2560884478 DTCProtectLampSupportFlash 4120;
BA_ "SPN" SG_ 2560884478 DTCMilSupportStatus 4113;
BA_ "SPN" SG_ 2560884478 DTCMilSupportFlash 4117;
BA_ "SigType" SG_ 2560884478 DTC1 7;
BA_ "SPN" SG_ 2560360190 DataDictionaryMethod 4181;
BA_ "SPN" SG_ 2560360190 DataDictionaryManufacturerCode 4180;
BA_ "SPN" SG_ 2566736126 EngExhstGsOxygnSnsrClsdLpOprtnBn 4241;
BA_ "SPN" SG_ 2566736126 ShorttermFuelTrimBank2 4238;
BA_ "SPN" SG_ 2566736126 LongtermFuelTrimBank2 4239;
BA_ "SPN" SG_ 2566736382 EngExhstGsOxygnSnsrClsdLpOprtnBn 4240;
BA_ "SPN" SG_ 2566736382 ShorttermFuelTrimBank1 4236;
BA_ "SPN" SG_ 2566736382 LongtermFuelTrimBank1 4237;
BA_ "SigType" SG_ 2565874174 EngSpdSensor1TimingPatternStatus 5;
BA_ "SPN" SG_ 2565874174 EngSpdSensor1TimingPatternStatus 4203;
BA_ "SigType" SG_ 2565874174 EngSpdSensor2TimingPatternStatus 5;
BA_ "SPN" SG_ 2565874174 EngSpdSensor2TimingPatternStatus 4204;
BA_ "SigType" SG_ 2565874174 EngSpdSensor3TimingPatternStatus 5;
BA_ "SPN" SG_ 2565874174 EngSpdSensor3TimingPatternStatus 4205;
BA_ "SigType" SG_ 2565874174 EngSpeed3 1;
BA_ "SPN" SG_ 2565874174 EngSpeed3 4202;
BA_ "SigType" SG_ 2565874174 EngSpeed2 1;
BA_ "SPN" SG_ 2565874174 EngSpeed2 723;
BA_ "SigType" SG_ 2565874174 EngSpeed1 1;
BA_ "SPN" SG_ 2565874174 EngSpeed1 4201;
BA_ "SPN" SG_ 2432520958 EngAxClerSupplyValve2ActuatorCmd 5547;
BA_ "SPN" SG_ 2432520958 EngAxClerSupplyValve1ActuatorCmd 5546;
BA_ "SPN" SG_ 2432520958 DsredEngCoolantThermostatOpening 4197;
BA_ "SigType" SG_ 2432520958 DesiredEngCoolantPumpOutletTemp 1;
BA_ "SPN" SG_ 2432520958 DesiredEngCoolantPumpOutletTemp 4196;
BA_ "SigType" SG_ 2432520958 EngCoolantThermostatMode 5;
BA_ "SPN" SG_ 2432520958 EngCoolantThermostatMode 4195;
BA_ "SPN" SG_ 2560425726 AuxI_OChannel19 4174;
BA_ "SPN" SG_ 2560425726 AuxI_OChannel20 4173;
BA_ "SPN" SG_ 2560425726 AuxI_OChannel21 4172;
BA_ "SPN" SG_ 2560425726 AuxI_OChannel22 4171;
BA_ "SPN" SG_ 2560425726 AuxI_OChannel15 4170;
BA_ "SPN" SG_ 2560425726 AuxI_OChannel16 4169;
BA_ "SPN" SG_ 2560425726 AuxI_OChannel17 4168;
BA_ "SPN" SG_ 2560425726 AuxI_OChannel18 4167;
BA_ "SPN" SG_ 2560491262 AuxI_OChannel11 4166;
BA_ "SPN" SG_ 2560491262 AuxI_OChannel12 4165;
BA_ "SPN" SG_ 2560491262 AuxI_OChannel13 4164;
BA_ "SPN" SG_ 2560491262 AuxI_OChannel14 4163;
BA_ "SPN" SG_ 2560491262 AuxI_OChannel7 4162;
BA_ "SPN" SG_ 2560491262 AuxI_OChannel8 4161;
BA_ "SPN" SG_ 2560491262 AuxI_OChannel9 4160;
BA_ "SPN" SG_ 2560491262 AuxI_OChannel10 4159;
BA_ "SPN" SG_ 2349399806 AuxI_OChannel3 4158;
BA_ "SPN" SG_ 2349399806 AuxI_OChannel4 4157;
BA_ "SPN" SG_ 2349399806 AuxI_OChannel5 4156;
BA_ "SPN" SG_ 2349399806 AuxI_OChannel6 4155;
BA_ "SigType" SG_ 2566758398 Aftertreatment1AirEnableActuator 5;
BA_ "SPN" SG_ 2566758398 Aftertreatment1AirEnableActuator 3489;
BA_ "SigType" SG_ 2566758398 Aftertreatment1PurgeAirActuator 5;
BA_ "SPN" SG_ 2566758398 Aftertreatment1PurgeAirActuator 3490;
BA_ "SigType" SG_ 2566758398 Aftrtrtmnt1AtmizationAirActuator 5;
BA_ "SPN" SG_ 2566758398 Aftrtrtmnt1AtmizationAirActuator 3491;
BA_ "SigType" SG_ 2566758398 Aftertreatment1AirSystemRelay 5;
BA_ "SPN" SG_ 2566758398 Aftertreatment1AirSystemRelay 3492;
BA_ "SigType" SG_ 2566758398 Aftrtratment1AirPressActuatorPos 1;
BA_ "SPN" SG_ 2566758398 Aftrtratment1AirPressActuatorPos 3488;
BA_ "SigType" SG_ 2566758398 Aftertreatment1AirPressCtrl 1;
BA_ "SPN" SG_ 2566758398 Aftertreatment1AirPressCtrl 3487;
BA_ "SigType" SG_ 2566758398 Aftertreatment1PurgeAirPress 1;
BA_ "SPN" SG_ 2566758398 Aftertreatment1PurgeAirPress 3486;
BA_ "SigType" SG_ 2566758398 Aftertreatment1SupplyAirPress 1;
BA_ "SPN" SG_ 2566758398 Aftertreatment1SupplyAirPress 3485;
BA_ "SigType" SG_ 2566745598 Aftertreatment1SecondAirPress 1;
BA_ "SPN" SG_ 2566745598 Aftertreatment1SecondAirPress 3837;
BA_ "SigType" SG_ 2566745598 Aftertreatment1SecondAirMassFlow 1;
BA_ "SPN" SG_ 2566745598 Aftertreatment1SecondAirMassFlow 3832;
BA_ "SigType" SG_ 2566745598 Aftertreatment1SecondAirTemp 1;
BA_ "SPN" SG_ 2566745598 Aftertreatment1SecondAirTemp 3831;
BA_ "SigType" SG_ 2566745598 Aftrtreatment1SecondAirDiffPress 1;
BA_ "SPN" SG_ 2566745598 Aftrtreatment1SecondAirDiffPress 3830;
BA_ "SPN" SG_ 2566758910 Aftrtrtmnt1FlInjector1HeaterCtrl 4301;
BA_ "SigType" SG_ 2566758910 Aftrtreatment1FuelEnableActuator 5;
BA_ "SPN" SG_ 2566758910 Aftrtreatment1FuelEnableActuator 3482;
BA_ "SigType" SG_ 2566758910 Aftrtreatment1RegenerationStatus 5;
BA_ "SPN" SG_ 2566758910 Aftrtreatment1RegenerationStatus 3483;
BA_ "SigType" SG_ 2566758910 Aftertreatment1Ignt 5;
BA_ "SPN" SG_ 2566758910 Aftertreatment1Ignt 3484;
BA_ "SigType" SG_ 2566758910 Aftertreatment1FuelDrainActuator 5;
BA_ "SPN" SG_ 2566758910 Aftertreatment1FuelDrainActuator 4097;
BA_ "SPN" SG_ 2566758910 Aftertreatment1FuelPress1Ctrl 3479;
BA_ "SigType" SG_ 2566758910 Aftertreatment1FuelRate 1;
BA_ "SPN" SG_ 2566758910 Aftertreatment1FuelRate 3481;
BA_ "SigType" SG_ 2566758910 Aftertreatment1FuelPress1 1;
BA_ "SPN" SG_ 2566758910 Aftertreatment1FuelPress1 3480;
BA_ "SigType" SG_ 2566743550 Aftrtrtmnt1HydrcrbnDsrIntkFlTemp 1;
BA_ "SPN" SG_ 2566743550 Aftrtrtmnt1HydrcrbnDsrIntkFlTemp 5456;
BA_ "SPN" SG_ 2566743550 Aftrtrtmnt1FelPress2ActuatorCtrl 5425;
BA_ "SigType" SG_ 2566743550 Aftrtrtmnt1FlFlwDverterValveCtrl 5;
BA_ "SPN" SG_ 2566743550 Aftrtrtmnt1FlFlwDverterValveCtrl 5424;
BA_ "SigType" SG_ 2566743550 Aftertreatment1FuelPumpRelayCtrl 5;
BA_ "SPN" SG_ 2566743550 Aftertreatment1FuelPumpRelayCtrl 5423;
BA_ "SigType" SG_ 2566743550 Aftertreatment1FuelPress2 1;
BA_ "SPN" SG_ 2566743550 Aftertreatment1FuelPress2 4077;
BA_ "SigType" SG_ 2566753534 DslParticulateFilterOutletPress1 1;
BA_ "SPN" SG_ 2566753534 DslParticulateFilterOutletPress1 3610;
BA_ "SigType" SG_ 2566753534 DslParticulateFilterIntakePress1 1;
BA_ "SPN" SG_ 2566753534 DslParticulateFilterIntakePress1 3609;
BA_ "SPN" SG_ 2566756606 Aftrtrtmnt1AvrgDstncBtwnActvDPFR 5827;
BA_ "SPN" SG_ 2566756606 Aftrtrtmnt1AvrgTmBtwnActvRgnrtns 5454;
BA_ "SigType" SG_ 2566756606 Aftrtrtmnt1DslPrtcltFltrTtlN3728 1;
BA_ "SPN" SG_ 2566756606 Aftrtrtmnt1DslPrtcltFltrTtlN3728 3728;
BA_ "SigType" SG_ 2566756606 Aftrtrtmnt1DslPrtcltFltrTtlN3727 1;
BA_ "SPN" SG_ 2566756606 Aftrtrtmnt1DslPrtcltFltrTtlN3727 3727;
BA_ "SigType" SG_ 2566756606 Aftrtrtmnt1DslPrtcltFltrTtlNmbrO 1;
BA_ "SPN" SG_ 2566756606 Aftrtrtmnt1DslPrtcltFltrTtlNmbrO 3726;
BA_ "SigType" SG_ 2566756606 Aftrtrtmnt1DslPrtcltFltrTtlPssvR 1;
BA_ "SPN" SG_ 2566756606 Aftrtrtmnt1DslPrtcltFltrTtlPssvR 3725;
BA_ "SPN" SG_ 2566756606 Aftrtrtmnt1TtlNmbrOfActvRgnrtons 3525;
BA_ "SigType" SG_ 2566756606 Aftertreatment1TotalDisabledTime 1;
BA_ "SPN" SG_ 2566756606 Aftertreatment1TotalDisabledTime 3524;
BA_ "SigType" SG_ 2566756606 Aftrtrtmnt1TotalRegenerationTime 1;
BA_ "SPN" SG_ 2566756606 Aftrtrtmnt1TotalRegenerationTime 3523;
BA_ "SigType" SG_ 2566756606 Aftertreatment1TotalFuelUsed 1;
BA_ "SPN" SG_ 2566756606 Aftertreatment1TotalFuelUsed 3522;
BA_ "SPN" SG_ 2565869310 Aftrtrtmnt1IntkOxygnSnsrPrlmnryF 3225;
BA_ "SPN" SG_ 2565869310 NOxSensorATO1SelfdiagnosisStatus 5713;
BA_ "SPN" SG_ 2565869310 Aftrtrtmnt1IntkNOxSnsrPrlmnryFMI 3224;
BA_ "SPN" SG_ 2565869310 Aftrtrtmnt1IntkGsSnsorHeaterCtrl 3223;
BA_ "SPN" SG_ 2565869310 Aftrtrtmnt1IntkGsSnsrHtrPrlmnryF 3222;
BA_ "SigType" SG_ 2565869310 Aftrtrtmnt1IntkWdRngO2RdngStable 5;
BA_ "SPN" SG_ 2565869310 Aftrtrtmnt1IntkWdRngO2RdngStable 3221;
BA_ "SigType" SG_ 2565869310 Aftrtrtmnt1IntkeNOxReadingStable 5;
BA_ "SPN" SG_ 2565869310 Aftrtrtmnt1IntkeNOxReadingStable 3220;
BA_ "SPN" SG_ 2565869310 Aftrtrtmnt1IntakeGasSensorAtTemp 3219;
BA_ "SigType" SG_ 2565869310 Aftrtrtmnt1IntkGsSnsrPowerStatus 5;
BA_ "SPN" SG_ 2565869310 Aftrtrtmnt1IntkGsSnsrPowerStatus 3218;
BA_ "SigType" SG_ 2565869310 Aftertreatment1IntakeO2 1;
BA_ "SPN" SG_ 2565869310 Aftertreatment1IntakeO2 3217;
BA_ "SigType" SG_ 2565869310 Aftertreatment1IntakeNOx 1;
BA_ "SPN" SG_ 2565869310 Aftertreatment1IntakeNOx 3216;
BA_ "SPN" SG_ 2566763774 Aftrtrtmnt1DslPrtcltFltrIntk3244 3244;
BA_ "SPN" SG_ 2566763774 Aftrtrtmnt1ExhstGsTmp1PrlmnryFMI 3243;
BA_ "SigType" SG_ 2566763774 Aftrtrtmnt1DslPrtcltFltrIntkGsTm 1;
BA_ "SPN" SG_ 2566763774 Aftrtrtmnt1DslPrtcltFltrIntkGsTm 3242;
BA_ "SigType" SG_ 2566763774 Aftertreatment1ExhaustGasTemp1 1;
BA_ "SPN" SG_ 2566763774 Aftertreatment1ExhaustGasTemp1 3241;
BA_ "SPN" SG_ 2631728894 AntitheftRandomNumber 1198;
BA_ "SigType" SG_ 2631728894 AntitheftModifyPwdStates 5;
BA_ "SPN" SG_ 2631728894 AntitheftModifyPwdStates 1197;
BA_ "SigType" SG_ 2631728894 AntitheftComponentStatusStates 5;
BA_ "SPN" SG_ 2631728894 AntitheftComponentStatusStates 1196;
BA_ "SigType" SG_ 2631728894 AntitheftPwdValidIndicator 5;
BA_ "SPN" SG_ 2631728894 AntitheftPwdValidIndicator 1195;
BA_ "SigType" SG_ 2631728894 AntthftEncryptnSdPrsentIndicator 5;
BA_ "SPN" SG_ 2631728894 AntthftEncryptnSdPrsentIndicator 1194;
BA_ "SPN" SG_ 2631794430 AntitheftPwdRepresentation 1202;
BA_ "SPN" SG_ 2631794430 AntitheftCmdStates 1201;
BA_ "SigType" SG_ 2631794430 AntitheftDesiredExitModeStates 5;
BA_ "SPN" SG_ 2631794430 AntitheftDesiredExitModeStates 1200;
BA_ "SigType" SG_ 2631794430 AntthftEncryptionIndicatorStates 5;
BA_ "SPN" SG_ 2631794430 AntthftEncryptionIndicatorStates 1199;
BA_ "SigType" SG_ 2633934846 EngAltWinding3Temp 1;
BA_ "SPN" SG_ 2633934846 EngAltWinding3Temp 1126;
BA_ "SigType" SG_ 2633934846 EngAltWinding2Temp 1;
BA_ "SPN" SG_ 2633934846 EngAltWinding2Temp 1125;
BA_ "SigType" SG_ 2633934846 EngAltWinding1Temp 1;
BA_ "SPN" SG_ 2633934846 EngAltWinding1Temp 1124;
BA_ "SigType" SG_ 2633934846 EngAltBearing2Temp 1;
BA_ "SPN" SG_ 2633934846 EngAltBearing2Temp 1123;
BA_ "SigType" SG_ 2633934846 EngAltBearing1Temp 1;
BA_ "SPN" SG_ 2633934846 EngAltBearing1Temp 1122;
BA_ "SPN" SG_ 2362572542 LevelPresetRearAxleRight 1735;
BA_ "SPN" SG_ 2362572542 LevelPresetRearAxleLeft 1758;
BA_ "SPN" SG_ 2362572542 LevelPresetFrontAxleRight 1757;
BA_ "SPN" SG_ 2362572542 LevelPresetFrontAxleLeft 1732;
BA_ "SigType" SG_ 2365478910 ElctrncShckAbsrbrCtrlMdLft_TgAxl 4;
BA_ "SPN" SG_ 2365478910 ElctrncShckAbsrbrCtrlMdLft_TgAxl 1831;
BA_ "SigType" SG_ 2365478910 ElctrncShckAbsrbrCtrlMdeRearAxle 4;
BA_ "SPN" SG_ 2365478910 ElctrncShckAbsrbrCtrlMdeRearAxle 1832;
BA_ "SigType" SG_ 2365478910 ElctrncShckAbsrbrCtrlMdFrontAxle 4;
BA_ "SPN" SG_ 2365478910 ElctrncShckAbsrbrCtrlMdFrontAxle 1833;
BA_ "SPN" SG_ 2365478910 DamperStiffnessLift_TagAxle 1731;
BA_ "SPN" SG_ 2365478910 DamperStiffnessRearAxle 1730;
BA_ "SPN" SG_ 2365478910 DamperStiffnessFrontAxle 1729;
BA_ "SigType" SG_ 2560950014 TestLimitMinimum 1;
BA_ "SPN" SG_ 2560950014 TestLimitMinimum 4112;
BA_ "SigType" SG_ 2560950014 TestLimitMaximum 1;
BA_ "SPN" SG_ 2560950014 TestLimitMaximum 4111;
BA_ "SigType" SG_ 2560950014 TestValue 1;
BA_ "SPN" SG_ 2560950014 TestValue 4110;
BA_ "SigType" SG_ 2560950014 SlotId 1;
BA_ "SPN" SG_ 2560950014 SlotId 4109;
BA_ "SPN" SG_ 2560950014 FailureModeIdentifier1 1215;
BA_ "SPN" SG_ 2560950014 SPN1 1214;
BA_ "SPN" SG_ 2566763262 Aftrtrtmnt1DslPrtcltFltrIntr3254 3254;
BA_ "SPN" SG_ 2566763262 Aftrtrtmnt1DslPrtcltFltrDltPrssP 3253;
BA_ "SPN" SG_ 2566763262 Aftrtrtmnt1ExhstGsTmp2PrlmnryFMI 3252;
BA_ "SigType" SG_ 2566763262 Aftrtrtmnt1DslPrtcltFltrDffPress 1;
BA_ "SPN" SG_ 2566763262 Aftrtrtmnt1DslPrtcltFltrDffPress 3251;
BA_ "SigType" SG_ 2566763262 Aftrtrtmnt1DslPrtcltFltrIntrmdtG 1;
BA_ "SPN" SG_ 2566763262 Aftrtrtmnt1DslPrtcltFltrIntrmdtG 3250;
BA_ "SigType" SG_ 2566763262 Aftertreatment1ExhaustGasTemp2 1;
BA_ "SPN" SG_ 2566763262 Aftertreatment1ExhaustGasTemp2 3249;
BA_ "SPN" SG_ 2565869566 Aftrtrtmnt1OtltOxygnSnsrPrlmnryF 3235;
BA_ "SPN" SG_ 2565869566 NOxSensorATI1SelfdiagnosisStatus 5714;
BA_ "SPN" SG_ 2565869566 Aftrtrtmnt1OtltNOxSnsrPrlmnryFMI 3234;
BA_ "SPN" SG_ 2565869566 Aftrtrtmnt1OtltGsSnsorHeaterCtrl 3233;
BA_ "SPN" SG_ 2565869566 Aftrtrtmnt1OtltGsSnsrHtrPrlmnryF 3232;
BA_ "SigType" SG_ 2565869566 Aftrtrtmnt1OtltWdRngO2RdngStable 5;
BA_ "SPN" SG_ 2565869566 Aftrtrtmnt1OtltWdRngO2RdngStable 3231;
BA_ "SigType" SG_ 2565869566 Aftrtrtmnt1OtletNOxReadingStable 5;
BA_ "SPN" SG_ 2565869566 Aftrtrtmnt1OtletNOxReadingStable 3230;
BA_ "SigType" SG_ 2565869566 Aftrtrtmnt1OutletGasSensorAtTemp 5;
BA_ "SPN" SG_ 2565869566 Aftrtrtmnt1OutletGasSensorAtTemp 3229;
BA_ "SigType" SG_ 2565869566 Aftrtrtmnt1OtltGsSnsrPowerStatus 5;
BA_ "SPN" SG_ 2565869566 Aftrtrtmnt1OtltGsSnsrPowerStatus 3228;
BA_ "SigType" SG_ 2565869566 Aftertreatment1OutletO2 1;
BA_ "SPN" SG_ 2565869566 Aftertreatment1OutletO2 3227;
BA_ "SigType" SG_ 2565869566 Aftertreatment1OutletNOx 1;
BA_ "SPN" SG_ 2565869566 Aftertreatment1OutletNOx 3226;
BA_ "SPN" SG_ 2566763518 Aftrtrtmnt1DslPrtcltFltrOtltExhs 3248;
BA_ "SPN" SG_ 2566763518 Aftrtrtmnt1ExhstGsTmp3PrlmnryFMI 3247;
BA_ "SigType" SG_ 2566763518 Aftrtrtmnt1DslPrtcltFltrOtltGsTm 1;
BA_ "SPN" SG_ 2566763518 Aftrtrtmnt1DslPrtcltFltrOtltGsTm 3246;
BA_ "SigType" SG_ 2566763518 Aftertreatment1ExhaustGasTemp3 1;
BA_ "SPN" SG_ 2566763518 Aftertreatment1ExhaustGasTemp3 3245;
BA_ "SPN" SG_ 2566749182 Aftrtrtmnt1DslPrtcltFltrStLdRgnr 5466;
BA_ "SigType" SG_ 2566749182 DslPrtcltFltr1TmSncLstActvRgnrtn 1;
BA_ "SPN" SG_ 2566749182 DslPrtcltFltr1TmSncLstActvRgnrtn 3721;
BA_ "SigType" SG_ 2566749182 DslPrtclateFilter1AshLoadPercent 1;
BA_ "SPN" SG_ 2566749182 DslPrtclateFilter1AshLoadPercent 3720;
BA_ "SigType" SG_ 2566749182 DslPrtclteFilter1SootLoadPercent 1;
BA_ "SPN" SG_ 2566749182 DslPrtclteFilter1SootLoadPercent 3719;
BA_ "SigType" SG_ 2566748670 Aftrtrtmnt1DslPrtcltFltrTrpN3740 1;
BA_ "SPN" SG_ 2566748670 Aftrtrtmnt1DslPrtcltFltrTrpN3740 3740;
BA_ "SigType" SG_ 2566748670 Aftrtrtmnt1DslPrtcltFltrTrpN3739 1;
BA_ "SPN" SG_ 2566748670 Aftrtrtmnt1DslPrtcltFltrTrpN3739 3739;
BA_ "SigType" SG_ 2566748670 Aftrtrtmnt1DslPrtcltFltrTrpN3738 1;
BA_ "SPN" SG_ 2566748670 Aftrtrtmnt1DslPrtcltFltrTrpN3738 3738;
BA_ "SigType" SG_ 2566748670 Aftrtrtmnt1DslPrtcltFltrTrpPssvR 1;
BA_ "SPN" SG_ 2566748670 Aftrtrtmnt1DslPrtcltFltrTrpPssvR 3737;
BA_ "SigType" SG_ 2566748670 Aftrtrtmnt1DslPrtcltFltrTrpNmbrO 1;
BA_ "SPN" SG_ 2566748670 Aftrtrtmnt1DslPrtcltFltrTrpNmbrO 3736;
BA_ "SigType" SG_ 2566748670 Aftrtrtmnt1DslPrtcltFltrTrpDsbld 1;
BA_ "SPN" SG_ 2566748670 Aftrtrtmnt1DslPrtcltFltrTrpDsbld 3735;
BA_ "SigType" SG_ 2566748670 Aftrtrtmnt1DslPrtcltFltrTrpActvR 1;
BA_ "SPN" SG_ 2566748670 Aftrtrtmnt1DslPrtcltFltrTrpActvR 3734;
BA_ "SigType" SG_ 2566748670 Aftrtrtmnt1DslPrtcltFltrTrpFlUsd 1;
BA_ "SPN" SG_ 2566748670 Aftrtrtmnt1DslPrtcltFltrTrpFlUsd 3733;
BA_ "SigType" SG_ 2566758142 Aftertreatment2AirEnableActuator 5;
BA_ "SPN" SG_ 2566758142 Aftertreatment2AirEnableActuator 3503;
BA_ "SigType" SG_ 2566758142 Aftertreatment2PurgeAirActuator 5;
BA_ "SPN" SG_ 2566758142 Aftertreatment2PurgeAirActuator 3504;
BA_ "SigType" SG_ 2566758142 Aftrtrtmnt2AtmizationAirActuator 5;
BA_ "SPN" SG_ 2566758142 Aftrtrtmnt2AtmizationAirActuator 3505;
BA_ "SigType" SG_ 2566758142 Aftertreatment2AirSystemRelay 5;
BA_ "SPN" SG_ 2566758142 Aftertreatment2AirSystemRelay 3506;
BA_ "SigType" SG_ 2566758142 Aftrtratment2AirPressActuatorPos 1;
BA_ "SPN" SG_ 2566758142 Aftrtratment2AirPressActuatorPos 3502;
BA_ "SigType" SG_ 2566758142 Aftertreatment2AirPressCtrl 1;
BA_ "SPN" SG_ 2566758142 Aftertreatment2AirPressCtrl 3501;
BA_ "SigType" SG_ 2566758142 Aftertreatment2PurgeAirPress 1;
BA_ "SPN" SG_ 2566758142 Aftertreatment2PurgeAirPress 3500;
BA_ "SigType" SG_ 2566758142 Aftertreatment2SupplyAirPress 1;
BA_ "SPN" SG_ 2566758142 Aftertreatment2SupplyAirPress 3499;
BA_ "SigType" SG_ 2566745342 Aftertreatment2SecondAirPress 1;
BA_ "SPN" SG_ 2566745342 Aftertreatment2SecondAirPress 3838;
BA_ "SigType" SG_ 2566745342 Aftertreatment2SecondAirMassFlow 1;
BA_ "SPN" SG_ 2566745342 Aftertreatment2SecondAirMassFlow 3835;
BA_ "SigType" SG_ 2566745342 Aftertreatment2SecondAirTemp 1;
BA_ "SPN" SG_ 2566745342 Aftertreatment2SecondAirTemp 3834;
BA_ "SigType" SG_ 2566745342 Aftrtreatment2SecondAirDiffPress 1;
BA_ "SPN" SG_ 2566745342 Aftrtreatment2SecondAirDiffPress 3833;
BA_ "SPN" SG_ 2566758654 Aftrtrtmnt2FlInjector1HeaterCtrl 4302;
BA_ "SigType" SG_ 2566758654 Aftrtreatment2FuelEnableActuator 5;
BA_ "SPN" SG_ 2566758654 Aftrtreatment2FuelEnableActuator 3496;
BA_ "SigType" SG_ 2566758654 Aftrtreatment2RegenerationStatus 5;
BA_ "SPN" SG_ 2566758654 Aftrtreatment2RegenerationStatus 3497;
BA_ "SigType" SG_ 2566758654 Aftertreatment2Ignt 5;
BA_ "SPN" SG_ 2566758654 Aftertreatment2Ignt 3498;
BA_ "SigType" SG_ 2566758654 Aftertreatment2FuelDrainActuator 5;
BA_ "SPN" SG_ 2566758654 Aftertreatment2FuelDrainActuator 4098;
BA_ "SPN" SG_ 2566758654 Aftertreatment2FuelPress1Ctrl 3493;
BA_ "SigType" SG_ 2566758654 Aftertreatment2FuelRate 1;
BA_ "SPN" SG_ 2566758654 Aftertreatment2FuelRate 3495;
BA_ "SigType" SG_ 2566758654 Aftertreatment2FuelPress1 1;
BA_ "SPN" SG_ 2566758654 Aftertreatment2FuelPress1 3494;
BA_ "SigType" SG_ 2566753278 DslParticulateFilterOutletPress2 1;
BA_ "SPN" SG_ 2566753278 DslParticulateFilterOutletPress2 3612;
BA_ "SigType" SG_ 2566753278 DslParticulateFilterIntakePress2 1;
BA_ "SPN" SG_ 2566753278 DslParticulateFilterIntakePress2 3611;
BA_ "SPN" SG_ 2566756862 Aftrtrtmnt2AvrgDstncBtwnActvDPFR 5828;
BA_ "SPN" SG_ 2566756862 Aftrtrtmnt2AvrgTmBtwnActvRgnrtns 5455;
BA_ "SigType" SG_ 2566756862 Aftrtrtmnt2DslPrtcltFltrTtlN3732 1;
BA_ "SPN" SG_ 2566756862 Aftrtrtmnt2DslPrtcltFltrTtlN3732 3732;
BA_ "SigType" SG_ 2566756862 Aftrtrtmnt2DslPrtcltFltrTtlN3731 1;
BA_ "SPN" SG_ 2566756862 Aftrtrtmnt2DslPrtcltFltrTtlN3731 3731;
BA_ "SigType" SG_ 2566756862 Aftrtrtmnt2DslPrtcltFltrTtlNmbrO 1;
BA_ "SPN" SG_ 2566756862 Aftrtrtmnt2DslPrtcltFltrTtlNmbrO 3730;
BA_ "SigType" SG_ 2566756862 Aftrtrtmnt2DslPrtcltFltrTtlPssvR 1;
BA_ "SPN" SG_ 2566756862 Aftrtrtmnt2DslPrtcltFltrTtlPssvR 3729;
BA_ "SigType" SG_ 2566756862 Aftrtrtmnt2TtlNmbrOfActvRgnrtons 1;
BA_ "SPN" SG_ 2566756862 Aftrtrtmnt2TtlNmbrOfActvRgnrtons 3529;
BA_ "SPN" SG_ 2566756862 Aftertreatment2TotalDisabledTime 3528;
BA_ "SPN" SG_ 2566756862 Aftrtrtmnt2TotalRegenerationTime 3527;
BA_ "SPN" SG_ 2566756862 Aftertreatment2TotalFuelUsed 3526;
BA_ "SPN" SG_ 2565869822 Aftrtrtmnt2IntkOxygnSnsrPrlmnryF 3264;
BA_ "SPN" SG_ 2565869822 NOxSensorATO2SelfdiagnosisStatus 5715;
BA_ "SPN" SG_ 2565869822 Aftrtrtmnt2IntkNOxSnsrPrlmnryFMI 3263;
BA_ "SPN" SG_ 2565869822 Aftrtrtmnt2IntkGsSnsorHeaterCtrl 3262;
BA_ "SPN" SG_ 2565869822 Aftrtrtmnt2IntkGsSnsrHtrPrlmnryF 3261;
BA_ "SigType" SG_ 2565869822 Aftrtrtmnt2IntkWdRngO2RdngStable 5;
BA_ "SPN" SG_ 2565869822 Aftrtrtmnt2IntkWdRngO2RdngStable 3260;
BA_ "SigType" SG_ 2565869822 Aftrtrtmnt2IntkeNOxReadingStable 5;
BA_ "SPN" SG_ 2565869822 Aftrtrtmnt2IntkeNOxReadingStable 3259;
BA_ "SigType" SG_ 2565869822 Aftrtrtmnt2IntakeGasSensorAtTemp 5;
BA_ "SPN" SG_ 2565869822 Aftrtrtmnt2IntakeGasSensorAtTemp 3258;
BA_ "SigType" SG_ 2565869822 Aftrtrtmnt2IntkGsSnsrPowerStatus 5;
BA_ "SPN" SG_ 2565869822 Aftrtrtmnt2IntkGsSnsrPowerStatus 3257;
BA_ "SigType" SG_ 2565869822 Aftertreatment2IntakeO2 1;
BA_ "SPN" SG_ 2565869822 Aftertreatment2IntakeO2 3256;
BA_ "SigType" SG_ 2565869822 Aftertreatment2IntakeNOx 1;
BA_ "SPN" SG_ 2565869822 Aftertreatment2IntakeNOx 3255;
BA_ "SPN" SG_ 2566763006 Aftrtrtmnt2DslPrtcltFltrIntk3278 3278;
BA_ "SPN" SG_ 2566763006 Aftrtrtmnt2ExhstGsTmp1PrlmnryFMI 3277;
BA_ "SigType" SG_ 2566763006 Aftrtrtmnt2DslPrtcltFltrIntkGsTm 1;
BA_ "SPN" SG_ 2566763006 Aftrtrtmnt2DslPrtcltFltrIntkGsTm 3276;
BA_ "SigType" SG_ 2566763006 Aftertreatment2ExhaustGasTemp1 1;
BA_ "SPN" SG_ 2566763006 Aftertreatment2ExhaustGasTemp1 3275;
BA_ "SPN" SG_ 2566762494 Aftrtrtmnt2DslPrtcltFltrIntr3288 3288;
BA_ "SPN" SG_ 2566762494 Aftrtrtmnt2DslPrtcltFltrDltPrssP 3287;
BA_ "SPN" SG_ 2566762494 Aftrtrtmnt2ExhstGsTmp2PrlmnryFMI 3286;
BA_ "SigType" SG_ 2566762494 Aftrtrtmnt2DslPrtcltFltrDffPress 1;
BA_ "SPN" SG_ 2566762494 Aftrtrtmnt2DslPrtcltFltrDffPress 3285;
BA_ "SigType" SG_ 2566762494 Aftrtrtmnt2DslPrtcltFltrIntrmdtG 1;
BA_ "SPN" SG_ 2566762494 Aftrtrtmnt2DslPrtcltFltrIntrmdtG 3284;
BA_ "SigType" SG_ 2566762494 Aftertreatment2ExhaustGasTemp2 1;
BA_ "SPN" SG_ 2566762494 Aftertreatment2ExhaustGasTemp2 3283;
BA_ "SPN" SG_ 2565870078 Aftrtrtmnt2OtltOxygnSnsrPrlmnryF 3274;
BA_ "SPN" SG_ 2565870078 NOxSensorATI2SelfdiagnosisStatus 5716;
BA_ "SPN" SG_ 2565870078 Aftrtrtmnt2OtltNOxSnsrPrlmnryFMI 3273;
BA_ "SigType" SG_ 2565870078 Aftrtrtmnt2OtltGsSnsorHeaterCtrl 5;
BA_ "SPN" SG_ 2565870078 Aftrtrtmnt2OtltGsSnsorHeaterCtrl 3272;
BA_ "SPN" SG_ 2565870078 Aftrtrtmnt2OtltGsSnsrHtrPrlmnryF 3271;
BA_ "SigType" SG_ 2565870078 Aftrtrtmnt2OtltWdRngO2RdngStable 5;
BA_ "SPN" SG_ 2565870078 Aftrtrtmnt2OtltWdRngO2RdngStable 3270;
BA_ "SigType" SG_ 2565870078 Aftrtrtmnt2OtletNOxReadingStable 5;
BA_ "SPN" SG_ 2565870078 Aftrtrtmnt2OtletNOxReadingStable 3269;
BA_ "SigType" SG_ 2565870078 Aftrtrtmnt2OutletGasSensorAtTemp 5;
BA_ "SPN" SG_ 2565870078 Aftrtrtmnt2OutletGasSensorAtTemp 3268;
BA_ "SigType" SG_ 2565870078 Aftrtrtmnt2OtltGsSnsrPowerStatus 5;
BA_ "SPN" SG_ 2565870078 Aftrtrtmnt2OtltGsSnsrPowerStatus 3267;
BA_ "SigType" SG_ 2565870078 Aftertreatment2OutletO2 1;
BA_ "SPN" SG_ 2565870078 Aftertreatment2OutletO2 3266;
BA_ "SigType" SG_ 2565870078 Aftertreatment2OutletNOx 1;
BA_ "SPN" SG_ 2565870078 Aftertreatment2OutletNOx 3265;
BA_ "SPN" SG_ 2566762750 Aftrtrtmnt2DslPrtcltFltrExhstGsT 3282;
BA_ "SPN" SG_ 2566762750 Aftrtrtmnt2ExhstGsTmp3PrlmnryFMI 3281;
BA_ "SigType" SG_ 2566762750 Aftrtrtmnt2DslPrtcltFltrOtltGsTm 1;
BA_ "SPN" SG_ 2566762750 Aftrtrtmnt2DslPrtcltFltrOtltGsTm 3280;
BA_ "SigType" SG_ 2566762750 Aftertreatment2ExhaustGasTemp3 1;
BA_ "SPN" SG_ 2566762750 Aftertreatment2ExhaustGasTemp3 3279;
BA_ "SPN" SG_ 2566748926 Aftrtrtmnt2DslPrtcltFltrStLdRgnr 5467;
BA_ "SigType" SG_ 2566748926 DslPrtcltFltr2TmSncLstActvRgnrtn 1;
BA_ "SPN" SG_ 2566748926 DslPrtcltFltr2TmSncLstActvRgnrtn 3724;
BA_ "SigType" SG_ 2566748926 DslPrtclateFilter2AshLoadPercent 1;
BA_ "SPN" SG_ 2566748926 DslPrtclateFilter2AshLoadPercent 3723;
BA_ "SigType" SG_ 2566748926 DslPrtclteFilter2SootLoadPercent 1;
BA_ "SPN" SG_ 2566748926 DslPrtclteFilter2SootLoadPercent 3722;
BA_ "SigType" SG_ 2566748414 Aftrtrtmnt2DslPrtcltFltrTrpN3748 1;
BA_ "SPN" SG_ 2566748414 Aftrtrtmnt2DslPrtcltFltrTrpN3748 3748;
BA_ "SigType" SG_ 2566748414 Aftrtrtmnt2DslPrtcltFltrTrpN3747 1;
BA_ "SPN" SG_ 2566748414 Aftrtrtmnt2DslPrtcltFltrTrpN3747 3747;
BA_ "SigType" SG_ 2566748414 Aftrtrtmnt2DslPrtcltFltrTrpN3746 1;
BA_ "SPN" SG_ 2566748414 Aftrtrtmnt2DslPrtcltFltrTrpN3746 3746;
BA_ "SigType" SG_ 2566748414 Aftrtrtmnt2DslPrtcltFltrTrpPssvR 1;
BA_ "SPN" SG_ 2566748414 Aftrtrtmnt2DslPrtcltFltrTrpPssvR 3745;
BA_ "SigType" SG_ 2566748414 Aftrtrtmnt2DslPrtcltFltrTrpNmbrO 1;
BA_ "SPN" SG_ 2566748414 Aftrtrtmnt2DslPrtcltFltrTrpNmbrO 3744;
BA_ "SigType" SG_ 2566748414 Aftrtrtmnt2DslPrtcltFltrTrpDsbld 1;
BA_ "SPN" SG_ 2566748414 Aftrtrtmnt2DslPrtcltFltrTrpDsbld 3743;
BA_ "SigType" SG_ 2566748414 Aftrtrtmnt2DslPrtcltFltrTrpActvR 1;
BA_ "SPN" SG_ 2566748414 Aftrtrtmnt2DslPrtcltFltrTrpActvR 3742;
BA_ "SigType" SG_ 2566748414 Aftrtrtmnt2DslPrtcltFltrTrpFlUsd 1;
BA_ "SPN" SG_ 2566748414 Aftrtrtmnt2DslPrtcltFltrTrpFlUsd 3741;
BA_ "SPN" SG_ 2365428478 EngDerateRq 3644;
BA_ "SigType" SG_ 2365428478 EngEmergencyShutdownIndication 5;
BA_ "SPN" SG_ 2365428478 EngEmergencyShutdownIndication 3607;
BA_ "SigType" SG_ 2365428478 EngControlledShutdownRq 5;
BA_ "SPN" SG_ 2365428478 EngControlledShutdownRq 3606;
BA_ "SigType" SG_ 2365428478 EngCoolantCirculatingPumpCtrl 5;
BA_ "SPN" SG_ 2365428478 EngCoolantCirculatingPumpCtrl 3605;
BA_ "SigType" SG_ 2365428478 EngBlock_CoolantPreheaterCtrl 5;
BA_ "SPN" SG_ 2365428478 EngBlock_CoolantPreheaterCtrl 3604;
BA_ "SigType" SG_ 2365428478 EngElctrclSystmPwrCnsrvationCtrl 5;
BA_ "SPN" SG_ 2365428478 EngElctrclSystmPwrCnsrvationCtrl 3603;
BA_ "SigType" SG_ 2365428478 EngOilPreheaterCtrl 5;
BA_ "SPN" SG_ 2365428478 EngOilPreheaterCtrl 3602;
BA_ "SigType" SG_ 2365428478 EngOilPrimingPumpCtrl 5;
BA_ "SPN" SG_ 2365428478 EngOilPrimingPumpCtrl 3589;
BA_ "SigType" SG_ 2365428478 EngFuelShutoffValveLeakTestCtrl 5;
BA_ "SPN" SG_ 2365428478 EngFuelShutoffValveLeakTestCtrl 3601;
BA_ "SigType" SG_ 2365428478 EngFuelShutoff2Ctrl 5;
BA_ "SPN" SG_ 2365428478 EngFuelShutoff2Ctrl 2807;
BA_ "SigType" SG_ 2365428478 EngFuelShutoff1Ctrl 5;
BA_ "SPN" SG_ 2365428478 EngFuelShutoff1Ctrl 632;
BA_ "SigType" SG_ 2365428478 EngFuelShutoffVentCtrl 5;
BA_ "SPN" SG_ 2365428478 EngFuelShutoffVentCtrl 3608;
BA_ "SPN" SG_ 2365428478 TimeRemainingInEngOperatingState 3544;
BA_ "SigType" SG_ 2365428478 FuelPumpPrimerCtrl 5;
BA_ "SPN" SG_ 2365428478 FuelPumpPrimerCtrl 4082;
BA_ "SPN" SG_ 2365428478 EngOperatingState 3543;
BA_ "SigType" SG_ 2566743806 EngExhstGsRcrcltn1MxerIntakeTemp 1;
BA_ "SPN" SG_ 2566743806 EngExhstGsRcrcltn1MxerIntakeTemp 5020;
BA_ "SigType" SG_ 2566743806 EngExhstVlvActationSystemOilTemp 1;
BA_ "SPN" SG_ 2566743806 EngExhstVlvActationSystemOilTemp 4288;
BA_ "SigType" SG_ 2566743806 EngCoolantThermostatOpening 1;
BA_ "SPN" SG_ 2566743806 EngCoolantThermostatOpening 4194;
BA_ "SigType" SG_ 2566743806 EngCoolantPumpOutletTemp 1;
BA_ "SPN" SG_ 2566743806 EngCoolantPumpOutletTemp 4193;
BA_ "SigType" SG_ 2566743806 EngCoolantTemp2 1;
BA_ "SPN" SG_ 2566743806 EngCoolantTemp2 4076;
BA_ "SPN" SG_ 2499635454 NetVehicleWeightChange 413;
BA_ "SPN" SG_ 2499635454 GrossCombinationWeight 417;
BA_ "SigType" SG_ 2550660862 ValveAssemblySupplyPress 1;
BA_ "SPN" SG_ 2550660862 ValveAssemblySupplyPress 4089;
BA_ "SigType" SG_ 2550660862 ValveAssemblyLoadSensePress 1;
BA_ "SPN" SG_ 2550660862 ValveAssemblyLoadSensePress 4088;
BA_ "SigType" SG_ 2550660862 ValvePilotPress 1;
BA_ "SPN" SG_ 2550660862 ValvePilotPress 4087;
BA_ "SigType" SG_ 2550660862 ValveLoadSensePress 1;
BA_ "SPN" SG_ 2550660862 ValveLoadSensePress 4086;
BA_ "SigType" SG_ 2566805758 BellowPressRearAxleRight 1;
BA_ "SPN" SG_ 2566805758 BellowPressRearAxleRight 1728;
BA_ "SigType" SG_ 2566805758 BellowPressRearAxleLeft 1;
BA_ "SPN" SG_ 2566805758 BellowPressRearAxleLeft 1727;
BA_ "SigType" SG_ 2566805758 BellowPressFrontAxleRight 1;
BA_ "SPN" SG_ 2566805758 BellowPressFrontAxleRight 1726;
BA_ "SigType" SG_ 2566805758 BellowPressFrontAxleLeft 1;
BA_ "SPN" SG_ 2566805758 BellowPressFrontAxleLeft 1725;
BA_ "SigType" SG_ 2566806014 RelativeLevelRearAxleRight 1;
BA_ "SPN" SG_ 2566806014 RelativeLevelRearAxleRight 1723;
BA_ "SigType" SG_ 2566806014 RelativeLevelRearAxleLeft 1;
BA_ "SPN" SG_ 2566806014 RelativeLevelRearAxleLeft 1724;
BA_ "SigType" SG_ 2566806014 RelativeLevelFrontAxleRight 1;
BA_ "SPN" SG_ 2566806014 RelativeLevelFrontAxleRight 1722;
BA_ "SigType" SG_ 2566806014 RelativeLevelFrontAxleLeft 1;
BA_ "SPN" SG_ 2566806014 RelativeLevelFrontAxleLeft 1721;
BA_ "SPN" SG_ 2362638078 MemoryLevelRq 5433;
BA_ "SigType" SG_ 2362638078 PrhbitAutomaticAirSuspensionCtrl 5;
BA_ "SPN" SG_ 2362638078 PrhbitAutomaticAirSuspensionCtrl 5274;
BA_ "SigType" SG_ 2362638078 SpeedDependentLevelCtrlRq 5;
BA_ "SPN" SG_ 2362638078 SpeedDependentLevelCtrlRq 5295;
BA_ "SigType" SG_ 2362638078 AllowLevelCtrlDuringBrakingCmd 5;
BA_ "SPN" SG_ 2362638078 AllowLevelCtrlDuringBrakingCmd 5293;
BA_ "SigType" SG_ 2362638078 ProhibitAirSuspensionCtrl 5;
BA_ "SPN" SG_ 2362638078 ProhibitAirSuspensionCtrl 3215;
BA_ "SigType" SG_ 2362638078 KneelingCmdRearAxle 5;
BA_ "SPN" SG_ 2362638078 KneelingCmdRearAxle 1829;
BA_ "SigType" SG_ 2362638078 KneelingCmdFrontAxle 5;
BA_ "SPN" SG_ 2362638078 KneelingCmdFrontAxle 1830;
BA_ "SPN" SG_ 2362638078 DamperStiffnessRqLift_TagAxle 1720;
BA_ "SPN" SG_ 2362638078 DamperStiffnessRqRearAxle 1719;
BA_ "SPN" SG_ 2362638078 DamperStiffnessRqFrontAxle 1718;
BA_ "SigType" SG_ 2362638078 LiftAxle2PosCmd 5;
BA_ "SPN" SG_ 2362638078 LiftAxle2PosCmd 1828;
BA_ "SigType" SG_ 2362638078 LiftAxle1PosCmd 5;
BA_ "SPN" SG_ 2362638078 LiftAxle1PosCmd 1752;
BA_ "SPN" SG_ 2362638078 LevelCtrlModeRq 1753;
BA_ "SPN" SG_ 2362638078 NominalLevelRqRearAxle 1750;
BA_ "SPN" SG_ 2362638078 NominalLevelRqFrontAxle 1751;
BA_ "SigType" SG_ 2362638078 KneelingCtrlModeRq 5;
BA_ "SPN" SG_ 2362638078 KneelingCtrlModeRq 1747;
BA_ "SigType" SG_ 2362638078 KneelingRqRightSide 5;
BA_ "SPN" SG_ 2362638078 KneelingRqRightSide 1748;
BA_ "SigType" SG_ 2362638078 KneelingRqLeftSide 5;
BA_ "SPN" SG_ 2362638078 KneelingRqLeftSide 1749;
BA_ "SigType" SG_ 2362638078 AutomaticTractionHelp 5;
BA_ "SPN" SG_ 2362638078 AutomaticTractionHelp 2984;
VAL_ 2566742270 FailureModeIdentifier1 31 "Not available" 19 "Received network data in error" 18 "Below normal (moderately severe)" 17 "Below normal (least severe)" 16 "Above normal (moderately severe)" 15 "Above normal (least severe)" 14 "Special intstructions" 13 "Out of calibration" 12 "Bad intelligent device" 11 "Root cause not known" 10 "Abnormal rate of change" 9 "Abnormal update rate" 8 "Abnormal frequency" 7 "Mechanical system not responding" 6 "Current above normal" 5 "Current below normal" 4 "Voltage below normal" 3 "Voltage above normal" 2 "Data erratic" 1 "Below normal (most severe)" 0 "Above normal (most severe)" ;
VAL_ 2560687870 PMNTEDeficiencyAreaStatus 3 "NotAvailable" 2 "Reserved" 1 "InsideControlArea" 0 "OutsideControlArea" ;
VAL_ 2560687870 MnfcPMNTECarveOutAreaStatus 3 "NotAvailable" 2 "Reserved" 1 "InsideControlArea" 0 "OutsideControlArea" ;
VAL_ 2560687870 PMNTEControlAreaStatus 3 "NotAvailable" 2 "Reserved" 1 "InsideControlArea" 0 "OutsideControlArea" ;
VAL_ 2560687870 NOxNTEDeficiencyAreaStatus 3 "NotAvailable" 2 "Reserved" 1 "InsideControlArea" 0 "OutsideControlArea" ;
VAL_ 2560687870 MnfcNOxNTECarveOutAreaStatus 3 "NotAvailable" 2 "Reserved" 1 "InsideControlArea" 0 "OutsideControlArea" ;
VAL_ 2560687870 NOxNTEControlAreaStatus 3 "NotAvailable" 2 "Reserved" 1 "InsideControlArea" 0 "OutsideControlArea" ;
VAL_ 2566809342 BatteryMainSwitchHoldState 3 "Dont care/take no action" 2 "Reserved" 1 "Battery main switch held" 0 "Battery main switch not held" ;
VAL_ 2365446910 Joystick3XAxisDetentPosStatus 3 "Not Available" 2 "Error Indicator" 1 "In the Detent Position" 0 "Not in the Detent Position" ;
VAL_ 2365446910 Joystick3Button9PressedStatus 3 "Not Available" 2 "Error Indicator" 1 "Button pressed" 0 "Button not pressed" ;
VAL_ 2365446910 Joystick3Button10PressedStatus 3 "Not Available" 2 "Error Indicator" 1 "Button pressed" 0 "Button not pressed" ;
VAL_ 2365446910 Joystick3Button11PressedStatus 3 "Not Available" 2 "Error Indicator" 1 "Button pressed" 0 "Button not pressed" ;
VAL_ 2365446910 Joystick3Button12PressedStatus 3 "Not Available" 2 "Error Indicator" 1 "Button pressed" 0 "Button not pressed" ;
VAL_ 2365446910 Joystick3YAxisDetentPosStatus 3 "Not Available" 2 "Error Indicator" 1 "In the Detent Position" 0 "Not in the Detent Position" ;
VAL_ 2365446910 Jystck3YAxsLvrFrwrdPstvPosStatus 3 "Not Available" 2 "Error Indicator" 1 "On positive side of Neutral" 0 "Not on Positive side of Neutral" ;
VAL_ 2365446910 Jystck3YAxsLvrBckNgtivePosStatus 3 "Not Available" 2 "Error Indicator" 1 "On negative side of Neutral" 0 "Not on negative side of Neutral" ;
VAL_ 2365446910 Joystick3YAxisNeutralPosStatus 3 "Not Available" 2 "Error Indicator" 1 "In Neutral Position" 0 "Not in Neutral Position" ;
VAL_ 2365446910 Jystck3XAxsLvrRghtPstvePosStatus 3 "Not Available" 2 "Error Indicator" 1 "On positive side of Neutral" 0 "Not on Positive side of Neutral" ;
VAL_ 2365446910 Jystck3XAxsLvrLftNgtivePosStatus 3 "Not Available" 2 "Error Indicator" 1 "On negative side of Neutral" 0 "Not on negative side of Neutral" ;
VAL_ 2365446910 Joystick3XAxisNeutralPosStatus 3 "Not Available" 2 "Error Indicator" 1 "In Neutral Position" 0 "Not in Neutral Position" ;
VAL_ 2365446910 Joystick3Button5PressedStatus 3 "Not Available" 2 "Error Indicator" 1 "Button pressed" 0 "Button not pressed" ;
VAL_ 2365446910 Joystick3Button6PressedStatus 3 "Not Available" 2 "Error Indicator" 1 "Button pressed" 0 "Button not pressed" ;
VAL_ 2365446910 Joystick3Button7PressedStatus 3 "Not Available" 2 "Error Indicator" 1 "Button pressed" 0 "Button not pressed" ;
VAL_ 2365446910 Joystick3Button8PressedStatus 3 "Not Available" 2 "Error Indicator" 1 "Button pressed" 0 "Button not pressed" ;
VAL_ 2365446910 Joystick3Button1PressedStatus 3 "Not Available" 2 "Error Indicator" 1 "Button pressed" 0 "Button not pressed" ;
VAL_ 2365446910 Joystick3Button2PressedStatus 3 "Not Available" 2 "Error Indicator" 1 "Button pressed" 0 "Button not pressed" ;
VAL_ 2365446910 Joystick3Button3PressedStatus 3 "Not Available" 2 "Error Indicator" 1 "Button pressed" 0 "Button not pressed" ;
VAL_ 2365446910 Joystick3Button4PressedStatus 3 "Not Available" 2 "Error Indicator" 1 "Button pressed" 0 "Button not pressed" ;
VAL_ 2365446398 Joystick2XAxisDetentPosStatus 3 "Not Available" 2 "Error Indicator" 1 "In the Detent Position" 0 "Not in the Detent Position" ;
VAL_ 2365446398 Joystick2YAxisDetentPosStatus 3 "Not Available" 2 "Error Indicator" 1 "In the Detent Position" 0 "Not in the Detent Position" ;
VAL_ 2365446398 Jystck2YAxsLvrFrwrdPstvPosStatus 3 "Not Available" 2 "Error Indicator" 1 "On positive side of Neutral" 0 "Not on Positive side of Neutral" ;
VAL_ 2365446398 Jystck2YAxsLvrBckNgtivePosStatus 3 "Not Available" 2 "Error Indicator" 1 "On negative side of Neutral" 0 "Not on negative side of Neutral" ;
VAL_ 2365446398 Joystick2YAxisNeutralPosStatus 3 "Not Available" 2 "Error Indicator" 1 "In Neutral Position" 0 "Not in Neutral Position" ;
VAL_ 2365446398 Jystck2XAxsLvrRghtPstvePosStatus 3 "Not Available" 2 "Error Indicator" 1 "On positive side of Neutral" 0 "Not on Positive side of Neutral" ;
VAL_ 2365446398 Jystck2XAxsLvrLftNgtivePosStatus 3 "Not Available" 2 "Error Indicator" 1 "On negative side of Neutral" 0 "Not on negative side of Neutral" ;
VAL_ 2365446398 Joystick2XAxisNeutralPosStatus 3 "Not Available" 2 "Error Indicator" 1 "In Neutral Position" 0 "Not in Neutral Position" ;
VAL_ 2365446398 Joystick2Button9PressedStatus 3 "Not Available" 2 "Error Indicator" 1 "Button pressed" 0 "Button not pressed" ;
VAL_ 2365446398 Joystick2Button10PressedStatus 3 "Not Available" 2 "Error Indicator" 1 "Button pressed" 0 "Button not pressed" ;
VAL_ 2365446398 Joystick2Button11PressedStatus 3 "Not Available" 2 "Error Indicator" 1 "Button pressed" 0 "Button not pressed" ;
VAL_ 2365446398 Joystick2Button12PressedStatus 3 "Not Available" 2 "Error Indicator" 1 "Button pressed" 0 "Button not pressed" ;
VAL_ 2365446398 Joystick2Button5PressedStatus 3 "Not Available" 2 "Error Indicator" 1 "Button pressed" 0 "Button not pressed" ;
VAL_ 2365446398 Joystick2Button6PressedStatus 3 "Not Available" 2 "Error Indicator" 1 "Button pressed" 0 "Button not pressed" ;
VAL_ 2365446398 Joystick2Button7PressedStatus 3 "Not Available" 2 "Error Indicator" 1 "Button pressed" 0 "Button not pressed" ;
VAL_ 2365446398 Joystick2Button8PressedStatus 3 "Not Available" 2 "Error Indicator" 1 "Button pressed" 0 "Button not pressed" ;
VAL_ 2365446398 Joystick2Button1PressedStatus 3 "Not Available" 2 "Error Indicator" 1 "Button pressed" 0 "Button not pressed" ;
VAL_ 2365446398 Joystick2Button2PressedStatus 3 "Not Available" 2 "Error Indicator" 1 "Button pressed" 0 "Button not pressed" ;
VAL_ 2365446398 Joystick2Button3PressedStatus 3 "Not Available" 2 "Error Indicator" 1 "Button pressed" 0 "Button not pressed" ;
VAL_ 2365446398 Joystick2Button4PressedStatus 3 "Not Available" 2 "Error Indicator" 1 "Button pressed" 0 "Button not pressed" ;
VAL_ 2365445886 Joystick1XAxisDetentPosStatus 3 "Not Available" 2 "Error Indicator" 1 "In the Detent Position" 0 "Not in the Detent Position" ;
VAL_ 2365445886 Joystick1YAxisDetentPosStatus 3 "Not Available" 2 "Error Indicator" 1 "In the Detent Position" 0 "Not in the Detent Position" ;
VAL_ 2365445886 Jystck1YAxsLvrFrwrdPstvPosStatus 3 "Not Available" 2 "Error Indicator" 1 "On positive side of Neutral" 0 "Not on Positive side of Neutral" ;
VAL_ 2365445886 Jystck1YAxsLvrBckNgtivePosStatus 3 "Not Available" 2 "Error Indicator" 1 "On negative side of Neutral" 0 "Not on negative side of Neutral" ;
VAL_ 2365445886 Joystick1YAxisNeutralPosStatus 3 "Not Available" 2 "Error Indicator" 1 "In Neutral Position" 0 "Not in Neutral Position" ;
VAL_ 2365445886 Joystick1Button9PressedStatus 3 "Not Available" 2 "Error Indicator" 1 "Button pressed" 0 "Button not pressed" ;
VAL_ 2365445886 Joystick1Button10PressedStatus 3 "Not Available" 2 "Error Indicator" 1 "Button pressed" 0 "Button not pressed" ;
VAL_ 2365445886 Joystick1Button11PressedStatus 3 "Not Available" 2 "Error Indicator" 1 "Button pressed" 0 "Button not pressed" ;
VAL_ 2365445886 Joystick1Button12PressedStatus 3 "Not Available" 2 "Error Indicator" 1 "Button pressed" 0 "Button not pressed" ;
VAL_ 2365445886 Joystick1Button5PressedStatus 3 "Not Available" 2 "Error Indicator" 1 "Button pressed" 0 "Button not pressed" ;
VAL_ 2365445886 Joystick1Button6PressedStatus 3 "Not Available" 2 "Error Indicator" 1 "Button pressed" 0 "Button not pressed" ;
VAL_ 2365445886 Joystick1Button7PressedStatus 3 "Not Available" 2 "Error Indicator" 1 "Button pressed" 0 "Button not pressed" ;
VAL_ 2365445886 Joystick1Button8PressedStatus 3 "Not Available" 2 "Error Indicator" 1 "Button pressed" 0 "Button not pressed" ;
VAL_ 2365445886 Joystick1Button1PressedStatus 3 "Not Available" 2 "Error Indicator" 1 "Button pressed" 0 "Button not pressed" ;
VAL_ 2365445886 Joystick1Button2PressedStatus 3 "Not Available" 2 "Error Indicator" 1 "Button pressed" 0 "Button not pressed" ;
VAL_ 2365445886 Joystick1Button3PressedStatus 3 "Not Available" 2 "Error Indicator" 1 "Button pressed" 0 "Button not pressed" ;
VAL_ 2365445886 Joystick1Button4PressedStatus 3 "Not Available" 2 "Error Indicator" 1 "Button pressed" 0 "Button not pressed" ;
VAL_ 2365445886 Jystck1XAxsLvrRghtPstvePosStatus 3 "Not Available" 2 "Error Indicator" 1 "On positive side of Neutral" 0 "Not on Positive side of Neutral" ;
VAL_ 2365445886 Jystck1XAxsLvrLftNgtivePosStatus 3 "Not Available" 2 "Error Indicator" 1 "On negative side of Neutral" 0 "Not on negative side of Neutral" ;
VAL_ 2365445886 Joystick1XAxisNeutralPosStatus 3 "Not Available" 2 "Error Indicator" 1 "In Neutral Position" 0 "Not in Neutral Position" ;
VAL_ 2566847230 ParkingBrakeRedWarningSignal 3 "Take no action" 2 "Reserved" 1 "on" 0 "off" ;
VAL_ 2566847230 ParkBrakeReleaseInhibitStatus 3 "Unavailable" 2 "Error" 1 "ParkBrakeReleaseIsInhibited" 0 "ParkBrakeReleaseIsNotInhibited" ;
VAL_ 2566847230 ParkingBrakeActuator 3 "Not available" 2 "Error" 1 "Parking brake actuator active" 0 "Parking brake actuator inactive" ;
VAL_ 2560884478 DTCWarnLampSupportStatus 3 "Unavailable" 2 "Reserved" 1 "LampOn" 0 "LampOff" ;
VAL_ 2560884478 DTCWarnLampSupportFlash 3 "Unavailable" 2 "Reserved" 1 "FastFlash" 0 "SlowFlash" ;
VAL_ 2560884478 DTCStopLampSupportStatus 3 "Unavailable" 2 "Reserved" 1 "LampOn" 0 "LampOff" ;
VAL_ 2560884478 DTCStopLampSupportFlash 3 "Unavailable" 2 "Reserved" 1 "FastFlash" 0 "SlowFlash" ;
VAL_ 2560884478 DTCProtectLampSupportStatus 3 "Unavailable" 2 "Reserved" 1 "LampOn" 0 "LampOff" ;
VAL_ 2560884478 DTCProtectLampSupportFlash 3 "Unavailable" 2 "Reserved" 1 "FastFlash" 0 "SlowFlash" ;
VAL_ 2560884478 DTCMilSupportStatus 3 "Unavailable" 2 "ShortMI" 1 "LampOn" 0 "LampOff" ;
VAL_ 2560884478 DTCMilSupportFlash 3 "Unavailable" 2 "Class_C_DTC" 1 "FastFlash" 0 "SlowFlash" ;
VAL_ 2566736126 EngExhstGsOxygnSnsrClsdLpOprtnBn 15 "not supported" 4 "Closed loop but fault with at least one oxygen sensor  may be using single oxygen sensor for fuel control" 3 "Open loop  due to detected system fault" 2 "Open loop due to driving conditions eg power enrichment deceleration enleanment" 1 "Closed loop  using oxygen sensors as feedback for fuel control" 0 "Open loop  has not yet satisfied conditions to go closed loop" ;
VAL_ 2566736382 EngExhstGsOxygnSnsrClsdLpOprtnBn 15 "not supported" 4 "Closed loop but fault with at least one oxygen sensor  may be using single oxygen sensor for fuel control" 3 "Open loop  due to detected system fault" 2 "Open loop due to driving conditions eg power enrichment deceleration enleanment" 1 "Closed loop  using oxygen sensors as feedback for fuel control" 0 "Open loop  has not yet satisfied conditions to go closed loop" ;
VAL_ 2565874174 EngSpdSensor1TimingPatternStatus 3 "Not available" 2 "Error" 1 "OK" 0 "Not OK" ;
VAL_ 2565874174 EngSpdSensor2TimingPatternStatus 3 "Not available" 2 "Error" 1 "OK" 0 "Not OK" ;
VAL_ 2565874174 EngSpdSensor3TimingPatternStatus 3 "Not available" 2 "Error" 1 "OK" 0 "Not OK" ;
VAL_ 2432520958 EngCoolantThermostatMode 3 "dont care/reserved" 2 "reserved" 1 "position control mode used for service only" 0 "temperature control mode" ;
VAL_ 2566758398 Aftertreatment1AirEnableActuator 3 "not available" 2 "reserved for SAE assignment" 1 "active" 0 "not active" ;
VAL_ 2566758398 Aftertreatment1PurgeAirActuator 3 "not available" 2 "reserved for SAE assignment" 1 "active" 0 "not active" ;
VAL_ 2566758398 Aftrtrtmnt1AtmizationAirActuator 3 "not available" 2 "reserved for SAE assignment" 1 "active" 0 "not active" ;
VAL_ 2566758398 Aftertreatment1AirSystemRelay 3 "not available" 2 "reserved for SAE assignment" 1 "active" 0 "not active" ;
VAL_ 2566758910 Aftrtreatment1FuelEnableActuator 3 "not available" 2 "reserved for SAE assignment" 1 "active" 0 "not active" ;
VAL_ 2566758910 Aftrtreatment1RegenerationStatus 3 "not available" 2 "reserved for SAE assignment" 1 "active" 0 "not active" ;
VAL_ 2566758910 Aftertreatment1Ignt 3 "not available" 2 "reserved for SAE assignment" 1 "active" 0 "not active" ;
VAL_ 2566758910 Aftertreatment1FuelDrainActuator 3 "not available" 2 "reserved for SAE assignment" 1 "active" 0 "not active" ;
VAL_ 2566743550 Aftrtrtmnt1FlFlwDverterValveCtrl 3 "not available" 2 "reserved for SAE assignment" 1 "on" 0 "off" ;
VAL_ 2566743550 Aftertreatment1FuelPumpRelayCtrl 3 "not available" 2 "reserved for SAE assignment" 1 "on" 0 "off" ;
VAL_ 2565869310 NOxSensorATO1SelfdiagnosisStatus 7 "Not Supported" 5 "110 Reserved" 4 "NOx Sensor ATO1 Self Diagnosis not possible" 3 "NOx Sensor ATO1 Self Diagnosis aborted" 2 "NOx Sensor ATO1 Self Diagnosis Result Complete" 1 "NOx Sensor ATO1 Self Diagnosis active flag" 0 "Diagnosis not active" ;
VAL_ 2565869310 Aftrtrtmnt1IntkGsSnsorHeaterCtrl 3 "Heater off" 2 "Preheat 1" 1 "Preheat 2" 0 "Automatic" ;
VAL_ 2565869310 Aftrtrtmnt1IntkWdRngO2RdngStable 3 "Not available" 2 "Error" 1 "Stable" 0 "Not stable" ;
VAL_ 2565869310 Aftrtrtmnt1IntkeNOxReadingStable 3 "Not available" 2 "Error" 1 "Stable" 0 "Not stable" ;
VAL_ 2565869310 Aftrtrtmnt1IntakeGasSensorAtTemp 3 "Not available" 2 "Error" 1 "In range" 0 "Not in range" ;
VAL_ 2565869310 Aftrtrtmnt1IntkGsSnsrPowerStatus 3 "Not available" 2 "Error" 1 "In range" 0 "Not in range" ;
VAL_ 2631728894 AntitheftModifyPwdStates 3 "Notvalid" 2 "EmptyOfPwdsThsSttIndctsThtCmpnn" 1 "FullofPwds" 0 "OkThsSttIndctsThtRqWsSccssfllyP" ;
VAL_ 2631728894 AntitheftComponentStatusStates 3 "Not defined" 2 "Blocked" 1 "Locked" 0 "Unlocked" ;
VAL_ 2631728894 AntitheftPwdValidIndicator 3 "Not available" 2 "Error" 1 "Password is a validated password" 0 "Password is not a validated password" ;
VAL_ 2631728894 AntthftEncryptnSdPrsentIndicator 3 "Not available" 2 "Error" 1 "Random number is present" 0 "Random number is not present" ;
VAL_ 2631794430 AntitheftCmdStates 5 "Login" 4 "CheckStatus" 3 "LockorUnlock" 2 "ChangePassword" 1 "DeletePassword" 0 "AddPassword" ;
VAL_ 2631794430 AntitheftDesiredExitModeStates 3 "NotAvailable" 2 "Not defined" 1 "LockWhenKeyOff" 0 "LockUponOperatorRequest" ;
VAL_ 2631794430 AntthftEncryptionIndicatorStates 3 "NotAvailable" 2 "Not defined" 1 "EncryptedCodePresent" 0 "EncryptionSeedRequest" ;
VAL_ 2365478910 ElctrncShckAbsrbrCtrlMdLft_TgAxl 3 "Not available" 2 "Error" 1 "Normal operation dampers active" 0 "Normal operation dampers passive" ;
VAL_ 2365478910 ElctrncShckAbsrbrCtrlMdeRearAxle 3 "Not available" 2 "Error" 1 "Normal operation dampers active" 0 "Normal operation dampers passive" ;
VAL_ 2365478910 ElctrncShckAbsrbrCtrlMdFrontAxle 3 "Not available" 2 "Error" 1 "Normal operation dampers active" 0 "Normal operation dampers passive" ;
VAL_ 2560950014 FailureModeIdentifier1 31 "Not available" 19 "Received network data in error" 18 "Below normal (moderately severe)" 17 "Below normal (least severe)" 16 "Above normal (moderately severe)" 15 "Above normal (least severe)" 14 "Special intstructions" 13 "Out of calibration" 12 "Bad intelligent device" 11 "Root cause not known" 10 "Abnormal rate of change" 9 "Abnormal update rate" 8 "Abnormal frequency" 7 "Mechanical system not responding" 6 "Current above normal" 5 "Current below normal" 4 "Voltage below normal" 3 "Voltage above normal" 2 "Data erratic" 1 "Below normal (most severe)" 0 "Above normal (most severe)" ;
VAL_ 2565869566 NOxSensorATI1SelfdiagnosisStatus 7 "Not Supported" 5 "110 Reserved" 4 "NOx Sensor ATI1 Self Diagnosis not possible" 3 "NOx Sensor ATI1 Self Diagnosis aborted" 2 "NOx Sensor ATI1 Self Diagnosis Result Complete" 1 "NOx Sensor ATI1 Self Diagnosis active flag" 0 "Diagnosis not active" ;
VAL_ 2565869566 Aftrtrtmnt1OtltGsSnsorHeaterCtrl 3 "Heater off" 2 "Preheat 1" 1 "Preheat 2" 0 "Automatic" ;
VAL_ 2565869566 Aftrtrtmnt1OtltWdRngO2RdngStable 3 "Not available" 2 "Error" 1 "Stable" 0 "Not stable" ;
VAL_ 2565869566 Aftrtrtmnt1OtletNOxReadingStable 3 "Not available" 2 "Error" 1 "Stable" 0 "Not stable" ;
VAL_ 2565869566 Aftrtrtmnt1OutletGasSensorAtTemp 3 "Not available" 2 "Error" 1 "In range" 0 "Not in range" ;
VAL_ 2565869566 Aftrtrtmnt1OtltGsSnsrPowerStatus 3 "Not available" 2 "Error" 1 "In range" 0 "Not in range" ;
VAL_ 2566758142 Aftertreatment2AirEnableActuator 3 "not available" 2 "reserved for SAE assignment" 1 "active" 0 "not active" ;
VAL_ 2566758142 Aftertreatment2PurgeAirActuator 3 "not available" 2 "reserved for SAE assignment" 1 "active" 0 "not active" ;
VAL_ 2566758142 Aftrtrtmnt2AtmizationAirActuator 3 "not available" 2 "reserved for SAE assignment" 1 "active" 0 "not active" ;
VAL_ 2566758142 Aftertreatment2AirSystemRelay 3 "not available" 2 "reserved for SAE assignment" 1 "active" 0 "not active" ;
VAL_ 2566758654 Aftrtreatment2FuelEnableActuator 3 "not available" 2 "reserved for SAE assignment" 1 "active" 0 "not active" ;
VAL_ 2566758654 Aftrtreatment2RegenerationStatus 3 "not available" 2 "reserved for SAE assignment" 1 "active" 0 "not active" ;
VAL_ 2566758654 Aftertreatment2Ignt 3 "not available" 2 "reserved for SAE assignment" 1 "active" 0 "not active" ;
VAL_ 2566758654 Aftertreatment2FuelDrainActuator 3 "not available" 2 "reserved for SAE assignment" 1 "active" 0 "not active" ;
VAL_ 2565869822 NOxSensorATO2SelfdiagnosisStatus 7 "Not Supported" 5 "110 Reserved" 4 "NOx Sensor ATO2 Self Diagnosis not possible" 3 "NOx Sensor ATO2 Self Diagnosis aborted" 2 "NOx Sensor ATO2 Self Diagnosis Result Complete" 1 "NOx Sensor ATO2 Self Diagnosis active flag" 0 "Diagnosis not active" ;
VAL_ 2565869822 Aftrtrtmnt2IntkGsSnsorHeaterCtrl 3 "Heater off" 2 "Preheat 1" 1 "Preheat 2" 0 "Automatic" ;
VAL_ 2565869822 Aftrtrtmnt2IntkWdRngO2RdngStable 3 "Not available" 2 "Error" 1 "Stable" 0 "Not stable" ;
VAL_ 2565869822 Aftrtrtmnt2IntkeNOxReadingStable 3 "Not available" 2 "Error" 1 "Stable" 0 "Not stable" ;
VAL_ 2565869822 Aftrtrtmnt2IntakeGasSensorAtTemp 3 "Not available" 2 "Error" 1 "In range" 0 "Not in range" ;
VAL_ 2565869822 Aftrtrtmnt2IntkGsSnsrPowerStatus 3 "Not available" 2 "Error" 1 "In range" 0 "Not in range" ;
VAL_ 2565870078 NOxSensorATI2SelfdiagnosisStatus 7 "Not Supported" 5 "110 Reserved" 4 "NOx Sensor ATI2 Self Diagnosis not possible" 3 "NOx Sensor ATI2 Self Diagnosis aborted" 2 "NOx Sensor ATI2 Self Diagnosis Result Complete" 1 "NOx Sensor ATI2 Self Diagnosis active flag" 0 "Diagnosis not active" ;
VAL_ 2565870078 Aftrtrtmnt2OtltGsSnsorHeaterCtrl 3 "Heater off" 2 "Preheat 1" 1 "Preheat 2" 0 "Automatic" ;
VAL_ 2565870078 Aftrtrtmnt2OtltWdRngO2RdngStable 3 "Not available" 2 "Error" 1 "Stable" 0 "Not stable" ;
VAL_ 2565870078 Aftrtrtmnt2OtletNOxReadingStable 3 "Not available" 2 "Error" 1 "Stable" 0 "Not stable" ;
VAL_ 2565870078 Aftrtrtmnt2OutletGasSensorAtTemp 3 "Not available" 2 "Error" 1 "In range" 0 "Not in range" ;
VAL_ 2565870078 Aftrtrtmnt2OtltGsSnsrPowerStatus 3 "Not available" 2 "Error" 1 "In range" 0 "Not in range" ;
VAL_ 2365428478 EngEmergencyShutdownIndication 3 "Dont care / take no action" 2 "Reserved" 1 "On Shutdown Requested" 0 "Off No Shutdown Requested" ;
VAL_ 2365428478 EngControlledShutdownRq 3 "Dont care / take no action" 2 "Reserved" 1 "On Shutdown Requested" 0 "Off No Shutdown Requested" ;
VAL_ 2365428478 EngCoolantCirculatingPumpCtrl 3 "Dont care / take no action" 2 "Reserved" 1 "On" 0 "Off" ;
VAL_ 2365428478 EngBlock_CoolantPreheaterCtrl 3 "Unavailable" 2 "Reserved" 1 "On" 0 "Off" ;
VAL_ 2365428478 EngElctrclSystmPwrCnsrvationCtrl 3 "Unavailable" 2 "Reserved" 1 "On" 0 "Off" ;
VAL_ 2365428478 EngOilPreheaterCtrl 3 "Dont care / take no action" 2 "Reserved" 1 "On" 0 "Off" ;
VAL_ 2365428478 EngOilPrimingPumpCtrl 3 "unavailable" 2 "Reserved" 1 "On" 0 "Off" ;
VAL_ 2365428478 EngFuelShutoffValveLeakTestCtrl 3 "Dont care / take no action" 2 "Reserved" 1 "On test in process / test complete" 0 "Off reset / no test in process" ;
VAL_ 2365428478 EngFuelShutoff2Ctrl 3 "Dont care / take no action" 2 "Reserved" 1 "Closed no fuel supplied to engine" 0 "Open fuel supplied to engine" ;
VAL_ 2365428478 EngFuelShutoff1Ctrl 3 "Dont care / take no action" 2 "Reserved" 1 "Closed no fuel supplied to engine" 0 "Open fuel supplied to engine" ;
VAL_ 2365428478 EngFuelShutoffVentCtrl 3 "Dont care / take no action" 2 "Reserved" 1 "Open vent open" 0 "Closed vent closed" ;
VAL_ 2365428478 FuelPumpPrimerCtrl 3 "Unavailable" 2 "Reserved" 1 "Activate" 0 "Deactivate" ;
VAL_ 2362638078 MemoryLevelRq 15 "Dont care" 14 "Reserved" 13 "Store Memory level  5" 12 "Store Memory level  4" 11 "Store Memory level  3" 10 "Store Memory level  2" 9 "Store Memory level  1" 8 "reserved" 7 "reserved" 6 "reserved" 5 "Memory level 5 request" 4 "Memory level 4 request" 3 "Memory level 3 request" 2 "Memory level 2 request" 1 "Memory level 1 request" 0 "No memory level request" ;
VAL_ 2362638078 PrhbitAutomaticAirSuspensionCtrl 3 "Not available" 2 "Error indicator" 1 "Request prohibit automatic air suspension control" 0 "No request" ;
VAL_ 2362638078 SpeedDependentLevelCtrlRq 3 "Dont care/take no action" 2 "Reserved" 1 "Activate" 0 "Deactivate" ;
VAL_ 2362638078 AllowLevelCtrlDuringBrakingCmd 3 "Dont care/take no action" 2 "Reserved" 1 "Allow level control during braking" 0 "Disallow level control during braking normal operation" ;
VAL_ 2362638078 ProhibitAirSuspensionCtrl 3 "Not available" 2 "Error indicator" 1 "Request prohibit air suspension control" 0 "No request" ;
VAL_ 2362638078 KneelingCmdRearAxle 3 "Dont care/take no action" 2 "Reserved" 1 "Activate kneeling" 0 "Deactivate kneeling" ;
VAL_ 2362638078 KneelingCmdFrontAxle 3 "Dont care/take no action" 2 "Reserved" 1 "Activate kneeling" 0 "Deactivate kneeling" ;
VAL_ 2362638078 LiftAxle2PosCmd 3 "Dont care/take no action" 2 "Reserved" 1 "Lift axle position up / tag axle unladen" 0 "Lift axle position down / tag axle laden" ;
VAL_ 2362638078 LiftAxle1PosCmd 3 "Dont care/take no action" 2 "Reserved" 1 "Lift axle position up / tag axle unladen" 0 "Lift axle position down / tag axle laden" ;
VAL_ 2362638078 LevelCtrlModeRq 10 "1101    Not defined" 15 "Dont care/take no action" 14 "Reserved" 9 "Force to bumper level" 8 "Exhaust bellows" 7 "Traction help  load reduce ie reduce axle load of driven axle to normal load condition" 6 "Optimum traction 2 ie the pressure at the driven axle is controlled at a fixed value 2" 5 "Optimum traction 1 ie the pressure at the driven axle is controlled at a fixed value 1" 4 "Pressure ratio 2 ie the ratio between the pressures at the driven axle and at the third axle is controlled so that" 3 "Pressure ratio 1 ie the ratio between the pressures at the driven axle and at the third axle is controlled so that" 2 "Load fixing ie the driven axle is loaded to a value defined by the driver" 1 "Traction help load transfer ie the driven axle is loaded to a maximum value given by legislation or design" 0 "Normal operation ie the system performs a pure control of the vehicle height" ;
VAL_ 2362638078 NominalLevelRqRearAxle 10 "Lower Request Continuously lowering front axle as long as active" 15 "Dont care/take no action" 14 "Reserved" 9 "Raise Request Continuously raising front axle as long as active" 8 "Stop level changeie the level change in process shall be stopped immediately" 7 "Lower Levelie the lowest level to be controlled" 6 "Upper Levelie the highest level to be controlled" 5 "Customer Levelie a level to be defined by customer via parameter setting" 4 "Preset Levelie a level to be defined externally via CAN" 3 "Normal Level 3ie a level permitted for driving for example to lift the vehicle in case of offroad" 2 "Normal Level 2ie a level permitted for driving for example to lower the vehicle in case of high speed" 1 "Normal Level 1ie the level prescribed for normal driving given by design" 0 "No level request" ;
VAL_ 2362638078 NominalLevelRqFrontAxle 10 "Lower Request Continuously lowering front axle as long as active" 15 "Dont care/take no action" 14 "Reserved" 9 "Raise Request Continuously raising front axle as long as active" 8 "Stop level changeie the level change in process shall be stopped immediately" 7 "Lower Levelie the lowest level to be controlled" 6 "Upper Levelie the highest level to be controlled" 5 "Customer Levelie a level to be defined by customer via parameter setting" 4 "Preset Levelie a level to be defined externally via CAN" 3 "Normal Level 3ie a level permitted for driving for example to lift the vehicle in case of offroad" 2 "Normal Level 2ie a level permitted for driving for example to lower the vehicle in case of high speed" 1 "Normal Level 1ie the level prescribed for normal driving given by design" 0 "No level request" ;
VAL_ 2362638078 KneelingCtrlModeRq 3 "Dont care/take no action" 2 "Reserved" 1 "Manually actuated" 0 "Automatically actuated" ;
VAL_ 2362638078 KneelingRqRightSide 3 "Dont care/take no action" 2 "Reserved" 1 "Kneeling request" 0 "No kneeling request" ;
VAL_ 2362638078 KneelingRqLeftSide 3 "Dont care/take no action" 2 "Reserved" 1 "Kneeling request" 0 "No kneeling request" ;
VAL_ 2362638078 AutomaticTractionHelp 3 "Dont care" 2 "Reserved" 1 "Enable automatic traction help" 0 "Disable automatic traction help" ;
